VERSION ""

NS_ :

BS_:

BU_: PowertrainControlModule AtmosphericSensor SafetyRestraintSystem2 Aftertreatment_2_GasOutlet Aftertreatment_2_GasIntake DieselParticulateFilterControl Turbocharger SafetyRestraintSystem1 CabDisplay2 Aftertreatment_1_GasOutlet Aftertreatment_1_GasIntake OnBoardDataLogger OffBoardDiagnosticTool2 OffBoardDiagnosticTool1 FileServer ParkingBrakeController SeatController2 FanDriveController SteeringColumnUnit CommunicationUnitRadio CommunicationUnitSatellite CommunicationUnitCellular PropulsionBatteryCharger ChassisController2 ChassisController1 EngineValveControl AuxiliaryHeater2 AuxiliaryHeater1 ClutchUnit RampControl InformationSystem1 SuspensionSystemController2 OilSensor VehicleDynamicStability ExhaustEmissionController TransmissionDisplay2 TransmissionDisplay1 ClimateControl2 WaterPumpController RearAxleSteeringController LightingOperatorControl SeatController1 IgnitionController2 IgnitionController1 TirePressureController CabController2 CabController1 PneumaticSystemController SuspensionSystemController1 HydraulicPumpController EnduranceBrakingSystem RetarderExhaustEngine2 OnBoardDiagnosticUnit HeadwayController RetarderExhaustEngine1 CabDisplay1 ManagementComputer VirtualTerminal OffVehicleGateway PowerTakeOffFront HitchControl AuxiliaryValveControl BodyController TractorTrailerBridge1 StarterSystem ElectricalSystem VehicleSecurity VehicleNavigation AerodynamicControl ElectricalChargingSystem ClimateControl1 TripRecorder InstrumentCluster SuspensionDriveAxle2 SuspensionDriveAxle1 SuspensionSteerAxle SteeringController FuelSystem CruiseControl RetarderDriveline RetarderEngine BrakesDriveAxle2 BrakesDriveAxle1 BrakesSystemController BrakesSteerAxle AxleDrive2 AxleDrive1 AxleSteering PowerTakeOff ShiftConsoleSecondary ShiftConsolePrimary Transmission2 Transmission1 Engine2 Engine1

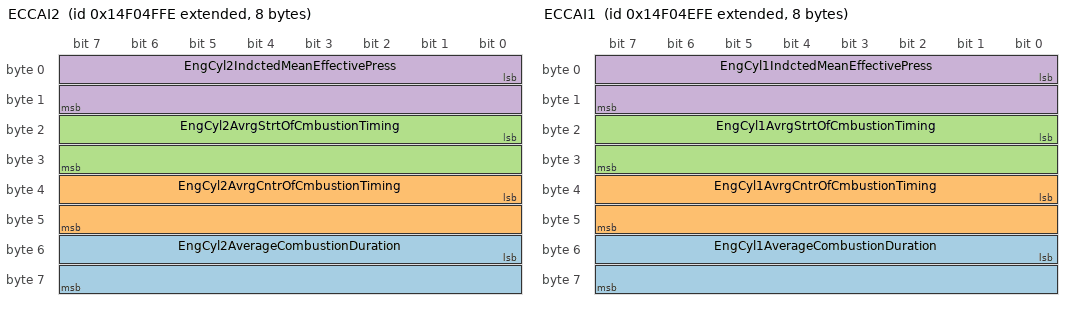
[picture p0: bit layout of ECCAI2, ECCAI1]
BO_ 2498777086 ECCAI2: 8 Vector__XXX
 SG_ EngCyl2AverageCombustionDuration : 48|16@1+ (0.0078125,0) [0|501.9921875] "deg" Vector__XXX
 SG_ EngCyl2AvrgCntrOfCmbustionTiming : 32|16@1+ (0.0078125,-250) [-250|251.9921875] "deg" Vector__XXX
 SG_ EngCyl2AvrgStrtOfCmbustionTiming : 16|16@1+ (0.0078125,-250) [-250|251.9921875] "deg" Vector__XXX
 SG_ EngCyl2IndctedMeanEffectivePress : 0|16@1+ (0.0001220703125,-1) [-1|6.8436279296875] "MPa" Vector__XXX

BO_ 2498776830 ECCAI1: 8 Vector__XXX
 SG_ EngCyl1AverageCombustionDuration : 48|16@1+ (0.0078125,0) [0|501.9921875] "deg" Vector__XXX
 SG_ EngCyl1AvrgCntrOfCmbustionTiming : 32|16@1+ (0.0078125,-250) [-250|251.9921875] "deg" Vector__XXX
 SG_ EngCyl1AvrgStrtOfCmbustionTiming : 16|16@1+ (0.0078125,-250) [-250|251.9921875] "deg" Vector__XXX
 SG_ EngCyl1IndctedMeanEffectivePress : 0|16@1+ (0.0001220703125,-1) [-1|6.8436279296875] "MPa" Vector__XXX

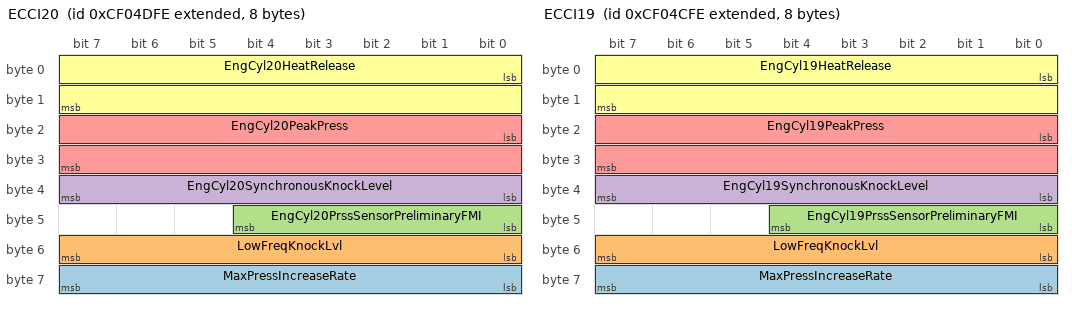
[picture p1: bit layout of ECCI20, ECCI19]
BO_ 2364558846 ECCI20: 8 Vector__XXX
 SG_ MaxPressIncreaseRate : 56|8@1+ (16,0) [0|4000] "kPa/deg" Vector__XXX
 SG_ LowFreqKnockLvl : 48|8@1+ (1,0) [0|250] "%" Vector__XXX
 SG_ EngCyl20PrssSensorPreliminaryFMI : 40|5@1+ (1,0) [0|31] "" Vector__XXX
 SG_ EngCyl20SynchronousKnockLevel : 32|8@1+ (1,0) [0|250] "%" Vector__XXX
 SG_ EngCyl20PeakPress : 16|16@1+ (0.0009765625,0) [0|62.7490234375] "MPa" Vector__XXX
 SG_ EngCyl20HeatRelease : 0|16@1+ (0.0001220703125,-1) [-1|6.8436279296875] "kJ/l" Vector__XXX

BO_ 2364558590 ECCI19: 8 Vector__XXX
 SG_ MaxPressIncreaseRate : 56|8@1+ (16,0) [0|4000] "kPa/deg" Vector__XXX
 SG_ LowFreqKnockLvl : 48|8@1+ (1,0) [0|250] "%" Vector__XXX
 SG_ EngCyl19PrssSensorPreliminaryFMI : 40|5@1+ (1,0) [0|31] "" Vector__XXX
 SG_ EngCyl19SynchronousKnockLevel : 32|8@1+ (1,0) [0|250] "%" Vector__XXX
 SG_ EngCyl19PeakPress : 16|16@1+ (0.0009765625,0) [0|62.7490234375] "MPa" Vector__XXX
 SG_ EngCyl19HeatRelease : 0|16@1+ (0.0001220703125,-1) [-1|6.8436279296875] "kJ/l" Vector__XXX

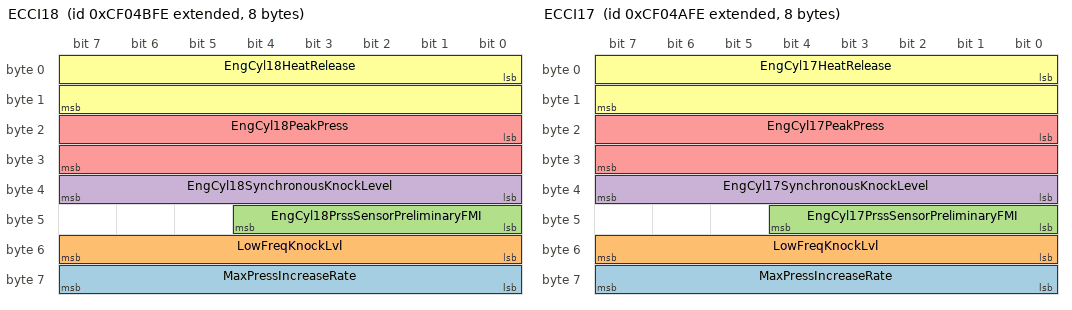
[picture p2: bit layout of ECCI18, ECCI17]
BO_ 2364558334 ECCI18: 8 Vector__XXX
 SG_ MaxPressIncreaseRate : 56|8@1+ (16,0) [0|4000] "kPa/deg" Vector__XXX
 SG_ LowFreqKnockLvl : 48|8@1+ (1,0) [0|250] "%" Vector__XXX
 SG_ EngCyl18PrssSensorPreliminaryFMI : 40|5@1+ (1,0) [0|31] "" Vector__XXX
 SG_ EngCyl18SynchronousKnockLevel : 32|8@1+ (1,0) [0|250] "%" Vector__XXX
 SG_ EngCyl18PeakPress : 16|16@1+ (0.0009765625,0) [0|62.7490234375] "MPa" Vector__XXX
 SG_ EngCyl18HeatRelease : 0|16@1+ (0.0001220703125,-1) [-1|6.8436279296875] "kJ/l" Vector__XXX

BO_ 2364558078 ECCI17: 8 Vector__XXX
 SG_ MaxPressIncreaseRate : 56|8@1+ (16,0) [0|4000] "kPa/deg" Vector__XXX
 SG_ LowFreqKnockLvl : 48|8@1+ (1,0) [0|250] "%" Vector__XXX
 SG_ EngCyl17PrssSensorPreliminaryFMI : 40|5@1+ (1,0) [0|31] "" Vector__XXX
 SG_ EngCyl17SynchronousKnockLevel : 32|8@1+ (1,0) [0|250] "%" Vector__XXX
 SG_ EngCyl17PeakPress : 16|16@1+ (0.0009765625,0) [0|62.7490234375] "MPa" Vector__XXX
 SG_ EngCyl17HeatRelease : 0|16@1+ (0.0001220703125,-1) [-1|6.8436279296875] "kJ/l" Vector__XXX

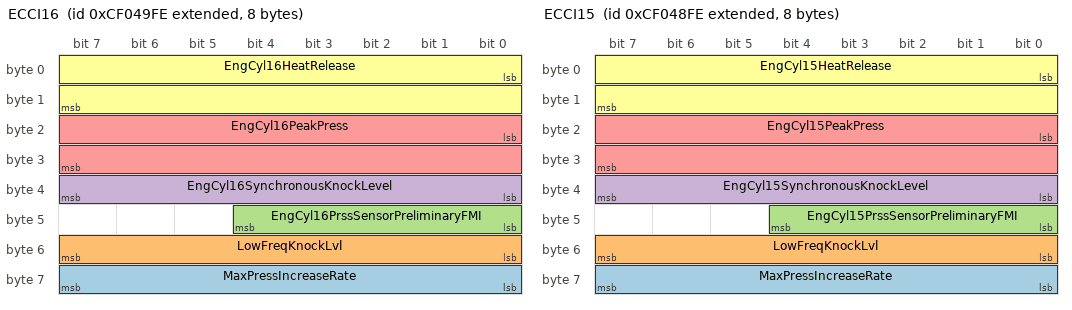
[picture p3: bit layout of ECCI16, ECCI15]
BO_ 2364557822 ECCI16: 8 Vector__XXX
 SG_ MaxPressIncreaseRate : 56|8@1+ (16,0) [0|4000] "kPa/deg" Vector__XXX
 SG_ LowFreqKnockLvl : 48|8@1+ (1,0) [0|250] "%" Vector__XXX
 SG_ EngCyl16PrssSensorPreliminaryFMI : 40|5@1+ (1,0) [0|31] "" Vector__XXX
 SG_ EngCyl16SynchronousKnockLevel : 32|8@1+ (1,0) [0|250] "%" Vector__XXX
 SG_ EngCyl16PeakPress : 16|16@1+ (0.0009765625,0) [0|62.7490234375] "MPa" Vector__XXX
 SG_ EngCyl16HeatRelease : 0|16@1+ (0.0001220703125,-1) [-1|6.8436279296875] "kJ/l" Vector__XXX

BO_ 2364557566 ECCI15: 8 Vector__XXX
 SG_ MaxPressIncreaseRate : 56|8@1+ (16,0) [0|4000] "kPa/deg" Vector__XXX
 SG_ LowFreqKnockLvl : 48|8@1+ (1,0) [0|250] "%" Vector__XXX
 SG_ EngCyl15PrssSensorPreliminaryFMI : 40|5@1+ (1,0) [0|31] "" Vector__XXX
 SG_ EngCyl15SynchronousKnockLevel : 32|8@1+ (1,0) [0|250] "%" Vector__XXX
 SG_ EngCyl15PeakPress : 16|16@1+ (0.0009765625,0) [0|62.7490234375] "MPa" Vector__XXX
 SG_ EngCyl15HeatRelease : 0|16@1+ (0.0001220703125,-1) [-1|6.8436279296875] "kJ/l" Vector__XXX

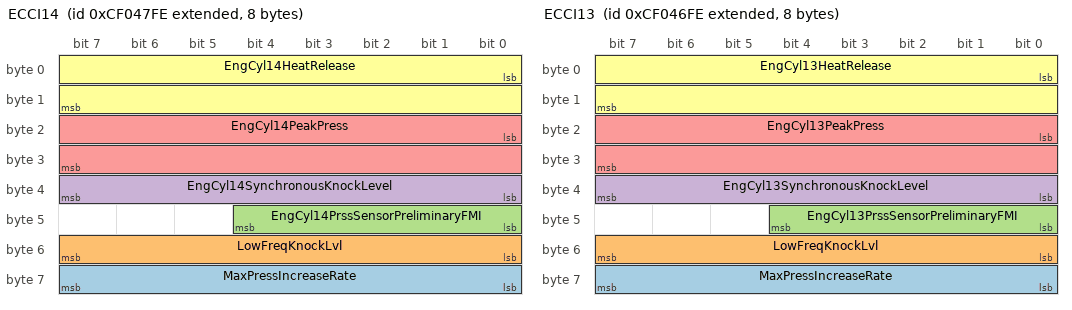
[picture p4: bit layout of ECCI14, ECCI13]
BO_ 2364557310 ECCI14: 8 Vector__XXX
 SG_ MaxPressIncreaseRate : 56|8@1+ (16,0) [0|4000] "kPa/deg" Vector__XXX
 SG_ LowFreqKnockLvl : 48|8@1+ (1,0) [0|250] "%" Vector__XXX
 SG_ EngCyl14PrssSensorPreliminaryFMI : 40|5@1+ (1,0) [0|31] "" Vector__XXX
 SG_ EngCyl14SynchronousKnockLevel : 32|8@1+ (1,0) [0|250] "%" Vector__XXX
 SG_ EngCyl14PeakPress : 16|16@1+ (0.0009765625,0) [0|62.7490234375] "MPa" Vector__XXX
 SG_ EngCyl14HeatRelease : 0|16@1+ (0.0001220703125,-1) [-1|6.8436279296875] "kJ/l" Vector__XXX

BO_ 2364557054 ECCI13: 8 Vector__XXX
 SG_ MaxPressIncreaseRate : 56|8@1+ (16,0) [0|4000] "kPa/deg" Vector__XXX
 SG_ LowFreqKnockLvl : 48|8@1+ (1,0) [0|250] "%" Vector__XXX
 SG_ EngCyl13PrssSensorPreliminaryFMI : 40|5@1+ (1,0) [0|31] "" Vector__XXX
 SG_ EngCyl13SynchronousKnockLevel : 32|8@1+ (1,0) [0|250] "%" Vector__XXX
 SG_ EngCyl13PeakPress : 16|16@1+ (0.0009765625,0) [0|62.7490234375] "MPa" Vector__XXX
 SG_ EngCyl13HeatRelease : 0|16@1+ (0.0001220703125,-1) [-1|6.8436279296875] "kJ/l" Vector__XXX

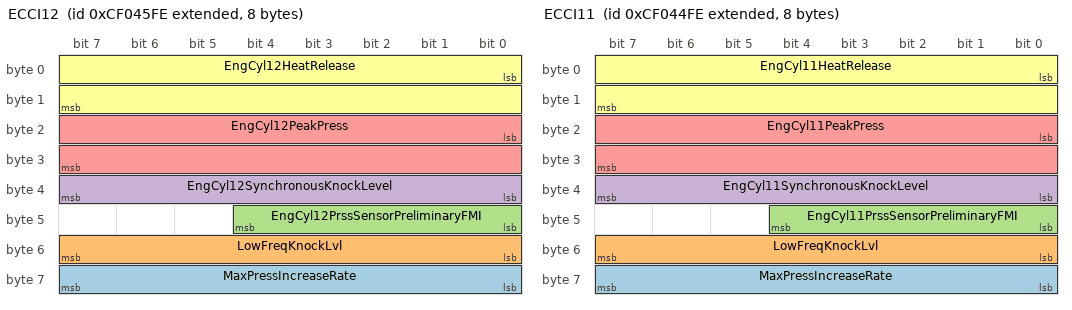
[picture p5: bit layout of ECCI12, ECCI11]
BO_ 2364556798 ECCI12: 8 Vector__XXX
 SG_ MaxPressIncreaseRate : 56|8@1+ (16,0) [0|4000] "kPa/deg" Vector__XXX
 SG_ LowFreqKnockLvl : 48|8@1+ (1,0) [0|250] "%" Vector__XXX
 SG_ EngCyl12PrssSensorPreliminaryFMI : 40|5@1+ (1,0) [0|31] "" Vector__XXX
 SG_ EngCyl12SynchronousKnockLevel : 32|8@1+ (1,0) [0|250] "%" Vector__XXX
 SG_ EngCyl12PeakPress : 16|16@1+ (0.0009765625,0) [0|62.7490234375] "MPa" Vector__XXX
 SG_ EngCyl12HeatRelease : 0|16@1+ (0.0001220703125,-1) [-1|6.8436279296875] "kJ/l" Vector__XXX

BO_ 2364556542 ECCI11: 8 Vector__XXX
 SG_ MaxPressIncreaseRate : 56|8@1+ (16,0) [0|4000] "kPa/deg" Vector__XXX
 SG_ LowFreqKnockLvl : 48|8@1+ (1,0) [0|250] "%" Vector__XXX
 SG_ EngCyl11PrssSensorPreliminaryFMI : 40|5@1+ (1,0) [0|31] "" Vector__XXX
 SG_ EngCyl11SynchronousKnockLevel : 32|8@1+ (1,0) [0|250] "%" Vector__XXX
 SG_ EngCyl11PeakPress : 16|16@1+ (0.0009765625,0) [0|62.7490234375] "MPa" Vector__XXX
 SG_ EngCyl11HeatRelease : 0|16@1+ (0.0001220703125,-1) [-1|6.8436279296875] "kJ/l" Vector__XXX

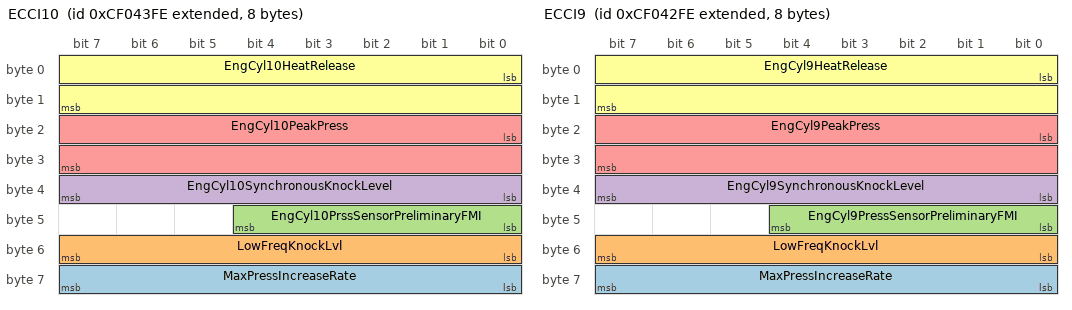
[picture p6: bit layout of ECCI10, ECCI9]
BO_ 2364556286 ECCI10: 8 Vector__XXX
 SG_ MaxPressIncreaseRate : 56|8@1+ (16,0) [0|4000] "kPa/deg" Vector__XXX
 SG_ LowFreqKnockLvl : 48|8@1+ (1,0) [0|250] "%" Vector__XXX
 SG_ EngCyl10PrssSensorPreliminaryFMI : 40|5@1+ (1,0) [0|31] "" Vector__XXX
 SG_ EngCyl10SynchronousKnockLevel : 32|8@1+ (1,0) [0|250] "%" Vector__XXX
 SG_ EngCyl10PeakPress : 16|16@1+ (0.0009765625,0) [0|62.7490234375] "MPa" Vector__XXX
 SG_ EngCyl10HeatRelease : 0|16@1+ (0.0001220703125,-1) [-1|6.8436279296875] "kJ/l" Vector__XXX

BO_ 2364556030 ECCI9: 8 Vector__XXX
 SG_ MaxPressIncreaseRate : 56|8@1+ (16,0) [0|4000] "kPa/deg" Vector__XXX
 SG_ LowFreqKnockLvl : 48|8@1+ (1,0) [0|250] "%" Vector__XXX
 SG_ EngCyl9PressSensorPreliminaryFMI : 40|5@1+ (1,0) [0|31] "" Vector__XXX
 SG_ EngCyl9SynchronousKnockLevel : 32|8@1+ (1,0) [0|250] "%" Vector__XXX
 SG_ EngCyl9PeakPress : 16|16@1+ (0.0009765625,0) [0|62.7490234375] "MPa" Vector__XXX
 SG_ EngCyl9HeatRelease : 0|16@1+ (0.0001220703125,-1) [-1|6.8436279296875] "kJ/l" Vector__XXX

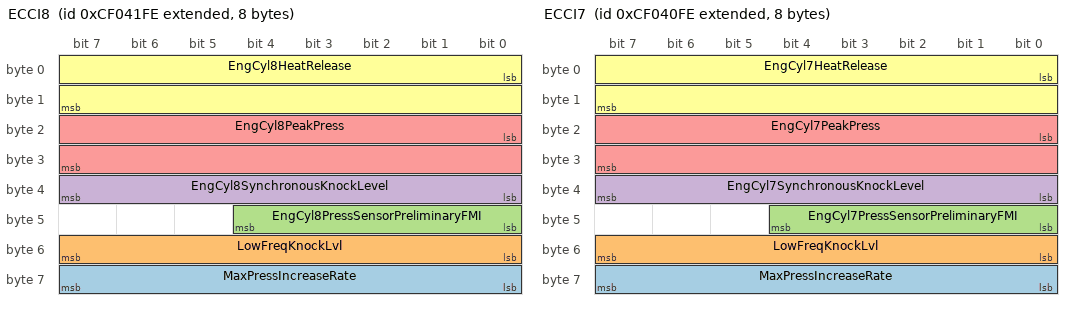
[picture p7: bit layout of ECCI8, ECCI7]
BO_ 2364555774 ECCI8: 8 Vector__XXX
 SG_ MaxPressIncreaseRate : 56|8@1+ (16,0) [0|4000] "kPa/deg" Vector__XXX
 SG_ LowFreqKnockLvl : 48|8@1+ (1,0) [0|250] "%" Vector__XXX
 SG_ EngCyl8PressSensorPreliminaryFMI : 40|5@1+ (1,0) [0|31] "" Vector__XXX
 SG_ EngCyl8SynchronousKnockLevel : 32|8@1+ (1,0) [0|250] "%" Vector__XXX
 SG_ EngCyl8PeakPress : 16|16@1+ (0.0009765625,0) [0|62.7490234375] "MPa" Vector__XXX
 SG_ EngCyl8HeatRelease : 0|16@1+ (0.0001220703125,-1) [-1|6.8436279296875] "kJ/l" Vector__XXX

BO_ 2364555518 ECCI7: 8 Vector__XXX
 SG_ MaxPressIncreaseRate : 56|8@1+ (16,0) [0|4000] "kPa/deg" Vector__XXX
 SG_ LowFreqKnockLvl : 48|8@1+ (1,0) [0|250] "%" Vector__XXX
 SG_ EngCyl7PressSensorPreliminaryFMI : 40|5@1+ (1,0) [0|31] "" Vector__XXX
 SG_ EngCyl7SynchronousKnockLevel : 32|8@1+ (1,0) [0|250] "%" Vector__XXX
 SG_ EngCyl7PeakPress : 16|16@1+ (0.0009765625,0) [0|62.7490234375] "MPa" Vector__XXX
 SG_ EngCyl7HeatRelease : 0|16@1+ (0.0001220703125,-1) [-1|6.8436279296875] "kJ/l" Vector__XXX

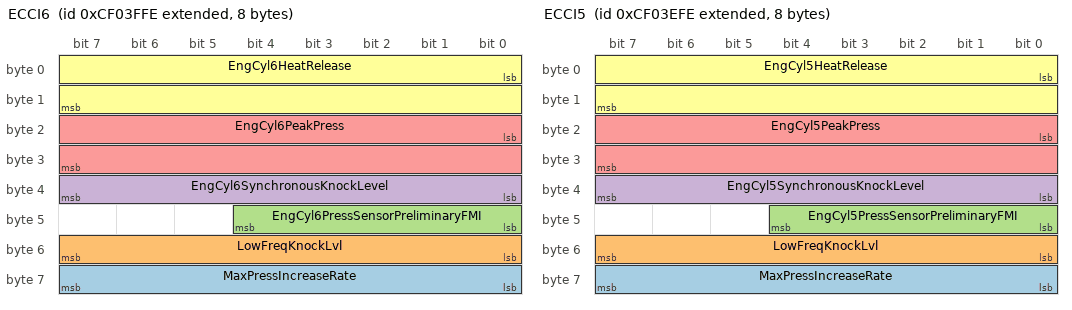
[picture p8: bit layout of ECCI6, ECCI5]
BO_ 2364555262 ECCI6: 8 Vector__XXX
 SG_ MaxPressIncreaseRate : 56|8@1+ (16,0) [0|4000] "kPa/deg" Vector__XXX
 SG_ LowFreqKnockLvl : 48|8@1+ (1,0) [0|250] "%" Vector__XXX
 SG_ EngCyl6PressSensorPreliminaryFMI : 40|5@1+ (1,0) [0|31] "" Vector__XXX
 SG_ EngCyl6SynchronousKnockLevel : 32|8@1+ (1,0) [0|250] "%" Vector__XXX
 SG_ EngCyl6PeakPress : 16|16@1+ (0.0009765625,0) [0|62.7490234375] "MPa" Vector__XXX
 SG_ EngCyl6HeatRelease : 0|16@1+ (0.0001220703125,-1) [-1|6.8436279296875] "kJ/l" Vector__XXX

BO_ 2364555006 ECCI5: 8 Vector__XXX
 SG_ MaxPressIncreaseRate : 56|8@1+ (16,0) [0|4000] "kPa/deg" Vector__XXX
 SG_ LowFreqKnockLvl : 48|8@1+ (1,0) [0|250] "%" Vector__XXX
 SG_ EngCyl5PressSensorPreliminaryFMI : 40|5@1+ (1,0) [0|31] "" Vector__XXX
 SG_ EngCyl5SynchronousKnockLevel : 32|8@1+ (1,0) [0|250] "%" Vector__XXX
 SG_ EngCyl5PeakPress : 16|16@1+ (0.0009765625,0) [0|62.7490234375] "MPa" Vector__XXX
 SG_ EngCyl5HeatRelease : 0|16@1+ (0.0001220703125,-1) [-1|6.8436279296875] "kJ/l" Vector__XXX

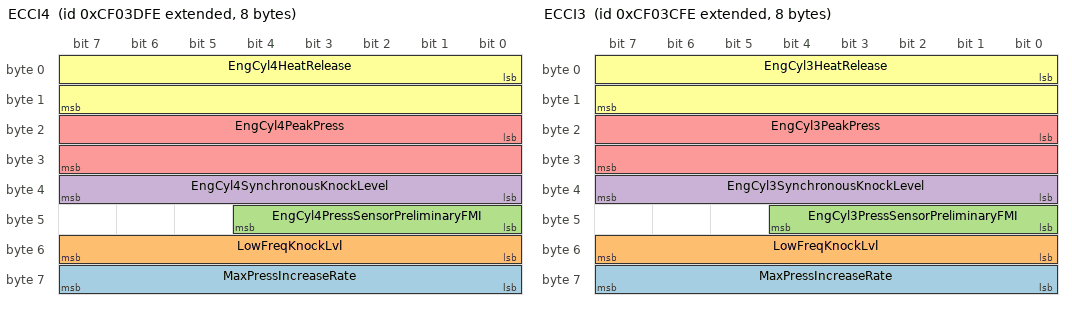
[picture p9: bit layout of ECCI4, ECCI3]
BO_ 2364554750 ECCI4: 8 Vector__XXX
 SG_ MaxPressIncreaseRate : 56|8@1+ (16,0) [0|4000] "kPa/deg" Vector__XXX
 SG_ LowFreqKnockLvl : 48|8@1+ (1,0) [0|250] "%" Vector__XXX
 SG_ EngCyl4PressSensorPreliminaryFMI : 40|5@1+ (1,0) [0|31] "" Vector__XXX
 SG_ EngCyl4SynchronousKnockLevel : 32|8@1+ (1,0) [0|250] "%" Vector__XXX
 SG_ EngCyl4PeakPress : 16|16@1+ (0.0009765625,0) [0|62.7490234375] "MPa" Vector__XXX
 SG_ EngCyl4HeatRelease : 0|16@1+ (0.0001220703125,-1) [-1|6.8436279296875] "kJ/l" Vector__XXX

BO_ 2364554494 ECCI3: 8 Vector__XXX
 SG_ MaxPressIncreaseRate : 56|8@1+ (16,0) [0|4000] "kPa/deg" Vector__XXX
 SG_ LowFreqKnockLvl : 48|8@1+ (1,0) [0|250] "%" Vector__XXX
 SG_ EngCyl3PressSensorPreliminaryFMI : 40|5@1+ (1,0) [0|31] "" Vector__XXX
 SG_ EngCyl3SynchronousKnockLevel : 32|8@1+ (1,0) [0|250] "%" Vector__XXX
 SG_ EngCyl3PeakPress : 16|16@1+ (0.0009765625,0) [0|62.7490234375] "MPa" Vector__XXX
 SG_ EngCyl3HeatRelease : 0|16@1+ (0.0001220703125,-1) [-1|6.8436279296875] "kJ/l" Vector__XXX

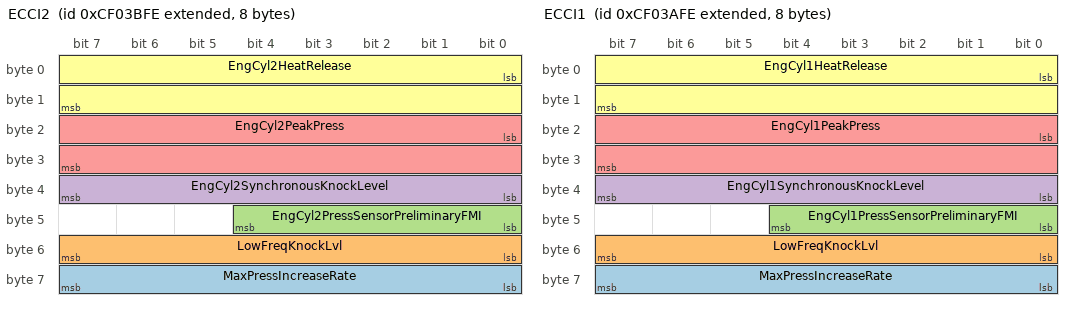
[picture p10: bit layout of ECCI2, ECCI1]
BO_ 2364554238 ECCI2: 8 Vector__XXX
 SG_ MaxPressIncreaseRate : 56|8@1+ (16,0) [0|4000] "kPa/deg" Vector__XXX
 SG_ LowFreqKnockLvl : 48|8@1+ (1,0) [0|250] "%" Vector__XXX
 SG_ EngCyl2PressSensorPreliminaryFMI : 40|5@1+ (1,0) [0|31] "" Vector__XXX
 SG_ EngCyl2SynchronousKnockLevel : 32|8@1+ (1,0) [0|250] "%" Vector__XXX
 SG_ EngCyl2PeakPress : 16|16@1+ (0.0009765625,0) [0|62.7490234375] "MPa" Vector__XXX
 SG_ EngCyl2HeatRelease : 0|16@1+ (0.0001220703125,-1) [-1|6.8436279296875] "kJ/l" Vector__XXX

BO_ 2364553982 ECCI1: 8 Vector__XXX
 SG_ MaxPressIncreaseRate : 56|8@1+ (16,0) [0|4000] "kPa/deg" Vector__XXX
 SG_ LowFreqKnockLvl : 48|8@1+ (1,0) [0|250] "%" Vector__XXX
 SG_ EngCyl1PressSensorPreliminaryFMI : 40|5@1+ (1,0) [0|31] "" Vector__XXX
 SG_ EngCyl1SynchronousKnockLevel : 32|8@1+ (1,0) [0|100] "%" Vector__XXX
 SG_ EngCyl1PeakPress : 16|16@1+ (0.0009765625,0) [0|62.7490234375] "MPa" Vector__XXX
 SG_ EngCyl1HeatRelease : 0|16@1+ (0.0001220703125,-1) [-1|6.8436279296875] "kJ/l" Vector__XXX

BO_ 2364553726 EASI: 8 Vector__XXX
 SG_ FuelSys2TotalInMassAirFlowRate : 32|16@1+ (0.0009765625,0) [0|62.7490234375] "kg/s" Vector__XXX
 SG_ EngTotalIntakeMassAirFlowRate : 16|16@1+ (0.0009765625,0) [0|62.7490234375] "kg/s" Vector__XXX
 SG_ EngDesiredAirFuelRatio : 0|16@1+ (0.001,0) [0|64.255] "" Vector__XXX

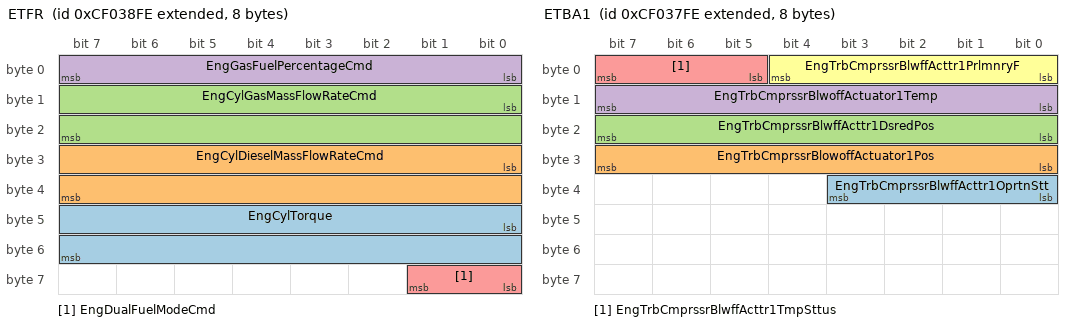
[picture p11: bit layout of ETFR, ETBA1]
BO_ 2364553470 ETFR: 8 Vector__XXX
 SG_ EngCylTorque : 40|16@1+ (1,0) [0|64255] "Nm" Vector__XXX
 SG_ EngCylDieselMassFlowRateCmd : 24|16@1+ (6.103515625E-005,0) [0|3.92181396484375] "kg/s" Vector__XXX
 SG_ EngCylGasMassFlowRateCmd : 8|16@1+ (6.103515625E-005,0) [0|3.92181396484375] "kg/s" Vector__XXX
 SG_ EngGasFuelPercentageCmd : 0|8@1+ (0.5,0) [0|100] "%" Vector__XXX
 SG_ EngDualFuelModeCmd : 56|2@1+ (1,0) [0|100] "" Vector__XXX

BO_ 2364553214 ETBA1: 8 Vector__XXX
 SG_ EngTrbCmprssrBlwffActtr1OprtnStt : 32|4@1+ (1,0) [0|15] "" Vector__XXX
 SG_ EngTrbCmprssrBlowoffActuator1Pos : 24|8@1+ (0.4,0) [0|100] "%" Vector__XXX
 SG_ EngTrbCmprssrBlwffActtr1DsredPos : 16|8@1+ (0.4,0) [0|100] "%" Vector__XXX
 SG_ EngTrbCmprssrBlwoffActuator1Temp : 8|8@1+ (1,-40) [-40|210] "°C" Vector__XXX
 SG_ EngTrbCmprssrBlwffActtr1TmpSttus : 5|3@1+ (1,0) [0|7] "" Vector__XXX
 SG_ EngTrbCmprssrBlwffActtr1PrlmnryF : 0|5@1+ (1,0) [0|31] "" Vector__XXX

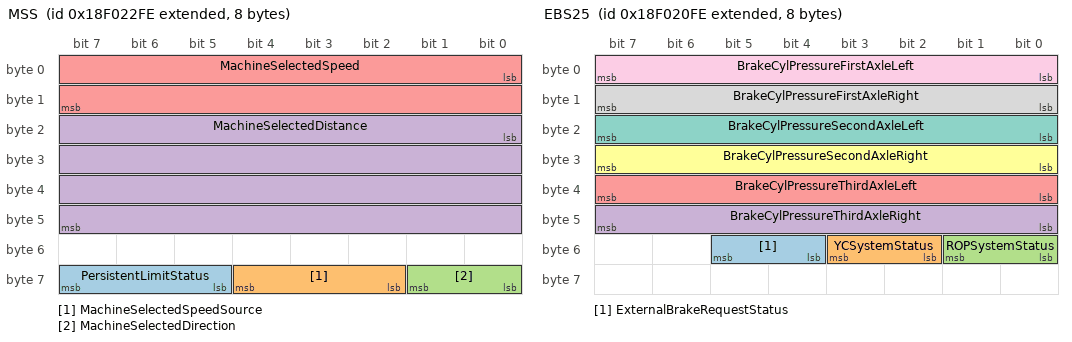
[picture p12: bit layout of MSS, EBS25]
BO_ 2565874430 MSS: 8 Vector__XXX
 SG_ PersistentLimitStatus : 61|3@1+ (1,0) [0|0] "" Vector__XXX
 SG_ MachineSelectedSpeedSource : 58|3@1+ (1,0) [0|0] "" Vector__XXX
 SG_ MachineSelectedDirection : 56|2@1+ (1,0) [0|0] "" Vector__XXX
 SG_ MachineSelectedDistance : 16|32@1+ (1,0) [0|0] "" Vector__XXX
 SG_ MachineSelectedSpeed : 0|16@1+ (1,0) [0|0] "" Vector__XXX

BO_ 2565873918 EBS25: 8 Vector__XXX
 SG_ ExternalBrakeRequestStatus : 52|2@1+ (1,0) [0|3] "" Vector__XXX
 SG_ YCSystemStatus : 50|2@1+ (1,0) [0|3] "" Vector__XXX
 SG_ ROPSystemStatus : 48|2@1+ (1,0) [0|3] "" Vector__XXX
 SG_ BrakeCylPressureThirdAxleRight : 40|8@1+ (5,0) [0|1250] "kPa" Vector__XXX
 SG_ BrakeCylPressureThirdAxleLeft : 32|8@1+ (5,0) [0|1250] "kPa" Vector__XXX
 SG_ BrakeCylPressureSecondAxleRight : 24|8@1+ (5,0) [0|1250] "kPa" Vector__XXX
 SG_ BrakeCylPressureSecondAxleLeft : 16|8@1+ (5,0) [0|1250] "kPa" Vector__XXX
 SG_ BrakeCylPressureFirstAxleRight : 8|8@1+ (5,0) [0|1250] "kPa" Vector__XXX
 SG_ BrakeCylPressureFirstAxleLeft : 0|8@1+ (5,0) [0|1250] "kPa" Vector__XXX

BO_ 2565873662 EBS26: 8 Vector__XXX
 SG_ WheelSpeedFirstAxleLeftRight : 16|16@1+ (0.00390625,0) [0|250] "km/h" Vector__XXX
 SG_ WheelSpeedFirstAxleLeft : 0|16@1+ (0.00390625,0) [0|250] "km/h" Vector__XXX

BO_ 2364546814 GC2: 8 Vector__XXX
 SG_ EngLoadSetpointReq : 24|16@1+ (0.5,0) [0|32127.5] "kW" Vector__XXX
 SG_ EngSelfInducedDerateInh : 16|2@1+ (1,0) [0|3] "" Vector__XXX
 SG_ GeneratorGoverningBias : 0|16@1+ (0.004,-125) [-125|125] "%" Vector__XXX

BO_ 2565872638 GPM17: 8 Vector__XXX
 SG_ TrailerWorkLights : 42|2@1+ (1,0) [0|3] "" Vector__XXX
 SG_ TrailerInteriorLights : 40|2@1+ (1,0) [0|3] "" Vector__XXX
 SG_ TrailerRotatingIndentLights : 38|2@1+ (1,0) [0|3] "" Vector__XXX
 SG_ TrailerRearWarningLights : 36|2@1+ (1,0) [0|3] "" Vector__XXX
 SG_ TrailerRightRearRegPlateLights : 34|2@1+ (1,0) [0|3] "" Vector__XXX
 SG_ TrailerLeftRearRegPlateLights : 32|2@1+ (1,0) [0|3] "" Vector__XXX
 SG_ TrailerRightCornerMarkerLights : 30|2@1+ (1,0) [0|3] "" Vector__XXX
 SG_ TrailerLeftCornerMarkerLights : 28|2@1+ (1,0) [0|3] "" Vector__XXX
 SG_ TrailerRightRearWidthIndLights : 26|2@1+ (1,0) [0|3] "" Vector__XXX
 SG_ TrailerLeftRearWidthIndLights : 24|2@1+ (1,0) [0|3] "" Vector__XXX
 SG_ TrailerrightSideMarkerLights : 22|2@1+ (1,0) [0|3] "" Vector__XXX
 SG_ TrailerLeftSideMarkerLights : 20|2@1+ (1,0) [0|3] "" Vector__XXX
 SG_ TrailerRightReversingLights : 18|2@1+ (1,0) [0|3] "" Vector__XXX
 SG_ TrailerLeftReversingLights : 16|2@1+ (1,0) [0|3] "" Vector__XXX
 SG_ TrailerRightRearFogLights : 14|2@1+ (1,0) [0|3] "" Vector__XXX
 SG_ TrailerLeftRearFogLights : 12|2@1+ (1,0) [0|3] "" Vector__XXX
 SG_ TrailerRightRearLights : 10|2@1+ (1,0) [0|3] "" Vector__XXX
 SG_ TrailerLeftRearLights : 8|2@1+ (1,0) [0|3] "" Vector__XXX
 SG_ TrailerRightDirIndicatorLights : 6|2@1+ (1,0) [0|3] "" Vector__XXX
 SG_ TrailerLeftDirIndicatorLights : 4|2@1+ (1,0) [0|3] "" Vector__XXX
 SG_ TrailerRightStopLights : 2|2@1+ (1,0) [0|3] "" Vector__XXX
 SG_ TrailerLeftStopLights : 0|2@1+ (1,0) [0|3] "" Vector__XXX

BO_ 2565865214 PropA: 8 Vector__XXX
 SG_ ManufacturerSpecificInformation : 0|64@1+ (1,0) [0|0] "" Vector__XXX

BO_ 2565340926 VT21: 8 Vector__XXX

BO_ 2565275390 VT12: 8 Vector__XXX

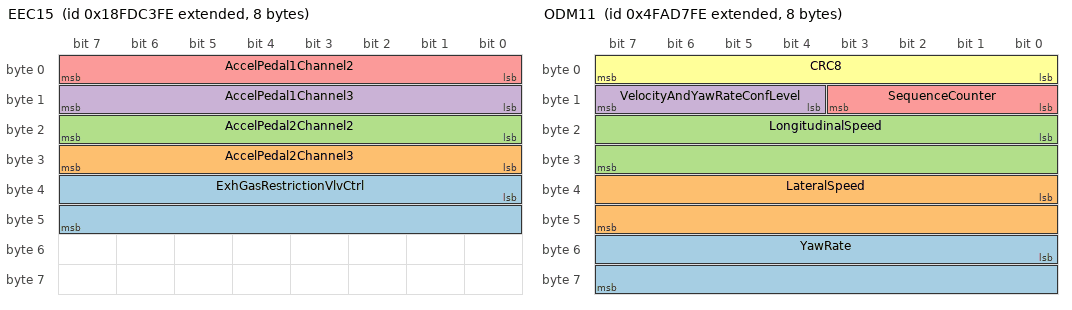
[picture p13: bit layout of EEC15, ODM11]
BO_ 2566767614 EEC15: 8 Vector__XXX
 SG_ ExhGasRestrictionVlvCtrl : 32|16@1+ (0.0025,0) [0|160.6375] "%" Vector__XXX
 SG_ AccelPedal2Channel3 : 24|8@1+ (0.4,0) [0|100] "%" Vector__XXX
 SG_ AccelPedal2Channel2 : 16|8@1+ (0.4,0) [0|100] "%" Vector__XXX
 SG_ AccelPedal1Channel3 : 8|8@1+ (0.4,0) [0|100] "%" Vector__XXX
 SG_ AccelPedal1Channel2 : 0|8@1+ (0.4,0) [0|100] "%" Vector__XXX

BO_ 2231031806 ODM11: 8 Vector__XXX
 SG_ YawRate : 48|16@1- (0.0001220703125,0) [-3.92|3.92] "rad/s" Vector__XXX
 SG_ LateralSpeed : 32|16@1- (0.01,0) [-321.28|321.27] "m/s" Vector__XXX
 SG_ LongitudinalSpeed : 16|16@1- (0.01,0) [-321.28|321.27] "m/s" Vector__XXX
 SG_ VelocityAndYawRateConfLevel : 12|4@1+ (1,0) [0|15] "" Vector__XXX
 SG_ SequenceCounter : 8|4@1+ (1,0) [0|15] "" Vector__XXX
 SG_ CRC8 : 0|8@1+ (1,0) [0|255] "" Vector__XXX

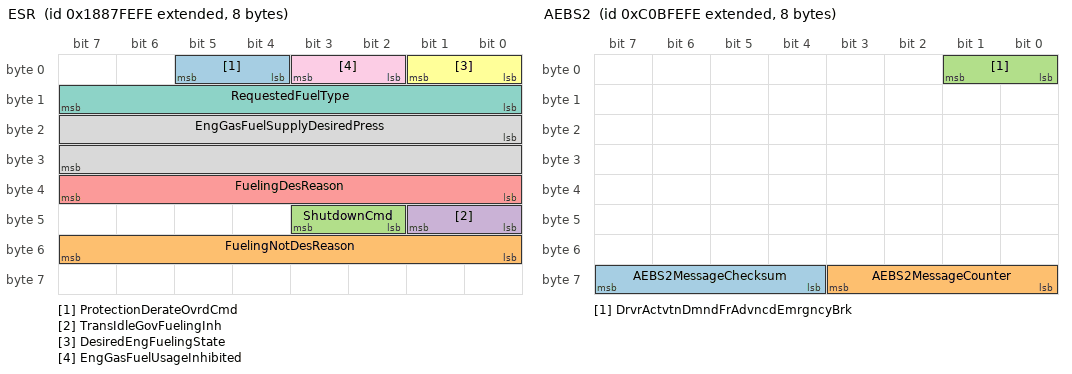
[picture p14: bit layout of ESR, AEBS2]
BO_ 2559049470 ESR: 8 Vector__XXX
 SG_ ProtectionDerateOvrdCmd : 4|2@1+ (1,0) [0|3] "" Vector__XXX
 SG_ FuelingNotDesReason : 48|8@1+ (1,0) [0|255] "" Vector__XXX
 SG_ ShutdownCmd : 42|2@1+ (1,0) [0|3] "" Vector__XXX
 SG_ TransIdleGovFuelingInh : 40|2@1+ (1,0) [0|3] "" Vector__XXX
 SG_ FuelingDesReason : 32|8@1+ (1,0) [0|255] "" Vector__XXX
 SG_ DesiredEngFuelingState : 0|2@1+ (1,0) [0|3] "" Vector__XXX
 SG_ RequestedFuelType : 8|8@1+ (1,0) [0|255] "" Vector__XXX
 SG_ EngGasFuelSupplyDesiredPress : 16|16@1+ (0.5,0) [0|32127.5] "kPa" Vector__XXX
 SG_ EngGasFuelUsageInhibited : 2|2@1+ (1,0) [0|3] "" Vector__XXX

BO_ 2349596414 AEBS2: 8 Vector__XXX
 SG_ AEBS2MessageChecksum : 60|4@1+ (1,0) [0|15] "" Vector__XXX
 SG_ AEBS2MessageCounter : 56|4@1+ (1,0) [0|15] "" Vector__XXX
 SG_ DrvrActvtnDmndFrAdvncdEmrgncyBrk : 0|2@1+ (1,0) [0|3] "" Vector__XXX

BO_ 2563702526 KWP3: 8 Vector__XXX

BO_ 2563636990 KWP4: 8 Vector__XXX

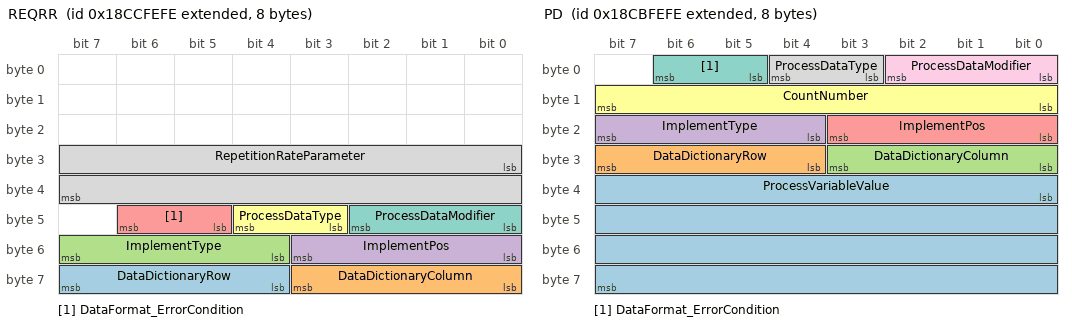
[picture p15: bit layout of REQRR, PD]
BO_ 2563571454 REQRR: 8 Vector__XXX
 SG_ DataDictionaryRow : 60|4@1+ (1,0) [0|0] "" Vector__XXX
 SG_ DataDictionaryColumn : 56|4@1+ (1,0) [0|0] "" Vector__XXX
 SG_ ImplementType : 52|4@1+ (1,0) [0|0] "" Vector__XXX
 SG_ ImplementPos : 48|4@1+ (1,0) [0|0] "" Vector__XXX
 SG_ DataFormat_ErrorCondition : 45|2@1+ (1,0) [0|0] "" Vector__XXX
 SG_ ProcessDataType : 43|2@1+ (1,0) [0|0] "" Vector__XXX
 SG_ ProcessDataModifier : 40|3@1+ (1,0) [0|0] "" Vector__XXX
 SG_ RepetitionRateParameter : 24|16@1+ (1,0) [0|0] "" Vector__XXX

BO_ 2563505918 PD: 8 Vector__XXX
 SG_ ProcessVariableValue : 32|32@1+ (1,0) [0|0] "" Vector__XXX
 SG_ DataDictionaryRow : 28|4@1+ (1,0) [0|0] "" Vector__XXX
 SG_ DataDictionaryColumn : 24|4@1+ (1,0) [0|0] "" Vector__XXX
 SG_ ImplementType : 20|4@1+ (1,0) [0|0] "" Vector__XXX
 SG_ ImplementPos : 16|4@1+ (1,0) [0|0] "" Vector__XXX
 SG_ CountNumber : 8|8@1+ (1,0) [0|0] "" Vector__XXX
 SG_ DataFormat_ErrorCondition : 5|2@1+ (1,0) [0|0] "" Vector__XXX
 SG_ ProcessDataType : 3|2@1+ (1,0) [0|0] "" Vector__XXX
 SG_ ProcessDataModifier : 0|3@1+ (1,0) [0|0] "" Vector__XXX

BO_ 2563309310 ETPCM: 8 Vector__XXX

BO_ 2563243774 ETPDT: 8 Vector__XXX

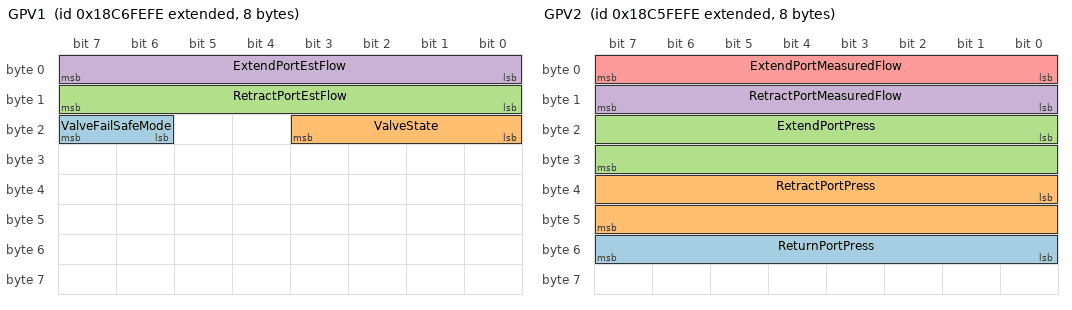
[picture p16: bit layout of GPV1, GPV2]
BO_ 2563178238 GPV1: 8 Vector__XXX
 SG_ ValveFailSafeMode : 22|2@1+ (1,0) [0|0] "" Vector__XXX
 SG_ ValveState : 16|4@1+ (1,0) [0|0] "" Vector__XXX
 SG_ RetractPortEstFlow : 8|8@1+ (1,0) [0|0] "" Vector__XXX
 SG_ ExtendPortEstFlow : 0|8@1+ (1,0) [0|0] "" Vector__XXX

BO_ 2563112702 GPV2: 8 Vector__XXX
 SG_ ReturnPortPress : 48|8@1+ (1,0) [0|0] "" Vector__XXX
 SG_ RetractPortPress : 32|16@1+ (1,0) [0|0] "" Vector__XXX
 SG_ ExtendPortPress : 16|16@1+ (1,0) [0|0] "" Vector__XXX
 SG_ RetractPortMeasuredFlow : 8|8@1+ (1,0) [0|0] "" Vector__XXX
 SG_ ExtendPortMeasuredFlow : 0|8@1+ (1,0) [0|0] "" Vector__XXX

BO_ 2563047166 GPV3: 8 Vector__XXX
 SG_ PortFlowCmd : 0|8@1+ (1,0) [0|0] "" Vector__XXX

BO_ 2562785022 PCM16: 8 Vector__XXX

BO_ 2562719486 PCM15: 8 Vector__XXX

BO_ 2562653950 PCM14: 8 Vector__XXX

BO_ 2562588414 PCM13: 8 Vector__XXX

BO_ 2562522878 PCM12: 8 Vector__XXX

BO_ 2562457342 PCM11: 8 Vector__XXX

BO_ 2562391806 PCM10: 8 Vector__XXX

BO_ 2562326270 PCM9: 8 Vector__XXX

BO_ 2562260734 PCM8: 8 Vector__XXX

BO_ 2562195198 PCM7: 8 Vector__XXX

BO_ 2562129662 PCM6: 8 Vector__XXX

BO_ 2562064126 PCM5: 8 Vector__XXX

BO_ 2561998590 PCM4: 8 Vector__XXX

BO_ 2561933054 PCM3: 8 Vector__XXX

BO_ 2561867518 PCM2: 8 Vector__XXX

BO_ 2561801982 PCM1: 8 Vector__XXX

BO_ 2561736446 CIM: 8 Vector__XXX

BO_ 2561670910 PLM: 8 Vector__XXX

BO_ 2561539838 GSC: 8 Vector__XXX

BO_ 2561474302 GMS: 8 Vector__XXX

BO_ 2561408766 FSC: 8 Vector__XXX

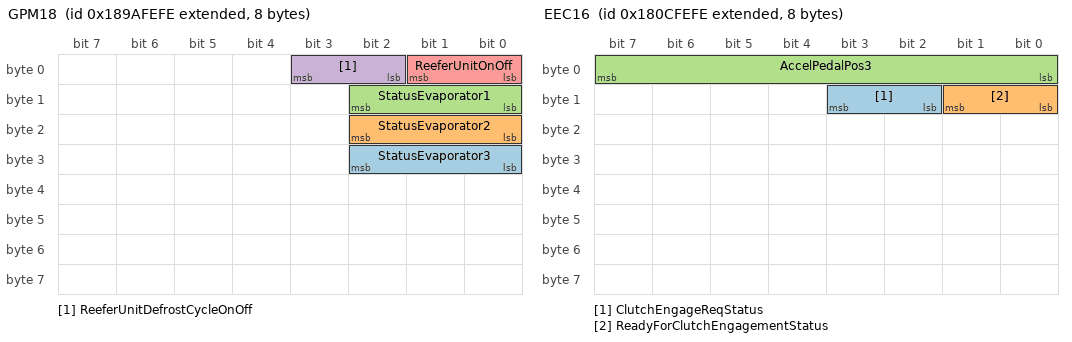
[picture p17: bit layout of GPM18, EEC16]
BO_ 2560294654 GPM18: 8 Vector__XXX
 SG_ StatusEvaporator3 : 24|3@1+ (1,0) [0|7] "" Vector__XXX
 SG_ StatusEvaporator2 : 16|3@1+ (1,0) [0|7] "" Vector__XXX
 SG_ StatusEvaporator1 : 8|3@1+ (1,0) [0|7] "" Vector__XXX
 SG_ ReeferUnitDefrostCycleOnOff : 2|2@1+ (1,0) [0|3] "" Vector__XXX
 SG_ ReeferUnitOnOff : 0|2@1+ (1,0) [0|3] "" Vector__XXX

BO_ 2559835902 NM: 8 Vector__XXX
 SG_ ErrorCode m4 : 0|8@1+ (1,0) [0|255] "" Vector__XXX
 SG_ CommandedAAC m0 : 63|1@1+ (1,0) [0|1] "" Vector__XXX
 SG_ CommandedIndustryGroup m0 : 60|3@1+ (1,0) [0|7] "" Vector__XXX
 SG_ CommandedVehicleSystemInstance m0 : 56|4@1+ (1,0) [0|15] "" Vector__XXX
 SG_ CommandedVehicleSystem m0 : 49|7@1+ (1,0) [0|126] "" Vector__XXX
 SG_ CommandedFunction m0 : 40|8@1+ (1,0) [0|254] "" Vector__XXX
 SG_ CommandedFunctionInstance m0 : 35|5@1+ (1,0) [0|31] "" Vector__XXX
 SG_ CommandedECUInstance m0 : 32|3@1+ (1,0) [0|7] "" Vector__XXX
 SG_ CommandedManufacturerCode m0 : 21|11@1+ (1,0) [0|2047] "" Vector__XXX
 SG_ NMControlModeIndicator M : 16|4@1+ (1,0) [0|15] "" Vector__XXX
 SG_ AACQualifierFlag m0 : 15|1@1+ (1,0) [0|1] "" Vector__XXX
 SG_ IndustryGroupQualifierFlag m0 : 14|1@1+ (1,0) [0|1] "" Vector__XXX
 SG_ VehicleSystemInstanceQualifFlag m0 : 13|1@1+ (1,0) [0|1] "" Vector__XXX
 SG_ VehicleSystemQualifierFlag m0 : 12|1@1+ (1,0) [0|1] "" Vector__XXX
 SG_ FunctionQualifierFlag m0 : 11|1@1+ (1,0) [0|1] "" Vector__XXX
 SG_ FunctionInstanceQualifierFlag m0 : 10|1@1+ (1,0) [0|1] "" Vector__XXX
 SG_ ECUInstanceQualifierFlag m0 : 9|1@1+ (1,0) [0|1] "" Vector__XXX
 SG_ ManufacturerCodeQualifierFlag m0 : 8|1@1+ (1,0) [0|1] "" Vector__XXX
 SG_ NAMEChecksum m0 : 0|8@1+ (1,0) [0|255] "" Vector__XXX

BO_ 2559508222 SCMCC: 8 Vector__XXX

BO_ 2559442686 SCCCM: 8 Vector__XXX

BO_ 2559377150 CCP_CRO: 8 Vector__XXX

BO_ 2559311614 CCP_DTO: 8 Vector__XXX

BO_ 2558983934 SPOC: 8 Vector__XXX
 SG_ SwitchedPowerOutput18Cmd : 36|2@1+ (1,0) [0|3] "" Vector__XXX
 SG_ SwitchedPowerOutput19Cmd : 34|2@1+ (1,0) [0|3] "" Vector__XXX
 SG_ SwitchedPowerOutput20Cmd : 32|2@1+ (1,0) [0|3] "" Vector__XXX
 SG_ SwitchedPowerOutput13Cmd : 30|2@1+ (1,0) [0|3] "" Vector__XXX
 SG_ SwitchedPowerOutput14Cmd : 28|2@1+ (1,0) [0|3] "" Vector__XXX
 SG_ SwitchedPowerOutput15Cmd : 26|2@1+ (1,0) [0|3] "" Vector__XXX
 SG_ SwitchedPowerOutput16Cmd : 24|2@1+ (1,0) [0|3] "" Vector__XXX
 SG_ SwitchedPowerOutput9Cmd : 22|2@1+ (1,0) [0|3] "" Vector__XXX
 SG_ SwitchedPowerOutput10Cmd : 20|2@1+ (1,0) [0|3] "" Vector__XXX
 SG_ SwitchedPowerOutput29Cmd : 62|2@1+ (1,0) [0|3] "" Vector__XXX
 SG_ SwitchedPowerOutput30Cmd : 60|2@1+ (1,0) [0|3] "" Vector__XXX
 SG_ SwitchedPowerOutput31Cmd : 58|2@1+ (1,0) [0|3] "" Vector__XXX
 SG_ SwitchedPowerOutput32Cmd : 56|2@1+ (1,0) [0|3] "" Vector__XXX
 SG_ SwitchedPowerOutput25Cmd : 54|2@1+ (1,0) [0|3] "" Vector__XXX
 SG_ SwitchedPowerOutput26Cmd : 52|2@1+ (1,0) [0|3] "" Vector__XXX
 SG_ SwitchedPowerOutput27Cmd : 50|2@1+ (1,0) [0|3] "" Vector__XXX
 SG_ SwitchedPowerOutput28Cmd : 48|2@1+ (1,0) [0|3] "" Vector__XXX
 SG_ SwitchedPowerOutput21Cmd : 46|2@1+ (1,0) [0|3] "" Vector__XXX
 SG_ SwitchedPowerOutput22Cmd : 44|2@1+ (1,0) [0|3] "" Vector__XXX
 SG_ SwitchedPowerOutput23Cmd : 42|2@1+ (1,0) [0|3] "" Vector__XXX
 SG_ SwitchedPowerOutput24Cmd : 40|2@1+ (1,0) [0|3] "" Vector__XXX
 SG_ SwitchedPowerOutput17Cmd : 38|2@1+ (1,0) [0|3] "" Vector__XXX
 SG_ SwitchedPowerOutput11Cmd : 18|2@1+ (1,0) [0|3] "" Vector__XXX
 SG_ SwitchedPowerOutput12Cmd : 16|2@1+ (1,0) [0|3] "" Vector__XXX
 SG_ SwitchedPowerOutput5Cmd : 14|2@1+ (1,0) [0|3] "" Vector__XXX
 SG_ SwitchedPowerOutput6Cmd : 12|2@1+ (1,0) [0|3] "" Vector__XXX
 SG_ SwitchedPowerOutput7Cmd : 10|2@1+ (1,0) [0|3] "" Vector__XXX
 SG_ SwitchedPowerOutput8Cmd : 8|2@1+ (1,0) [0|3] "" Vector__XXX
 SG_ SwitchedPowerOutput1Cmd : 6|2@1+ (1,0) [0|3] "" Vector__XXX
 SG_ SwitchedPowerOutput2Cmd : 4|2@1+ (1,0) [0|3] "" Vector__XXX
 SG_ SwitchedPowerOutput3Cmd : 2|2@1+ (1,0) [0|3] "" Vector__XXX
 SG_ SwitchedPowerOutput4Cmd : 0|2@1+ (1,0) [0|3] "" Vector__XXX

BO_ 2349727486 TC2: 8 Vector__XXX
 SG_ CoastModeDisReq : 36|2@1+ (1,0) [0|3] "" Vector__XXX
 SG_ DisengageDiffLockReqRearAxle3 : 34|2@1+ (1,0) [0|3] "" Vector__XXX
 SG_ Mode20 : 32|2@1+ (1,0) [0|3] "" Vector__XXX
 SG_ Mode19 : 30|2@1+ (1,0) [0|3] "" Vector__XXX
 SG_ Mode18 : 28|2@1+ (1,0) [0|3] "" Vector__XXX
 SG_ Mode17 : 26|2@1+ (1,0) [0|3] "" Vector__XXX
 SG_ Mode16 : 24|2@1+ (1,0) [0|3] "" Vector__XXX
 SG_ Mode15 : 22|2@1+ (1,0) [0|3] "" Vector__XXX
 SG_ Mode14 : 20|2@1+ (1,0) [0|3] "" Vector__XXX
 SG_ Mode13 : 18|2@1+ (1,0) [0|3] "" Vector__XXX
 SG_ Mode12 : 16|2@1+ (1,0) [0|3] "" Vector__XXX
 SG_ Mode11 : 14|2@1+ (1,0) [0|3] "" Vector__XXX
 SG_ SelectedMaxGearLmtActReq : 12|2@1+ (1,0) [0|3] "" Vector__XXX
 SG_ ReqReverseLaunchGear : 8|4@1+ (1,0) [0|15] "" Vector__XXX
 SG_ OutShaftBrkReq : 6|2@1+ (1,0) [0|3] "" Vector__XXX
 SG_ PreDefinedMaxGearActReq : 4|2@1+ (1,0) [0|3] "" Vector__XXX
 SG_ TransMode10 : 2|2@1+ (1,0) [0|3] "" Vector__XXX
 SG_ TransMode9 : 0|2@1+ (1,0) [0|3] "" Vector__XXX

BO_ 2550988542 EEC16: 8 Vector__XXX
 SG_ ClutchEngageReqStatus : 10|2@1+ (1,0) [0|3] "" Vector__XXX
 SG_ ReadyForClutchEngagementStatus : 8|2@1+ (1,0) [0|3] "" Vector__XXX
 SG_ AccelPedalPos3 : 0|8@1+ (0.4,0) [0|100] "%" Vector__XXX

BO_ 2550595326 CAM21: 8 Vector__XXX

BO_ 2550529790 CAM11: 8 Vector__XXX

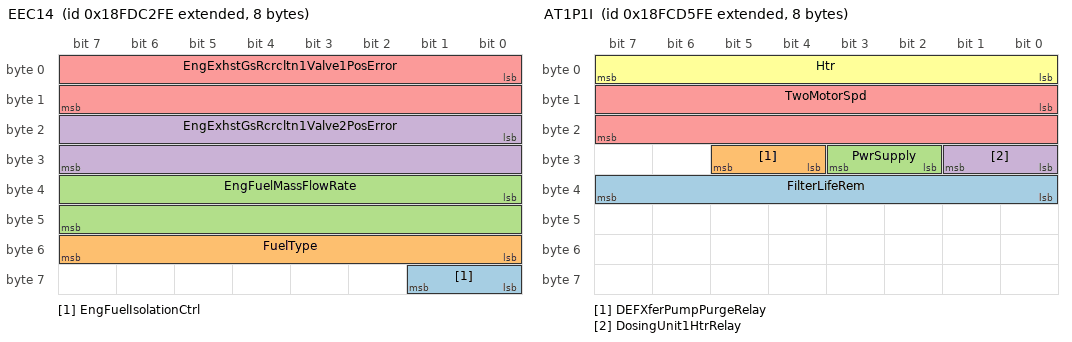
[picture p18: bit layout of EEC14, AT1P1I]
BO_ 2566767358 EEC14: 8 Vector__XXX
 SG_ EngFuelIsolationCtrl : 56|2@1+ (1,0) [0|3] "" Vector__XXX
 SG_ FuelType : 48|8@1+ (1,0) [0|255] "" Vector__XXX
 SG_ EngFuelMassFlowRate : 32|16@1+ (0.005,0) [0|321.275] "g/s" Vector__XXX
 SG_ EngExhstGsRcrcltn1Valve2PosError : 16|16@1+ (0.004,-125) [-125|132.02] "%" Vector__XXX
 SG_ EngExhstGsRcrcltn1Valve1PosError : 0|16@1+ (0.004,-125) [-125|132.02] "%" Vector__XXX

BO_ 2566706686 AT1P1I: 8 Vector__XXX
 SG_ FilterLifeRem : 32|8@1+ (0.4,0) [0|100] "%" Vector__XXX
 SG_ DEFXferPumpPurgeRelay : 28|2@1+ (1,0) [0|3] "" Vector__XXX
 SG_ PwrSupply : 26|2@1+ (1,0) [0|3] "" Vector__XXX
 SG_ DosingUnit1HtrRelay : 24|2@1+ (1,0) [0|3] "" Vector__XXX
 SG_ TwoMotorSpd : 8|16@1+ (0.5,0) [0|32127.5] "rpm" Vector__XXX
 SG_ Htr : 0|8@1+ (0.4,0) [0|100] "%" Vector__XXX

BO_ 2566705406 EPSI: 8 Vector__XXX
 SG_ A1ParticulateSnsrCur : 32|16@1+ (0.00390625,0) [0|127] "µA" Vector__XXX
 SG_ A2ParticulateSnsr : 16|16@1+ (0.0125,0) [0|803.1875] "mg/m³" Vector__XXX
 SG_ A1ParticulateSnsr : 0|16@1+ (0.0125,0) [0|803.1875] "mg/m³" Vector__XXX

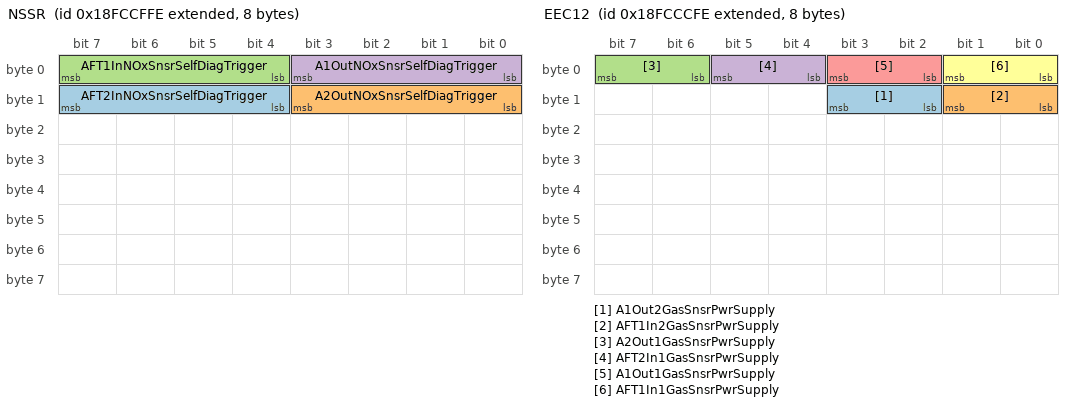
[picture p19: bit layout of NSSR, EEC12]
BO_ 2566705150 NSSR: 8 Vector__XXX
 SG_ AFT2InNOxSnsrSelfDiagTrigger : 12|4@1+ (1,0) [0|15] "" Vector__XXX
 SG_ A2OutNOxSnsrSelfDiagTrigger : 8|4@1+ (1,0) [0|15] "" Vector__XXX
 SG_ AFT1InNOxSnsrSelfDiagTrigger : 4|4@1+ (1,0) [0|15] "" Vector__XXX
 SG_ A1OutNOxSnsrSelfDiagTrigger : 0|4@1+ (1,0) [0|15] "" Vector__XXX

BO_ 2566704382 EEC12: 8 Vector__XXX
 SG_ A1Out2GasSnsrPwrSupply : 10|2@1+ (1,0) [0|3] "" Vector__XXX
 SG_ AFT1In2GasSnsrPwrSupply : 8|2@1+ (1,0) [0|3] "" Vector__XXX
 SG_ A2Out1GasSnsrPwrSupply : 6|2@1+ (1,0) [0|3] "" Vector__XXX
 SG_ AFT2In1GasSnsrPwrSupply : 4|2@1+ (1,0) [0|3] "" Vector__XXX
 SG_ A1Out1GasSnsrPwrSupply : 2|2@1+ (1,0) [0|3] "" Vector__XXX
 SG_ AFT1In1GasSnsrPwrSupply : 0|2@1+ (1,0) [0|3] "" Vector__XXX

CM_ BO_ 2498777086 "Engine Cylinder 2 Combustion Average Information
Used to transmit the average of combustion parameters of Engine Cylinder 2.
This PG is transmitted at a defined ratio of the engine speed. The transmission rate is dependent on
SPN 6394 - Number of ...";
CM_ SG_ 2498777086 EngCyl2AverageCombustionDuration "Average duration of combustion calculated over defined number of combustion cycles for engine cylinder 2 with reference to the crank angle.  Combustion duration is the difference between end of combustion and start of combustion expressed, in this ...";
CM_ SG_ 2498777086 EngCyl2AvrgCntrOfCmbustionTiming "Average timing calculated over defined number of combustion cycles for the center of combustion in engine cylinder 2 with reference to the crank angle.  Center of Combustion is used to indicate the combustion efficiency.  When the combustion happens ...";
CM_ SG_ 2498777086 EngCyl2AvrgStrtOfCmbustionTiming "Average start of combustion timing calculated over defined number of combustion cycles for engine cylinder 2 with reference to the crank angle.  When the combustion happens after the TDC (Top Dead Center) of this cylinder, the timing is referred in ...";
CM_ SG_ 2498777086 EngCyl2IndctedMeanEffectivePress "Average cylinder pressure calculated over defined number of combustion cycles for engine cylinder 2.  Negative range is to cover thermodynamic behavior during misfire.";
CM_ BO_ 2498776830 "Engine Cylinder 1 Combustion Average Information
Used to transmit the average of combustion parameters of Engine Cylinder 1.
This PG is transmitted at a defined ratio of the engine speed. The transmission rate is dependent on
SPN 6394 - Number of ...";
CM_ SG_ 2498776830 EngCyl1AverageCombustionDuration "Average duration of combustion calculated over defined number of combustion cycles for engine cylinder 1 with reference to the crank angle.  Combustion duration is the difference between end of combustion and start of combustion expressed, in this ...";
CM_ SG_ 2498776830 EngCyl1AvrgCntrOfCmbustionTiming "Average timing calculated over defined number of combustion cycles for the center of combustion in engine cylinder 1 with reference to the crank angle.  Center of Combustion is used to indicate the combustion efficiency.  When the combustion happens ...";
CM_ SG_ 2498776830 EngCyl1AvrgStrtOfCmbustionTiming "Average start of combustion timing calculated over defined number of combustion cycles for engine cylinder 1 with reference to the crank angle.  When the combustion happens after the TDC (Top Dead Center) of this cylinder, the timing is referred in ...";
CM_ SG_ 2498776830 EngCyl1IndctedMeanEffectivePress "Average cylinder pressure calculated over defined number of combustion cycles for engine cylinder 1.   Negative range is to cover thermodynamic behavior during misfire.";
CM_ BO_ 2364558846 "Engine Cylinder 20 Combustion Information
Used to communicate combustion information of Engine Cylinder 20. The PG is transmitted at the end of every combustion in Cylinder 20.";
CM_ SG_ 2364558846 MaxPressIncreaseRate "The maximum slope, in degrees of crank angle, of the pressure increase in engine cylinder 20 during the combustion cycle.";
CM_ SG_ 2364558846 LowFreqKnockLvl "Indicates the level of low frequency knock for engine cylinder 20. This knock occurs at frequencies below the typical knock level reported on SPNs 1371 & 6474.  The level of low frequency knock is reported using a relative scale where 0% is least ...";
CM_ SG_ 2364558846 EngCyl20PrssSensorPreliminaryFMI "Used to identify the applicable J1939-73 FMI detected in the engine cylinder 20 pressure sensor.  In the case of multiple failures the most severe is communicated.
A value of 31 is sent to indicate that no failure has been detected or this ...";
CM_ SG_ 2364558846 EngCyl20SynchronousKnockLevel "Used to indicate the level of knock for engine cylinder 20. The level of knock is reported using a relative scale where 0% is least level of knock, and increasing levels indicate more knock until 100% indicates the most severe level of knock allowed ...";
CM_ SG_ 2364558846 EngCyl20PeakPress "Peak pressure in engine cylinder 20 in combustion cycle.";
CM_ SG_ 2364558846 EngCyl20HeatRelease "The amount of heat produced during combustion in engine cylinder 20.  The negative range is to cover thermodynamic behavior during misfire.";
CM_ BO_ 2364558590 "Engine Cylinder 19 Combustion Information
Used to communicate combustion information of Engine Cylinder 19. The PG is transmitted at the end of every combustion in Cylinder 19.";
CM_ SG_ 2364558590 MaxPressIncreaseRate "The maximum slope, in degrees of crank angle, of the pressure increase in engine cylinder 19 during the combustion cycle.";
CM_ SG_ 2364558590 LowFreqKnockLvl "Indicates the level of low frequency knock for engine cylinder 19. This knock occurs at frequencies below the typical knock level reported on SPNs 1370 & 6470.  The level of low frequency knock is reported using a relative scale where 0% is least ...";
CM_ SG_ 2364558590 EngCyl19PrssSensorPreliminaryFMI "Used to identify the applicable J1939-73 FMI detected in the engine cylinder 19 pressure sensor.  In the case of multiple failures the most severe is communicated.
A value of 31 is sent to indicate that no failure has been detected or this ...";
CM_ SG_ 2364558590 EngCyl19SynchronousKnockLevel "Used to indicate the level of knock for engine cylinder 19. The level of knock is reported using a relative scale where 0% is least level of knock, and increasing levels indicate more knock until 100% indicates the most severe level of knock allowed ...";
CM_ SG_ 2364558590 EngCyl19PeakPress "Peak pressure in engine cylinder 19 in combustion cycle.";
CM_ SG_ 2364558590 EngCyl19HeatRelease "The amount of heat produced during combustion in engine cylinder 19.  The negative range is to cover thermodynamic behavior during misfire.";
CM_ BO_ 2364558334 "Engine Cylinder 18 Combustion Information
Used to communicate combustion information of Engine Cylinder 18. The PG is transmitted at the end of every combustion in Cylinder 18.";
CM_ SG_ 2364558334 MaxPressIncreaseRate "The maximum slope, in degrees of crank angle, of the pressure increase in engine cylinder 18 during the combustion cycle.";
CM_ SG_ 2364558334 LowFreqKnockLvl "Indicates the level of low frequency knock for engine cylinder 18. This knock occurs at frequencies below the typical knock level reported on SPNs 1369 & 6466.  The level of low frequency knock is reported using a relative scale where 0% is least ...";
CM_ SG_ 2364558334 EngCyl18PrssSensorPreliminaryFMI "Used to identify the applicable J1939-73 FMI detected in the engine cylinder 18 pressure sensor. In the case of multiple failures the most severe is communicated.
A value of 31 is sent to indicate that no failure has been detected or this parameter ...";
CM_ SG_ 2364558334 EngCyl18SynchronousKnockLevel "Used to indicate the level of knock for engine cylinder 18. The level of knock is reported using a relative scale where 0% is least level of knock, and increasing levels indicate more knock until 100% indicates the most severe level of knock allowed ...";
CM_ SG_ 2364558334 EngCyl18PeakPress "Peak pressure in engine cylinder 18 in combustion cycle.";
CM_ SG_ 2364558334 EngCyl18HeatRelease "The amount of heat produced during combustion in engine cylinder 18.  The negative range is to cover thermodynamic behavior during misfire.";
CM_ BO_ 2364558078 "Engine Cylinder 17 Combustion Information
Used to communicate combustion information of Engine Cylinder 17. The PG is transmitted at the end of every combustion in Cylinder 17.";
CM_ SG_ 2364558078 MaxPressIncreaseRate "The maximum slope, in degrees of crank angle, of the pressure increase in engine cylinder 17 during the combustion cycle.";
CM_ SG_ 2364558078 LowFreqKnockLvl "Indicates the level of low frequency knock for engine cylinder 17. This knock occurs at frequencies below the typical knock level reported on SPNs 1368 & 6462.  The level of low frequency knock is reported using a relative scale where 0% is least ...";
CM_ SG_ 2364558078 EngCyl17PrssSensorPreliminaryFMI "Used to identify the applicable J1939-73 FMI detected in the engine cylinder 17 pressure sensor.  In the case of multiple failures the most severe is communicated.
A value of 31 is sent to indicate that no failure has been detected or this ...";
CM_ SG_ 2364558078 EngCyl17SynchronousKnockLevel "Used to indicate the level of knock for engine cylinder 17. The level of knock is reported using a relative scale where 0% is least level of knock, and increasing levels indicate more knock until 100% indicates the most severe level of knock allowed ...";
CM_ SG_ 2364558078 EngCyl17PeakPress "Peak pressure in engine cylinder 17 in combustion cycle.";
CM_ SG_ 2364558078 EngCyl17HeatRelease "The amount of heat produced during combustion in engine cylinder 17.  The negative range is to cover thermodynamic behavior during misfire.";
CM_ BO_ 2364557822 "Engine Cylinder 16 Combustion Information
Used to communicate combustion information of Engine Cylinder 16. The PG is transmitted at the end of every combustion in Cylinder 16.";
CM_ SG_ 2364557822 MaxPressIncreaseRate "The maximum slope, in degrees of crank angle, of the pressure increase in engine cylinder 16 during the combustion cycle.";
CM_ SG_ 2364557822 LowFreqKnockLvl "Indicates the level of low frequency knock for engine cylinder 16. This knock occurs at frequencies below the typical knock level reported on SPNs 1367 & 6458.  The level of low frequency knock is reported using a relative scale where 0% is least ...";
CM_ SG_ 2364557822 EngCyl16PrssSensorPreliminaryFMI "Used to identify the applicable J1939-73 FMI detected in the engine cylinder 16 pressure sensor.  In the case of multiple failures the most severe is communicated.
A value of 31 is sent to indicate that no failure has been detected or this ...";
CM_ SG_ 2364557822 EngCyl16SynchronousKnockLevel "Used to indicate the level of knock for engine cylinder 16. The level of knock is reported using a relative scale where 0% is least level of knock, and increasing levels indicate more knock until 100% indicates the most severe level of knock allowed ...";
CM_ SG_ 2364557822 EngCyl16PeakPress "Peak pressure in engine cylinder 16 in combustion cycle.";
CM_ SG_ 2364557822 EngCyl16HeatRelease "The amount of heat produced during combustion in engine cylinder 16.  The negative range is to cover thermodynamic behavior during misfire.";
CM_ BO_ 2364557566 "Engine Cylinder 15 Combustion Information
Used to communicate combustion information of Engine Cylinder 15. The PG is transmitted at the end of every combustion in Cylinder 15.";
CM_ SG_ 2364557566 MaxPressIncreaseRate "The maximum slope, in degrees of crank angle, of the pressure increase in engine cylinder 15 during the combustion cycle.";
CM_ SG_ 2364557566 LowFreqKnockLvl "Indicates the level of low frequency knock for engine cylinder 15. This knock occurs at frequencies below the typical knock level reported on SPNs 1366 & 6454.  The level of low frequency knock is reported using a relative scale where 0% is least ...";
CM_ SG_ 2364557566 EngCyl15PrssSensorPreliminaryFMI "Used to identify the applicable J1939-73 FMI detected in the engine cylinder 15 pressure sensor.  In the case of multiple failures the most severe is communicated.
A value of 31 is sent to indicate that no failure has been detected or this ...";
CM_ SG_ 2364557566 EngCyl15SynchronousKnockLevel "Used to indicate the level of knock for engine cylinder 15. The level of knock is reported using a relative scale where 0% is least level of knock, and increasing levels indicate more knock until 100% indicates the most severe level of knock allowed ...";
CM_ SG_ 2364557566 EngCyl15PeakPress "Peak pressure in engine cylinder 15 in combustion cycle.";
CM_ SG_ 2364557566 EngCyl15HeatRelease "The amount of heat produced during combustion in engine cylinder 15.  The negative range is to cover thermodynamic behavior during misfire.";
CM_ BO_ 2364557310 "Engine Cylinder 14 Combustion Information
Used to communicate combustion information of Engine Cylinder 14. The PG is transmitted at the end of every combustion in Cylinder 14.";
CM_ SG_ 2364557310 MaxPressIncreaseRate "The maximum slope, in degrees of crank angle, of the pressure increase in engine cylinder 14 during the combustion cycle.";
CM_ SG_ 2364557310 LowFreqKnockLvl "Indicates the level of low frequency knock for engine cylinder 14. This knock occurs at frequencies below the typical knock level reported on SPNs 1365 & 6450.  The level of low frequency knock is reported using a relative scale where 0% is least ...";
CM_ SG_ 2364557310 EngCyl14PrssSensorPreliminaryFMI "Used to identify the applicable J1939-73 FMI detected in the engine cylinder 14 pressure sensor.  In the case of multiple failures the most severe is communicated.
A value of 31 is sent to indicate that no failure has been detected or this ...";
CM_ SG_ 2364557310 EngCyl14SynchronousKnockLevel "Used to indicate the level of knock for engine cylinder 14. The level of knock is reported using a relative scale where 0% is least level of knock, and increasing levels indicate more knock until 100% indicates the most severe level of knock allowed ...";
CM_ SG_ 2364557310 EngCyl14PeakPress "Peak pressure in engine cylinder 14 in combustion cycle.";
CM_ SG_ 2364557310 EngCyl14HeatRelease "The amount of heat produced during combustion in engine cylinder 14.  The negative range is to cover thermodynamic behavior during misfire.";
CM_ BO_ 2364557054 "Engine Cylinder 13 Combustion Information
Used to communicate combustion information of Engine Cylinder 13. The PG is transmitted at the end of every combustion in Cylinder 13.";
CM_ SG_ 2364557054 MaxPressIncreaseRate "The maximum slope, in degrees of crank angle, of the pressure increase in engine cylinder 13 during the combustion cycle.";
CM_ SG_ 2364557054 LowFreqKnockLvl "Indicates the level of low frequency knock for engine cylinder 13. This knock occurs at frequencies below the typical knock level reported on SPNs 1364 & 6446.  The level of low frequency knock is reported using a relative scale where 0% is least ...";
CM_ SG_ 2364557054 EngCyl13PrssSensorPreliminaryFMI "Used to identify the applicable J1939-73 FMI detected in the engine cylinder 13 pressure sensor.  In the case of multiple failures the most severe is communicated.
A value of 31 is sent to indicate that no failure has been detected or this ...";
CM_ SG_ 2364557054 EngCyl13SynchronousKnockLevel "Used to indicate the level of knock for engine cylinder 13. The level of knock is reported using a relative scale where 0% is least level of knock, and increasing levels indicate more knock until 100% indicates the most severe level of knock allowed ...";
CM_ SG_ 2364557054 EngCyl13PeakPress "Peak pressure in engine cylinder 13 in combustion cycle.";
CM_ SG_ 2364557054 EngCyl13HeatRelease "The amount of heat produced during combustion in engine cylinder 13.  The negative range is to cover thermodynamic behavior during misfire.";
CM_ BO_ 2364556798 "Engine Cylinder 12 Combustion Information
Used to communicate combustion information of Engine Cylinder 12. The PG is transmitted at the end of every combustion in Cylinder 12.";
CM_ SG_ 2364556798 MaxPressIncreaseRate "The maximum slope, in degrees of crank angle, of the pressure increase in engine cylinder 12 during the combustion cycle.";
CM_ SG_ 2364556798 LowFreqKnockLvl "Indicates the level of low frequency knock for engine cylinder 12. This knock occurs at frequencies below the typical knock level reported on SPNs 1363 & 6442.  The level of low frequency knock is reported using a relative scale where 0% is least ...";
CM_ SG_ 2364556798 EngCyl12PrssSensorPreliminaryFMI "Used to identify the applicable J1939-73 FMI detected in the engine cylinder 12 pressure sensor.  In the case of multiple failures the most severe is communicated.
A value of 31 is sent to indicate that no failure has been detected or this ...";
CM_ SG_ 2364556798 EngCyl12SynchronousKnockLevel "Used to indicate the level of knock for engine cylinder 12. The level of knock is reported using a relative scale where 0% is least level of knock, and increasing levels indicate more knock until 100% indicates the most severe level of knock allowed ...";
CM_ SG_ 2364556798 EngCyl12PeakPress "Peak pressure in engine cylinder 12 in combustion cycle.";
CM_ SG_ 2364556798 EngCyl12HeatRelease "The amount of heat produced during combustion in engine cylinder 12.  The negative range is to cover thermodynamic behavior during misfire.";
CM_ BO_ 2364556542 "Engine Cylinder 11 Combustion Information
Used to communicate combustion information of Engine Cylinder 11. The PG is transmitted at the end of every combustion in Cylinder 11.";
CM_ SG_ 2364556542 MaxPressIncreaseRate "The maximum slope, in degrees of crank angle, of the pressure increase in engine cylinder 11 during the combustion cycle.";
CM_ SG_ 2364556542 LowFreqKnockLvl "Indicates the level of low frequency knock for engine cylinder 11. This knock occurs at frequencies below the typical knock level reported on SPNs 1362 & 6438.  The level of low frequency knock is reported using a relative scale where 0% is least ...";
CM_ SG_ 2364556542 EngCyl11PrssSensorPreliminaryFMI "Used to identify the applicable J1939-73 FMI detected in the engine cylinder 11 pressure sensor.  In the case of multiple failures the most severe is communicated.
A value of 31 is sent to indicate that no failure has been detected or this ...";
CM_ SG_ 2364556542 EngCyl11SynchronousKnockLevel "Used to indicate the level of knock for engine cylinder 11. The level of knock is reported using a relative scale where 0% is least level of knock, and increasing levels indicate more knock until 100% indicates the most severe level of knock allowed ...";
CM_ SG_ 2364556542 EngCyl11PeakPress "Peak pressure in engine cylinder 11 in combustion cycle.";
CM_ SG_ 2364556542 EngCyl11HeatRelease "The amount of heat produced during combustion in engine cylinder 11.  The negative range is to cover thermodynamic behavior during misfire.";
CM_ BO_ 2364556286 "Engine Cylinder 10 Combustion Information
Used to communicate combustion information of Engine Cylinder 10. The PG is transmitted at the end of every combustion in Cylinder 10.";
CM_ SG_ 2364556286 MaxPressIncreaseRate "The maximum slope, in degrees of crank angle, of the pressure increase in engine cylinder 10 during the combustion cycle.";
CM_ SG_ 2364556286 LowFreqKnockLvl "Indicates the level of low frequency knock for engine cylinder 10. This knock occurs at frequencies below the typical knock level reported on SPNs 1361 & 6434.  The level of low frequency knock is reported using a relative scale where 0% is least ...";
CM_ SG_ 2364556286 EngCyl10PrssSensorPreliminaryFMI "Used to identify the applicable J1939-73 FMI detected in the engine cylinder 10 pressure sensor.  In the case of multiple failures the most severe is communicated.
A value of 31 is sent to indicate that no failure has been detected or this ...";
CM_ SG_ 2364556286 EngCyl10SynchronousKnockLevel "Used to indicate the level of knock for engine cylinder 10. The level of knock is reported using a relative scale where 0% is least level of knock, and increasing levels indicate more knock until 100% indicates the most severe level of knock allowed ...";
CM_ SG_ 2364556286 EngCyl10PeakPress "Peak pressure in engine cylinder 10 in combustion cycle.";
CM_ SG_ 2364556286 EngCyl10HeatRelease "The amount of heat produced during combustion in engine cylinder 10.  The negative range is to cover thermodynamic behavior during misfire.";
CM_ BO_ 2364556030 "Engine Cylinder 9 Combustion Information
Used to communicate combustion information of Engine Cylinder 9. The PG is transmitted at the end of every combustion in Cylinder 9.";
CM_ SG_ 2364556030 MaxPressIncreaseRate "The maximum slope, in degrees of crank angle, of the pressure increase in engine cylinder 9 during the combustion cycle.";
CM_ SG_ 2364556030 LowFreqKnockLvl "Indicates the level of low frequency knock for engine cylinder 9. This knock occurs at frequencies below the typical knock level reported on SPNs 1360 & 6430.  The level of low frequency knock is reported using a relative scale where 0% is least ...";
CM_ SG_ 2364556030 EngCyl9PressSensorPreliminaryFMI "Used to identify the applicable J1939-73 FMI detected in the engine cylinder 9 pressure sensor.  In the case of multiple failures the most severe is communicated.
A value of 31 is sent to indicate that no failure has been detected or this parameter ...";
CM_ SG_ 2364556030 EngCyl9SynchronousKnockLevel "Used to indicate the level of knock for engine cylinder 9. The level of knock is reported using a relative scale where 0% is least level of knock, and increasing levels indicate more knock until 100% indicates the most severe level of knock allowed ...";
CM_ SG_ 2364556030 EngCyl9PeakPress "Peak pressure in engine cylinder 9 in combustion cycle.";
CM_ SG_ 2364556030 EngCyl9HeatRelease "The amount of heat produced during combustion in engine cylinder 9.  The negative range is to cover thermodynamic behavior during misfire.";
CM_ BO_ 2364555774 "Engine Cylinder 8 Combustion Information
Used to communicate combustion information of Engine Cylinder 8. The PG is transmitted at the end of every combustion in Cylinder 8.";
CM_ SG_ 2364555774 MaxPressIncreaseRate "The maximum slope, in degrees of crank angle, of the pressure increase in engine cylinder 8 during the combustion cycle.";
CM_ SG_ 2364555774 LowFreqKnockLvl "Indicates the level of low frequency knock for engine cylinder 8. This knock occurs at frequencies below the typical knock level reported on SPNs 1359 & 6426.  The level of low frequency knock is reported using a relative scale where 0% is least ...";
CM_ SG_ 2364555774 EngCyl8PressSensorPreliminaryFMI "Used to identify the applicable J1939-73 FMI detected in the engine cylinder 8 pressure sensor.  In the case of multiple failures the most severe is communicated.
A value of 31 is sent to indicate that no failure has been detected or this parameter ...";
CM_ SG_ 2364555774 EngCyl8SynchronousKnockLevel "Used to indicate the level of knock for engine cylinder 8. The level of knock is reported using a relative scale where 0% is least level of knock, and increasing levels indicate more knock until 100% indicates the most severe level of knock allowed ...";
CM_ SG_ 2364555774 EngCyl8PeakPress "Peak pressure in engine cylinder 8 in combustion cycle.";
CM_ SG_ 2364555774 EngCyl8HeatRelease "The amount of heat produced during combustion in engine cylinder 8.  The negative range is to cover thermodynamic behavior during misfire.";
CM_ BO_ 2364555518 "Engine Cylinder 7 Combustion Information
Used to communicate combustion information of Engine Cylinder 7. The PG is transmitted at the end of every combustion in Cylinder 7.";
CM_ SG_ 2364555518 MaxPressIncreaseRate "The maximum slope, in degrees of crank angle, of the pressure increase in engine cylinder 7 during the combustion cycle.";
CM_ SG_ 2364555518 LowFreqKnockLvl "Indicates the level of low frequency knock for engine cylinder 7. This knock occurs at frequencies below the typical knock level reported on SPNs 1358 & 6422.  The level of low frequency knock is reported using a relative scale where 0% is least ...";
CM_ SG_ 2364555518 EngCyl7PressSensorPreliminaryFMI "Used to identify the applicable J1939-73 FMI detected in the engine cylinder 7 pressure sensor. In the case of multiple failures the most severe is communicated.
A value of 31 is sent to indicate that no failure has been detected or this parameter ...";
CM_ SG_ 2364555518 EngCyl7SynchronousKnockLevel "Used to indicate the level of knock for engine cylinder 7. The level of knock is reported using a relative scale where 0% is least level of knock, and increasing levels indicate more knock until 100% indicates the most severe level of knock allowed ...";
CM_ SG_ 2364555518 EngCyl7PeakPress "Peak pressure in engine cylinder 7 in combustion cycle.";
CM_ SG_ 2364555518 EngCyl7HeatRelease "The amount of heat produced during combustion in engine cylinder 7.  The negative range is to cover thermodynamic behavior during misfire.";
CM_ BO_ 2364555262 "Engine Cylinder 6 Combustion Information
Used to communicate combustion information of Engine Cylinder 6. The PG is transmitted at the end of every combustion in Cylinder 6.";
CM_ SG_ 2364555262 MaxPressIncreaseRate "The maximum slope, in degrees of crank angle, of the pressure increase in engine cylinder 6 during the combustion cycle.";
CM_ SG_ 2364555262 LowFreqKnockLvl "Indicates the level of low frequency knock for engine cylinder 6. This knock occurs at frequencies below the typical knock level reported on SPNs 1357 & 6418.  The level of low frequency knock is reported using a relative scale where 0% is least ...";
CM_ SG_ 2364555262 EngCyl6PressSensorPreliminaryFMI "Used to identify the applicable J1939-73 FMI detected in the engine cylinder 6 pressure sensor.  In the case of multiple failures the most severe is communicated.
A value of 31 is sent to indicate that no failure has been detected or this parameter ...";
CM_ SG_ 2364555262 EngCyl6SynchronousKnockLevel "Used to indicate the level of knock for engine cylinder 6. The level of knock is reported using a relative scale where 0% is least level of knock, and increasing levels indicate more knock until 100% indicates the most severe level of knock allowed ...";
CM_ SG_ 2364555262 EngCyl6PeakPress "Peak pressure in engine cylinder 6 in combustion cycle.";
CM_ SG_ 2364555262 EngCyl6HeatRelease "The amount of heat produced during combustion in engine cylinder 6.  The negative range is to cover thermodynamic behavior during misfire.";
CM_ BO_ 2364555006 "Engine Cylinder 5 Combustion Information
Used to communicate combustion information of Engine Cylinder 5. The PG is transmitted at the end of every combustion in Cylinder 5.";
CM_ SG_ 2364555006 MaxPressIncreaseRate "The maximum slope, in degrees of crank angle, of the pressure increase in engine cylinder 5 during the combustion cycle.";
CM_ SG_ 2364555006 LowFreqKnockLvl "Indicates the level of low frequency knock for engine cylinder 5. This knock occurs at frequencies below the typical knock level reported on SPNs 1356 & 6414.  The level of low frequency knock is reported using a relative scale where 0% is least ...";
CM_ SG_ 2364555006 EngCyl5PressSensorPreliminaryFMI "Used to identify the applicable J1939-73 FMI detected in the engine cylinder 5 pressure sensor.  In the case of multiple failures the most severe is communicated.
A value of 31 is sent to indicate that no failure has been detected or this parameter ...";
CM_ SG_ 2364555006 EngCyl5SynchronousKnockLevel "Used to indicate the level of knock for engine cylinder 6. The level of knock is reported using a relative scale where 0% is least level of knock, and increasing levels indicate more knock until 100% indicates the most severe level of knock allowed ...";
CM_ SG_ 2364555006 EngCyl5PeakPress "Peak pressure in engine cylinder 5 in combustion cycle.";
CM_ SG_ 2364555006 EngCyl5HeatRelease "The amount of heat produced during combustion in engine cylinder 5.  The negative range is to cover thermodynamic behavior during misfire.";
CM_ BO_ 2364554750 "Engine Cylinder 4 Combustion Information
Used to communicate combustion information of Engine Cylinder 4. The PG is transmitted at the end of every combustion in Cylinder 4.";
CM_ SG_ 2364554750 MaxPressIncreaseRate "The maximum slope, in degrees of crank angle, of the pressure increase in engine cylinder 4 during the combustion cycle.";
CM_ SG_ 2364554750 LowFreqKnockLvl "Indicates the level of low frequency knock for engine cylinder 4. This knock occurs at frequencies below the typical knock level reported on SPNs 1355 & 6410.  The level of low frequency knock is reported using a relative scale where 0% is least ...";
CM_ SG_ 2364554750 EngCyl4PressSensorPreliminaryFMI "Used to identify the applicable J1939-73 FMI detected in the engine cylinder 4 pressure sensor. In the case of multiple failures the most severe is communicated.
A value of 31 is sent to indicate that no failure has been detected or this parameter ...";
CM_ SG_ 2364554750 EngCyl4SynchronousKnockLevel "Used to indicate the level of knock for engine cylinder 4. The level of knock is reported using a relative scale where 0% is least level of knock, and increasing levels indicate more knock until 100% indicates the most severe level of knock allowed ...";
CM_ SG_ 2364554750 EngCyl4PeakPress "Peak pressure in engine cylinder 4 in combustion cycle.";
CM_ SG_ 2364554750 EngCyl4HeatRelease "The amount of heat produced during combustion in engine cylinder 4.  The negative range is to cover thermodynamic behavior during misfire.";
CM_ BO_ 2364554494 "Engine Cylinder 3 Combustion Information
Used to communicate combustion information of Engine Cylinder 3. The PG is transmitted at the end of every combustion in Cylinder 3.";
CM_ SG_ 2364554494 MaxPressIncreaseRate "The maximum slope, in degrees of crank angle, of the pressure increase in engine cylinder 3 during the combustion cycle.";
CM_ SG_ 2364554494 LowFreqKnockLvl "Indicates the level of low frequency knock for engine cylinder 3. This knock occurs at frequencies below the typical knock level reported on SPNs 1354 & 6406.  The level of low frequency knock is reported using a relative scale where 0% is least ...";
CM_ SG_ 2364554494 EngCyl3PressSensorPreliminaryFMI "Used to identify the applicable J1939-73 FMI detected in the engine cylinder 3 pressure sensor.  In the case of multiple failures the most severe is communicated.
A value of 31 is sent to indicate that no failure has been detected or this parameter ...";
CM_ SG_ 2364554494 EngCyl3SynchronousKnockLevel "Used to indicate the level of knock for engine cylinder 3. The level of knock is reported using a relative scale where 0% is least level of knock, and increasing levels indicate more knock until 100% indicates the most severe level of knock allowed ...";
CM_ SG_ 2364554494 EngCyl3PeakPress "Peak pressure in engine cylinder 3 in combustion cycle.";
CM_ SG_ 2364554494 EngCyl3HeatRelease "The amount of heat produced during combustion in engine cylinder 3.  The negative range is to cover thermodynamic behavior during misfire.";
CM_ BO_ 2364554238 "Engine Cylinder 2 Combustion Information
Used to communicate combustion information of Engine Cylinder 2. The PG is transmitted at the end of every combustion in Cylinder 2.";
CM_ SG_ 2364554238 MaxPressIncreaseRate "The maximum slope, in degrees of crank angle, of the pressure increase in engine cylinder 2 during the combustion cycle.";
CM_ SG_ 2364554238 LowFreqKnockLvl "Indicates the level of low frequency knock for engine cylinder 2. This knock occurs at frequencies below the typical knock level reported on SPNs 1353 & 6402.  The level of low frequency knock is reported using a relative scale where 0% is least ...";
CM_ SG_ 2364554238 EngCyl2PressSensorPreliminaryFMI "Used to identify the applicable J1939-73 FMI detected in the engine cylinder 2 pressure sensor.  In the case of multiple failures the most severe is communicated.
A value of 31 is sent to indicate that no failure has been detected or this parameter ...";
CM_ SG_ 2364554238 EngCyl2SynchronousKnockLevel "Used to indicate the level of knock for engine cylinder 2. The level of knock is reported using a relative scale where 0% is least level of knock, and increasing levels indicate more knock until 100% indicates the most severe level of knock allowed ...";
CM_ SG_ 2364554238 EngCyl2PeakPress "Peak pressure in engine cylinder 2 in combustion cycle.";
CM_ SG_ 2364554238 EngCyl2HeatRelease "The amount of heat produced during combustion in engine cylinder 2.  The negative range is to cover thermodynamic behavior during misfire.";
CM_ BO_ 2364553982 "Engine Cylinder 1 Combustion Information
Used to communicate combustion information of Engine Cylinder 1. The PG is transmitted at the end of every combustion in Cylinder 1.";
CM_ SG_ 2364553982 MaxPressIncreaseRate "The maximum slope, in degrees of crank angle, of the pressure increase in engine cylinder 1 during the combustion cycle.";
CM_ SG_ 2364553982 LowFreqKnockLvl "Indicates the level of low frequency knock for engine cylinder 1. This knock occurs at frequencies below the typical knock level reported on SPNs 1352 & 6398. The level of low frequency knock is reported using a relative scale where 0% is least ...";
CM_ SG_ 2364553982 EngCyl1PressSensorPreliminaryFMI "Used to identify the applicable J1939-73 FMI detected in the engine cylinder 1 pressure sensor. In the case of multiple failures the most severe is communicated.
A value of 31 is sent to indicate that no failure has been detected or this parameter ...";
CM_ SG_ 2364553982 EngCyl1SynchronousKnockLevel "Used to indicate the level of knock for engine cylinder 1. The level of knock is reported using a relative scale where 0% is least level of knock, and increasing levels indicate more knock until 100% indicates the most severe level of knock allowed ...";
CM_ SG_ 2364553982 EngCyl1PeakPress "Peak pressure in engine cylinder 1 in combustion cycle.";
CM_ SG_ 2364553982 EngCyl1HeatRelease "The amount of heat produced during combustion in Engine cylinder 1. The negative range is to cover thermodynamic behavior during misfire.";
CM_ BO_ 2364553726 "Engine Air System Information
Used to transmit parameters related to air systems.";
CM_ SG_ 2364553726 FuelSys2TotalInMassAirFlowRate "Mass Flow rate of air entering the second fuel system of the engine. This also includes the amount of exhaust gas recirculated, if any.";
CM_ SG_ 2364553726 EngTotalIntakeMassAirFlowRate "Mass Flow rate of air entering the engine (or the first fuel system on a configuration with more than 1 fuel system). This also includes the amount of exhaust gas recirculated, if any.";
CM_ SG_ 2364553726 EngDesiredAirFuelRatio "Reports the desired Air Fuel ratio for the engine.

Air Fuel Ratio specifies the amount of air required to completely burn one unit of fuel in the engine to meet the required engine performance and emission standards.";
CM_ BO_ 2364553470 "Engine Torque / Fuel Request
Used to transmit requested information for engine torque and fuel rate.";
CM_ SG_ 2364553470 EngCylTorque "Calculated engine torque output per cylinder.";
CM_ SG_ 2364553470 EngCylDieselMassFlowRateCmd "Commanded Mass Flow rate of diesel fuel delivered to the engine normalized per cylinder.";
CM_ SG_ 2364553470 EngCylGasMassFlowRateCmd "Commanded Mass Flow rate of gaseous fuel delivered to the engine normalized per cylinder.";
CM_ SG_ 2364553470 EngGasFuelPercentageCmd "Percentage of Gaseous fuel used, in terms of % mass of fuel. 0% means no Gaseous fuel used and 100 % means completely gaseous fuel is used.
Gas substitution is the process for a dual fuel engine system of substituting gas, e.g. natural gas, for ...";
CM_ SG_ 2364553470 EngDualFuelModeCmd "Request to enable dual fuel mode.

00b = De-activate dual fuel mode
01b = Activate dual fuel mode
10b = Reserved
11b = Not available";
CM_ BO_ 2364553214 "Engine Turbocharger Blowoff Actuator 1
Used to transmit Engine Turbocharger Blowoff Actuator parameters";
CM_ SG_ 2364553214 EngTrbCmprssrBlwffActtr1OprtnStt "Used to identify the status of Engine Turbocharger Compressor Blowoff Actuator 1.
0000b = Normal
0001b = Alarm (fully operational but needs service)
0010b = Alarm High Severity (functional but transient performance may be reduced)
0011b = Derate ...";
CM_ SG_ 2364553214 EngTrbCmprssrBlowoffActuator1Pos "Actual position of the turbocharger compressor blowoff actuator, where 0% represents fully closed and 100% represents fully open.";
CM_ SG_ 2364553214 EngTrbCmprssrBlwffActtr1DsredPos "The requested position of the Engine Turbocharger Compressor Blowoff actuator by the engine ECU, where 0% represents bypass fully closed and 100% represents fully open.  This is the position that the device is attempting to achieve.";
CM_ SG_ 2364553214 EngTrbCmprssrBlwoffActuator1Temp "Temperature of the Engine Turbocharger Compressor Bypass Actuator 1 drive circuitry. Temperature excursions may affect the torque output.";
CM_ SG_ 2364553214 EngTrbCmprssrBlwffActtr1TmpSttus "Used to identify the status of the Engine Turbocharger Compresssor Blowoff Actuator 1 drive circuitry temperature. Temperature excursions may affect the torque output.
000b = High Most severe
001b = High Least severe
010b = In Range
011b = Low ...";
CM_ SG_ 2364553214 EngTrbCmprssrBlwffActtr1PrlmnryF "Used to identify the applicable J1939-73 FMI detected in the Engine Turbocharger Blowoff Actuator 1 by the manufacturer's software.  When there are multiple failures, the most severe is transmitted.
A value of 31 is sent to indicate that no failure ...";
CM_ BO_ 2565874430 "Machine Selected Speed
Message that provides the current machine selected speed, direction, and source parameters.";
CM_ SG_ 2565874430 PersistentLimitStatus "Reports the tractor ECU's present limit status associated with a parameter whose commands are presistent  (i.e. hitch position).
000 - Not limited
001 - Operator limited/controlled (Request cannot be implemented)
010 - Limited high (only lower ...";
CM_ SG_ 2565874430 MachineSelectedSpeedSource "Indicates the speed source that is currently being reported in the machine speed parameter.
000 - Wheel-based speed
001 - Ground-based speed
010 - Navigation-based speed
011 - 'Blended' speed
100 - 'Simulated' speed
101 - 110 - Reserved
111 - ...";
CM_ SG_ 2565874430 MachineSelectedDirection "Indicates the current direction of travel of the machine.

00 - Reverse
01 - Forward
10 - Error indication
11 - Not available";
CM_ SG_ 2565874430 MachineSelectedDistance "Actual distance traveled by the machine based on the value of selected machine speed.  When distance exceeds 4211081.215 m, the value should be reset to zero and incremented as additional distance accrues.";
CM_ SG_ 2565874430 MachineSelectedSpeed "Reports the value of one of the currently available machine speeds (wheel, ground, or navigational-based) which the machine has determined to best represent the machine's speed.";
CM_ BO_ 2565873918 "Electronic Brake System #2/5
Message to transmit data of the towed vehicle to the towing vehicle. See ISO 11992-2.";
CM_ BO_ 2565873662 "Electronic Brake System #2/6
Message to transmit data of the towed vehicle to the towing vehicle. See ISO 11992-2.";
CM_ BO_ 2364546814 "Generator Control 2
Contains parameters that allow the generator control system to control the engine and to provide information about the generator control system
These parameters are intended for stationary Generator/Engine components, not ...";
CM_ SG_ 2364546814 EngLoadSetpointReq "Setpoint request (in kW) sent to the engine by a genset control system.";
CM_ SG_ 2364546814 EngSelfInducedDerateInh "Parameter to indicate if the genset control system allows the Engine Control Module to impose its own induced derate.
00b = Engine is allowed to impose a self-induced derate
01b = Engine is inhibited from imposing a self-induced derate
10b = SAE ...";
CM_ SG_ 2364546814 GeneratorGoverningBias "Control signal used to govern the genset's speed or load (depending on isochronous or utility parallel operation, respectively)
NOTE:  If this method of engine control is used, the PGN 0 (TSC1) is not expected to be received by the engine ...";
CM_ BO_ 2565872638 "General Purpose Message #1/7
Message to transmit data of the towing vehicle to the towed vehicle. See ISO 11992-3.";
CM_ BO_ 2565865214 "Proprietary A
This proprietary PG uses the Destination Specific PDU Format allowing manufacturers to direct their proprietary communications to a specific destination node.";
CM_ BO_ 2565340926 "Node-to-Virtual Terminal";
CM_ BO_ 2565275390 "Virtual Terminal-to-Node";
CM_ BO_ 2566767614 "Electronic Engine Controller 15";
CM_ SG_ 2566767614 ExhGasRestrictionVlvCtrl "Desired percentage of maximum Exhaust Gas Restriction opening for valve. 0% means valve is closed. 100% means maximum valve opening (full gas flow).";
CM_ SG_ 2566767614 AccelPedal2Channel3 "Sensor output 3 for the accelerator pedal #2 position when using a redundant-style sensor.  The ratio of actual accelerator pedal position to maximum pedal position. This is for the second occurrence of the accelerator pedal. Although it is used as ...";
CM_ SG_ 2566767614 AccelPedal2Channel2 "Sensor output 2 for the accelerator pedal #2 position when using a redundant-style sensor.  The ratio of actual accelerator pedal position to maximum pedal position. This is for the second occurrence of the accelerator pedal. Although it is used as ...";
CM_ SG_ 2566767614 AccelPedal1Channel3 "Sensor output 3 for the accelerator pedal #1 position when using a redundant-style sensor.  The ratio of actual accelerator pedal position to maximum pedal position. This is for the first occurrence of the accelerator pedal. Although it is used as ...";
CM_ SG_ 2566767614 AccelPedal1Channel2 "Sensor output 2 for the accelerator pedal #1 position when using a redundant-style sensor.  The ratio of actual accelerator pedal position to maximum pedal position. This is for the first occurrence of the accelerator pedal. Although it is used as ...";
CM_ BO_ 2231031806 "Object Detection Message #1/1
With this PG, relevant information for the automated steering function is sent from the towing vehicle to the towed vehicle. See ISO 11992-3.";
CM_ BO_ 2559049470 "Engine State Requests";
CM_ SG_ 2559049470 ProtectionDerateOvrdCmd "Command signal to override engine protection derate.
This is to temporarily override an engine protection derate due to coolant temperature, oil pressure etc. This is for applications such as fire, rescue, and military vehicles to help them get out ...";
CM_ SG_ 2559049470 FuelingNotDesReason "This parameter conveys the reason a device wants the engine to inhibit fueling.
This SP is intended to be used in conjunction with Desired Engine Fueling State (SPN 5793). When a device sends Desired Engine Fueling State = \"Fueling Not Desired\", ...";
CM_ SG_ 2559049470 ShutdownCmd "Command to shut down the engine. If this parameter is received as 01b, then the engine should behave as if the key switch was turned off. An example of how this parameter could be used is an ECU would send 01b for this parameter if the operator ...";
CM_ SG_ 2559049470 TransIdleGovFuelingInh "This parameter is a command provided to the Engine Control Module (ECM) from the Transmission Control Module (TCM) to inhibit idle governor fueling in the unlikely event that transmission has detected a failure preventing driveline disengagement ...";
CM_ SG_ 2559049470 FuelingDesReason "This parameter conveys the reason a device wants the engine running.
This SP is intended to be used in conjunction with Desired Engine Fueling State (SPN 5793). When a device sends Desired Engine Fueling State = \"Fueling Desired\" either alone or in ...";
CM_ SG_ 2559049470 DesiredEngFuelingState "Devices send this request to the engine controller to:
(a) Shut off engine fueling, but remain prepared to re-start quickly by not shutting down the control system, or
(b) Keep the engine running.
00b = Fueling not desired (shut off engine ...";
CM_ SG_ 2559049470 RequestedFuelType "Engine controller receives this request from another control module to select the type of fuel to be used for engine operation.
00h = Not available - NONE
01h = Gasoline/petrol - GAS
02h = Methanol - METH
03h = Ethanol - ETH
04h = Diesel - DSL
 ...";
CM_ SG_ 2559049470 EngGasFuelSupplyDesiredPress "Desired gage pressure of gaseous fuel supply to the engine.";
CM_ SG_ 2559049470 EngGasFuelUsageInhibited "Used to request that the engine should not be allowed to use gaseous fuel for engine cylinder combustion. This state is relevant for dual fuel systems and would be used when conditions are detected that make it unsafe or not appropriate to use ...";
CM_ BO_ 2349596414 "Advanced Emergency Braking System 2
Advanced Emergency Braking System message 2.";
CM_ SG_ 2349596414 AEBS2MessageChecksum "Used to check the message checksum of the transmitting (HMI) unit within the AEBS2 system.
For SAE J1939-21 implementations, the \"Message ID\" is the classic CAN indentifier.
For SAE J1939-22 implementations, the \"Message ID\" content is as follows:
 ...";
CM_ SG_ 2349596414 AEBS2MessageCounter "The message counter is increased with every transmitted AEBS2 message.  After reaching a value of Fh the next value will be 0.";
CM_ SG_ 2349596414 DrvrActvtnDmndFrAdvncdEmrgncyBrk "According to the Vienna world convention on road traffic the driver must be provided with means to deactivate an Advanced Emergency Braking System. This command is to be transmitted from the respective HMI unit to the AEBS unit.
00b = the driver ...";
CM_ BO_ 2563702526 "Reserved for ISO 15765
KWP2000 Mixed physical addressing";
CM_ BO_ 2563636990 "Reserved for ISO 15765
KWP2000 Mixed functional addressing";
CM_ BO_ 2563571454 "Request for Repetition Rate
This message allows the system to adapt the bus bandwidth to the needs of the user of messages.";
CM_ SG_ 2563571454 DataDictionaryRow "This 4 bit parameter indicates the Row that is to be used within the specific Data Dictionary Table identified by the Implement Type. This is the Group (GRUP) in LBS documents.";
CM_ SG_ 2563571454 DataDictionaryColumn "This 4 bit parameter indicates the Column that is to be used within the specific Data Dictionary Table identified by the Implement Type. This is the Instance (INST) in LBS documents.";
CM_ SG_ 2563571454 ImplementType "This 4 bit parameter indicates which data dictionary page is to be used to locate the identity of the following data.";
CM_ SG_ 2563571454 ImplementPos "This 4 bit parameter of this message will indicate which Implement is referenced within a set of identical Implements.  The numbering is to start with 1 at the leftmost, foremost, bottom most implement.  The numbering will then increment from left ...";
CM_ SG_ 2563571454 DataFormat_ErrorCondition "This 2 bit parameter that indicates the format or availability of the data in the following Process Data Parameter.
00 Data format is Long Integer
01 Data format is Floating
10 Data format is unsigned Long Integer
11 Not Available or error
Data ...";
CM_ SG_ 2563571454 ProcessDataType "This 2 bit parameter indicates what the data in the following Process Data Parameters is to be used for. See Table A.2.
00 Data is Set Point
01 Data is Actual values
10 Message is Set Point request
11 Message is Actual value request
Data is Set ...";
CM_ SG_ 2563571454 ProcessDataModifier "This 3 bit parameter that indicates how the data in the following Process Data Parameters is to be used when combined with the Process Data Type parameter. See Table A.2.

NOTE: Process Data Type is included since MOD is a function of PD";
CM_ SG_ 2563571454 RepetitionRateParameter "This parameter defines the repetition rate of the specified PGN.";
CM_ BO_ 2563505918 "Process Data Message
The Process Data message has been defined as a destination specific message implying that the sender must decide which implement should receive the message.Working Set).";
CM_ SG_ 2563505918 ProcessVariableValue "This 4 byte parameter contains the actual data  for the Process Data Message.";
CM_ SG_ 2563505918 DataDictionaryRow "This 4 bit parameter indicates the Row that is to be used within the specific Data Dictionary Table identified by the Implement Type. This is the Group (GRUP) in LBS documents.";
CM_ SG_ 2563505918 DataDictionaryColumn "This 4 bit parameter indicates the Column that is to be used within the specific Data Dictionary Table identified by the Implement Type. This is the Instance (INST) in LBS documents.";
CM_ SG_ 2563505918 ImplementType "This 4 bit parameter indicates which data dictionary page is to be used to locate the identity of the following data.";
CM_ SG_ 2563505918 ImplementPos "This 4 bit parameter of this message will indicate which Implement is referenced within a set of identical Implements.  The numbering is to start with 1 at the leftmost, foremost, bottom most implement.  The numbering will then increment from left ...";
CM_ SG_ 2563505918 CountNumber "This parameter indicates which member of the set of possible entities is being referenced. The means of generating this Count Number is explained in the following clause.";
CM_ SG_ 2563505918 DataFormat_ErrorCondition "This 2 bit parameter that indicates the format or availability of the data in the following Process Data Parameter.
00 Data format is Long Integer
01 Data format is Floating
10 Data format is unsigned Long Integer
11 Not Available or error
Data ...";
CM_ SG_ 2563505918 ProcessDataType "This 2 bit parameter indicates what the data in the following Process Data Parameters is to be used for. See Table A.2.
00 Data is Set Point
01 Data is Actual values
10 Message is Set Point request
11 Message is Actual value request
Data is Set ...";
CM_ SG_ 2563505918 ProcessDataModifier "This 3 bit parameter that indicates how the data in the following Process Data Parameters is to be used when combined with the Process Data Type parameter. See Table A.2.

NOTE: Process Data Type is included since MOD is a function of PD";
CM_ BO_ 2563309310 "Extended Transport Protocol - Connection Management
Defined in ISO 11783-6  Annex L";
CM_ BO_ 2563243774 "Extended Transport Protocol - Data Transfer
Defined in ISO 11783-6  Annex L";
CM_ BO_ 2563178238 "General Purpose Valve Estimated Flow
This message provides the estimated flow of a general purpose valve.  Defined in ISO 11783-7.";
CM_ SG_ 2563178238 ValveFailSafeMode "Command for setting the fail safe mode of a general purpose valve.

00 Block
01 Float
10 Reserved
11 Don’t Care";
CM_ SG_ 2563178238 ValveState "The measured state of the general purpose valve.   With float enabled, hydraulic fluid may flow to or from the tractor as driven by the implement.
0000            Blocked
0001            Extend
0010            Retract
0011            Floating
 ...";
CM_ SG_ 2563178238 RetractPortEstFlow "The value reported by the controller of flow through the extend port of an auxiliary valve of a tractor";
CM_ SG_ 2563178238 ExtendPortEstFlow "The value reported by the controller of flow through the extend port of an auxiliary valve of a tractor";
CM_ BO_ 2563112702 "General Purpose Valve Measured Flow
This message provides the measurement of a general purpose valve.  Defined in ISO11783-7.";
CM_ SG_ 2563112702 ReturnPortPress "The measured nominal pressure at the return port of an auxiliary valve of a tractor";
CM_ SG_ 2563112702 RetractPortPress "The measured nominal pressure at the retract port of an auxiliary valve of a tractor";
CM_ SG_ 2563112702 ExtendPortPress "The measured nominal pressure at the extend port of an auxiliary valve of a tractor";
CM_ SG_ 2563112702 RetractPortMeasuredFlow "The measured flow through the retract port of an auxiliary valve of a tractor";
CM_ SG_ 2563112702 ExtendPortMeasuredFlow "The measured flow through the extend port of an auxiliary valve of a tractor";
CM_ BO_ 2563047166 "General Purpose Valve Command
This message provides control of the flow through a general purpose valve.  Defined in ISO 11783-7.";
CM_ SG_ 2563047166 PortFlowCmd "The command to set the flow through the extend or retract port of an auxiliary valve of a tractor";
CM_ BO_ 2562785022 "Proprietarily Configurable Message #16
Proprietarily Configuration message for use in J1939-74.";
CM_ BO_ 2562719486 "Proprietarily Configurable Message #15
Proprietarily Configuration message for use in J1939-74.";
CM_ BO_ 2562653950 "Proprietarily Configurable Message #14
Proprietarily Configuration message for use in J1939-74.";
CM_ BO_ 2562588414 "Proprietarily Configurable Message #13
Proprietarily Configuration message for use in J1939-74.";
CM_ BO_ 2562522878 "Proprietarily Configurable Message #12
Proprietarily Configuration message for use in J1939-74.";
CM_ BO_ 2562457342 "Proprietarily Configurable Message #11
Proprietarily Configuration message for use in J1939-74.";
CM_ BO_ 2562391806 "Proprietarily Configurable Message #10
Proprietarily Configuration message for use in J1939-74.";
CM_ BO_ 2562326270 "Proprietarily Configurable Message #9
Proprietarily Configuration message for use in J1939-74.";
CM_ BO_ 2562260734 "Proprietarily Configurable Message #8
Proprietarily Configuration message for use in J1939-74.";
CM_ BO_ 2562195198 "Proprietarily Configurable Message #7
Proprietarily Configuration message for use in J1939-74.";
CM_ BO_ 2562129662 "Proprietarily Configurable Message #6
Proprietarily Configuration message for use in J1939-74.";
CM_ BO_ 2562064126 "Proprietarily Configurable Message #5
Proprietarily Configuration message for use in J1939-74.";
CM_ BO_ 2561998590 "Proprietarily Configurable Message #4
Proprietarily Configuration message for use in J1939-74.";
CM_ BO_ 2561933054 "Proprietarily Configurable Message #3
Proprietarily Configuration message for use in J1939-74.";
CM_ BO_ 2561867518 "Proprietarily Configurable Message #2
Proprietarily Configuration message for use in J1939-74.";
CM_ BO_ 2561801982 "Proprietarily Configurable Message #1
Proprietarily Configuration message for use in J1939-74.";
CM_ BO_ 2561736446 "Configuration Identification Message
Message used to identify the data content (by SPN) of one of the configurable messages
(identified by PGN).";
CM_ BO_ 2561670910 "Parameter Locate Message
This message is designed to cause other CAs to respond with the identity of any message that they send in which the particular parameter (identified by specific SPN) is contained";
CM_ BO_ 2561539838 "Agricultural Guidance System Command
Steering command expressed as desired curvature";
CM_ BO_ 2561474302 "Agricultural Guidance Machine Info
Machine system feedback detailing status of machine relative to guidance operation";
CM_ BO_ 2561408766 "File Server to Client (ECU) message
Used for obtaining status of the client, volume handling, file access, file handling and directory handling.  Description of messages is given in ISO 11783 Part 13.";
CM_ BO_ 2560294654 "General Purpose Message #1/8
Message to transmit data of the towing vehicle to the towed vehicle. See ISO 11992-3.";
CM_ BO_ 2559835902 "NAME Management Message
A message to change fields of the NAME of a CA";
CM_ SG_ 2559835902 ErrorCode "When  the  NM Control Mode Indicator is set to Mode 0 “Set Pending NAME”, NAME checksum is used as a check to ensure the NM message has been sent to the correct CA.";
CM_ SG_ 2559835902 CommandedAAC "When the NM Control Mode Indicator is set to Mode 0 – Set Pending NAME and the Arbitrary Address Capable Qualifier Flag (SPN 5665) is set to “0”";
CM_ SG_ 2559835902 CommandedIndustryGroup "When the NM Control Mode Indicator is set to Mode 0 – Set Pending NAME and the Industry Group Qualifier Flag (SPN 5664) is set to “0”";
CM_ SG_ 2559835902 CommandedVehicleSystemInstance "When the NM Control Mode Indicator is set to Mode 0 – Set Pending NAME and the Vehicle System Instance Qualifier Flag (SPN 5663) is set to “0”";
CM_ SG_ 2559835902 CommandedVehicleSystem "When the NM Control Mode Indicator is set to Mode 0 – Set Pending NAME and the Vehicle System Qualifier Flag (SPN 5662) is set to “0”";
CM_ SG_ 2559835902 CommandedFunction "When the NM Control Mode Indicator is set to Mode 0 – Set Pending NAME and the Function Qualifier Flag (SPN 5661) is set to “0”";
CM_ SG_ 2559835902 CommandedFunctionInstance "When the NM Control Mode Indicator is set to Mode 0 – Set Pending NAME and the Function Instance Qualifier Flag (SPN 5660) is set to “0”";
CM_ SG_ 2559835902 CommandedECUInstance "When the NM Control Mode Indicator is set to Mode 0 – Set Pending NAME and the ECU Instance Qualifier Flag (SPN 5659) is set to “0”";
CM_ SG_ 2559835902 CommandedManufacturerCode "When the NM Control Mode Indicator is set to Mode 0 – Set Pending NAME and the Manufacturer Code Qualifier Flag (SPN 5658) is set to “0”";
CM_ SG_ 2559835902 NMControlModeIndicator "This four bit parameter is used to define the purpose of the NM message.";
CM_ SG_ 2559835902 AACQualifierFlag "When the NM Control Mode Indicator is set to Mode 0 – Set Pending NAME, this qualifier flag is used to indicate whether the Arbitrary Address Capable field (SPN  5674) shall be used";
CM_ SG_ 2559835902 IndustryGroupQualifierFlag "When the NM Control Mode Indicator is set to Mode 0 – Set Pending NAME, this qualifier flag is used to indicate whether the Industry Group field (SPN 5673) shall be used";
CM_ SG_ 2559835902 VehicleSystemInstanceQualifFlag "When the NM Control Mode Indicator is set to Mode 0 – Set Pending NAME, this qualifier flag is used to indicate whether the Vehicle System Instance field (SPN 5672) shall be used ";
CM_ SG_ 2559835902 VehicleSystemQualifierFlag "When the NM Control Mode Indicator is set to Mode 0 – Set Pending NAME, this qualifier flag is used to indicate whether the Vehicle System field (SPN 5671) shall be used";
CM_ SG_ 2559835902 FunctionQualifierFlag "When the NM Control Mode Indicator is set to Mode 0 – Set Pending NAME, this qualifier flag is used to indicate whether the Function field (SPN 5670) shall be used";
CM_ SG_ 2559835902 FunctionInstanceQualifierFlag "When the NM Control Mode Indicator is set to Mode 0 – Set Pending NAME, this qualifier flag is used to indicate whether the Function Instance field (SPN 5669) shall be used";
CM_ SG_ 2559835902 ECUInstanceQualifierFlag "When the NM Control Mode Indicator is set to Mode 0 – Set Pending NAME, this qualifier flag is used to indicate whether the ECU Instance field (SPN 5668) shall be used";
CM_ SG_ 2559835902 ManufacturerCodeQualifierFlag "When the NM Control Mode Indicator is set to Mode 0 – Set Pending NAME, this qualifier flag is used to indicate whether the Commanded Manufacturer Code field (SPN 5667) shall be used";
CM_ SG_ 2559835902 NAMEChecksum "When  the  NM Control Mode Indicator is set to Mode 0 “Set Pending NAME”, NAME checksum is used as a check to ensure the NM message has been sent to the correct CA.";
CM_ BO_ 2559508222 "Sequence Control Master-to-Sequence Control Client
The PGN is for a sequence control system, such as a headland management system, which includes tractor and implement functions in one system.";
CM_ BO_ 2559442686 "Sequence Control Client-to-Sequence Control Master
This PGN is for sending response messages from control functions to a Sequence Control Master on the tractor and connected implement(s).";
CM_ BO_ 2559377150 "CCP Command Receive Object
The CRO message is the one of two PGNs needed by the CAN Calibration Protocol. It is sent by a tool to send queries or commands to a target ECU.";
CM_ BO_ 2559311614 "CCP Data Transmission Object
The DTO message is the one of two PGNs needed by the CAN Calibration Protocol. It is sent by an ECU in response tool to tool queries or commands.";
CM_ BO_ 2558983934 "Switched Power Outputs Command
The switched power outputs command is sent to the Power Distribution Module (PDM) to change the state of the PDM's switched power outputs.
This command is sent to the PDM as needed to change the power outputs, but no ...";
CM_ SG_ 2558983934 SwitchedPowerOutput18Cmd "Desired state of Switched Power Output #18. Used to set the desired state.

00b = Output off
01b = Output on
10b = Reserved
11b = Take no action";
CM_ SG_ 2558983934 SwitchedPowerOutput19Cmd "Desired state of Switched Power Output #19. Used to set the desired state.

00b = Output off
01b = Output on
10b = Reserved
11b = Take no action";
CM_ SG_ 2558983934 SwitchedPowerOutput20Cmd "Desired state of Switched Power Output #20. Used to set the desired state.

00b = Output off
01b = Output on
10b = Reserved
11b = Take no action";
CM_ SG_ 2558983934 SwitchedPowerOutput13Cmd "Desired state of Switched Power Output #13. Used to set the desired state.

00b = Output off
01b = Output on
10b = Reserved
11b = Take no action";
CM_ SG_ 2558983934 SwitchedPowerOutput14Cmd "Desired state of Switched Power Output #14. Used to set the desired state.

00b = Output off
01b = Output on
10b = Reserved
11b = Take no action";
CM_ SG_ 2558983934 SwitchedPowerOutput15Cmd "Desired state of Switched Power Output #15. Used to set the desired state.

00b = Output off
01b = Output on
10b = Reserved
11b = Take no action";
CM_ SG_ 2558983934 SwitchedPowerOutput16Cmd "Desired state of Switched Power Output #16. Used to set the desired state.

00b = Output off
01b = Output on
10b = Reserved
11b = Take no action";
CM_ SG_ 2558983934 SwitchedPowerOutput9Cmd "Desired state of Switched Power Output #9. Used to set the desired state.

00b = Output off
01b = Output on
10b = Reserved
11b = Take no action";
CM_ SG_ 2558983934 SwitchedPowerOutput10Cmd "Desired state of Switched Power Output #10. Used to set the desired state.

00b = Output off
01b = Output on
10b = Reserved
11b = Take no action";
CM_ SG_ 2558983934 SwitchedPowerOutput29Cmd "Desired state of Switched Power Output #29. Used to set the desired state.

00b = Output off
01b = Output on
10b = Reserved
11b = Take no action";
CM_ SG_ 2558983934 SwitchedPowerOutput30Cmd "Desired state of Switched Power Output #30. Used to set the desired state.

00b = Output off
01b = Output on
10b = Reserved
11b = Take no action";
CM_ SG_ 2558983934 SwitchedPowerOutput31Cmd "Desired state of Switched Power Output #31. Used to set the desired state.

00b = Output off
01b = Output on
10b = Reserved
11b = Take no action";
CM_ SG_ 2558983934 SwitchedPowerOutput32Cmd "Desired state of Switched Power Output #32. Used to set the desired state.

00b = Output off
01b = Output on
10b = Reserved
11b = Take no action";
CM_ SG_ 2558983934 SwitchedPowerOutput25Cmd "Desired state of Switched Power Output #25. Used to set the desired state.

00b = Output off
01b = Output on
10b = Reserved
11b = Take no action";
CM_ SG_ 2558983934 SwitchedPowerOutput26Cmd "Desired state of Switched Power Output #26. Used to set the desired state.

00b = Output off
01b = Output on
10b = Reserved
11b = Take no action";
CM_ SG_ 2558983934 SwitchedPowerOutput27Cmd "Desired state of Switched Power Output #27. Used to set the desired state.

00b = Output off
01b = Output on
10b = Reserved
11b = Take no action";
CM_ SG_ 2558983934 SwitchedPowerOutput28Cmd "Desired state of Switched Power Output #28. Used to set the desired state.

00b = Output off
01b = Output on
10b = Reserved
11b = Take no action";
CM_ SG_ 2558983934 SwitchedPowerOutput21Cmd "Desired state of Switched Power Output #21. Used to set the desired state.

00b = Output off
01b = Output on
10b = Reserved
11b = Take no action";
CM_ SG_ 2558983934 SwitchedPowerOutput22Cmd "Desired state of Switched Power Output #22. Used to set the desired state.

00b = Output off
01b = Output on
10b = Reserved
11b = Take no action";
CM_ SG_ 2558983934 SwitchedPowerOutput23Cmd "Desired state of Switched Power Output #23. Used to set the desired state.

00b = Output off
01b = Output on
10b = Reserved
11b = Take no action";
CM_ SG_ 2558983934 SwitchedPowerOutput24Cmd "Desired state of Switched Power Output #24. Used to set the desired state.

00b = Output off
01b = Output on
10b = Reserved
11b = Take no action";
CM_ SG_ 2558983934 SwitchedPowerOutput17Cmd "Desired state of Switched Power Output #17. Used to set the desired state.

00b = Output off
01b = Output on
10b = Reserved
11b = Take no action";
CM_ SG_ 2558983934 SwitchedPowerOutput11Cmd "Desired state of Switched Power Output #11. Used to set the desired state.

00b = Output off
01b = Output on
10b = Reserved
11b = Take no action";
CM_ SG_ 2558983934 SwitchedPowerOutput12Cmd "Desired state of Switched Power Output #12. Used to set the desired state.

00b = Output off
01b = Output on
10b = Reserved
11b = Take no action";
CM_ SG_ 2558983934 SwitchedPowerOutput5Cmd "Desired state of Switched Power Output #5. Used to set the desired state.

00b = Output off
01b = Output on
10b = Reserved
11b = Take no action";
CM_ SG_ 2558983934 SwitchedPowerOutput6Cmd "Desired state of Switched Power Output #6. Used to set the desired state.

00b = Output off
01b = Output on
10b = Reserved
11b = Take no action";
CM_ SG_ 2558983934 SwitchedPowerOutput7Cmd "Desired state of Switched Power Output #7. Used to set the desired state.

00b = Output off
01b = Output on
10b = Reserved
11b = Take no action";
CM_ SG_ 2558983934 SwitchedPowerOutput8Cmd "Desired state of Switched Power Output #8. Used to set the desired state.

00b = Output off
01b = Output on
10b = Reserved
11b = Take no action";
CM_ SG_ 2558983934 SwitchedPowerOutput1Cmd "Desired state of Switched Power Output #1. Used to set the desired state.

00b = Output off
01b = Output on
10b = Reserved
11b = Take no action";
CM_ SG_ 2558983934 SwitchedPowerOutput2Cmd "Desired state of Switched Power Output #2. Used to set the desired state.

00b = Output off
01b = Output on
10b = Reserved
11b = Take no action";
CM_ SG_ 2558983934 SwitchedPowerOutput3Cmd "Desired state of Switched Power Output #3. Used to set the desired state.

00b = Output off
01b = Output on
10b = Reserved
11b = Take no action";
CM_ SG_ 2558983934 SwitchedPowerOutput4Cmd "Desired state of Switched Power Output #4. Used to set the desired state.

00b = Output off
01b = Output on
10b = Reserved
11b = Take no action";
CM_ BO_ 2349727486 "Transmission Control 2
Used to communicate transmission control information";
CM_ SG_ 2349727486 CoastModeDisReq "Parameter indicates the desire of the operator or other vehicle system to disable Transmission Coast Mode, a function where the transmission internally disconnects from the driveline in order to reduce engine and transmission parastic drag while the ...";
CM_ SG_ 2349727486 DisengageDiffLockReqRearAxle3 "Command signal used to disengage the various differential locks, e.g., to allow an undistributed individual wheel control by ABS. The differential locks are located as defined in Figure SPN 564.  [Should expand the text for finding the figure].
00b ...";
CM_ SG_ 2349727486 Mode20 "Indicates whether transmission mode 20 is enabled.  Modes are manufacturer specific and are not necessarily mutually exclusive.  See also SPN 12948.

00b = Disable
01b = Enable
10b = Reserved
11b = Take no action";
CM_ SG_ 2349727486 Mode19 "Indicates whether transmission mode 19 is enabled.  Modes are manufacturer specific and are not necessarily mutually exclusive.  See also SPN 12947.

00b = Disable
01b = Enable
10b = Reserved
11b = Take no action";
CM_ SG_ 2349727486 Mode18 "Indicates whether transmission mode 18 is enabled.  Modes are manufacturer specific and are not necessarily mutually exclusive.  See also SPN 12946.

00b = Disable
01b = Enable
10b = Reserved
11b = Take no action";
CM_ SG_ 2349727486 Mode17 "Indicates whether transmission mode 17 is enabled.  Modes are manufacturer specific and are not necessarily mutually exclusive.  See also SPN 12945.

00b = Disable
01b = Enable
10b = Reserved
11b = Take no action";
CM_ SG_ 2349727486 Mode16 "Indicates whether transmission mode 16 is enabled.  Modes are manufacturer specific and are not necessarily mutually exclusive.  See also SPN 12944.

00b = Disable
01b = Enable
10b = Reserved
11b = Take no action";
CM_ SG_ 2349727486 Mode15 "Indicates whether transmission mode 15 is enabled.  Modes are manufacturer specific and are not necessarily mutually exclusive.  See also SPN 12943.

00b = Disable
01b = Enable
10b = Reserved
11b = Take no action";
CM_ SG_ 2349727486 Mode14 "Indicates whether transmission mode 14 is enabled.  Modes are manufacturer specific and are not necessarily mutually exclusive.  See also SPN 12942.

00b = Disable
01b = Enable
10b = Reserved
11b = Take no action";
CM_ SG_ 2349727486 Mode13 "Indicates whether transmission mode 13 is enabled.  Modes are manufacturer specific and are not necessarily mutually exclusive.  See also SPN 12941.

00b = Disable
01b = Enable
10b = Reserved
11b = Take no action";
CM_ SG_ 2349727486 Mode12 "Indicates whether transmission mode 12 is enabled.  Modes are manufacturer specific and are not necessarily mutually exclusive.  See also SPN 12940.

00b = Disable
01b = Enable
10b = Reserved
11b = Take no action";
CM_ SG_ 2349727486 Mode11 "Indicates whether transmission mode 11 is enabled.  Modes are manufacturer specific and are not necessarily mutually exclusive.  See also SPN 12939.

00b = Disable
01b = Enable
10b = Reserved
11b = Take no action";
CM_ SG_ 2349727486 SelectedMaxGearLmtActReq "When this parameter transitions from 00b to 01b, the transmission will set a maximum gear limit that is equal to the current operating gear. This limit only applies to the current operating direction, i.e. forward or reverse. Under normal ...";
CM_ SG_ 2349727486 ReqReverseLaunchGear "Initial Reverse gear for the transmission to start out in when the vehicle is launched from a standing stop, as specified by the vehicle operator or vehicle system. Automatic transmissions typically default to starting out in 1st Reverse. However, ...";
CM_ SG_ 2349727486 OutShaftBrkReq "This parameter requests that the transmission apply either internal or external braking systems for the purpose of stopping output shaft rotation. Such action is typically used to facilitate engagement of split-shaft PTOs or other components ...";
CM_ SG_ 2349727486 PreDefinedMaxGearActReq "This parameter requests that the transmission not operate in ranges above a pre-defined or calibrated range as configured in the transmission or other controller. For example, this parameter could be used to prevent operation in a overdrive range ...";
CM_ SG_ 2349727486 TransMode10 "Indicates whether transmission mode 10 is enabled. Modes are manufacturer specific and are not necessarily mutually exclusive. See also SPN 6568. 

00b = Disable
01b = Enable
10b = Reserved
11b = Take no action";
CM_ SG_ 2349727486 TransMode9 "Indicates whether transmission mode 9 is enabled. Modes are manufacturer specific and are not necessarily mutually exclusive. See also SPN 6567. 

00b = Disable
01b = Enable
10b = Reserved
11b = Take no action";
CM_ BO_ 2550988542 "Electronic Engine Controller 16";
CM_ SG_ 2550988542 ClutchEngageReqStatus "Indicates if the engine has an external request to establish its operating conditions to be appropriate for engagement of the transmission or gearbox.
00b = Engine does not have an external request
01b = Engine has an external request
10b = Error
 ...";
CM_ SG_ 2550988542 ReadyForClutchEngagementStatus "Indicates the engine operating conditions are appropriate for engagement of the transmission or gearbox clutch.

00b = Engine Not Ready For Clutch Engagement
01b = Engine is Ready For Clutch Engagement
10b = Error
11b = Not available";
CM_ SG_ 2550988542 AccelPedalPos3 "The ratio of actual position of the third analog engine speed/torque request input device (such as an accelerator pedal or throttle lever) to the maximum position of the input device.  This parameter is intended for the third accelerator control in ...";
CM_ BO_ 2550595326 "CANopen Application Message #2/1
Message to transmit data of the towed vehicle to the towing vehicle. See ISO 11992-3.";
CM_ BO_ 2550529790 "CANopen Application Message #1/1
Message to transmit data of the towing vehicle to the towed vehicle. See ISO 11992-3.";
CM_ BO_ 2566767358 "Electronic Engine Controller 14";
CM_ SG_ 2566767358 EngFuelIsolationCtrl "Control setting for fuel isolation. In a single injector dual fuel system when using just diesel fuel, diesel must not be allowed to migrate into the gaseous fuel system. When the fuel isolation valve is closed the engine uses dual fuel by allowing ...";
CM_ SG_ 2566767358 FuelType "Type of fuel currently being utilized by the vehicle
Data Byte - Scaling - External Display
00h = Not available - NONE
01h = Gasoline/petrol - GAS
02h = Methanol - METH
03h = Ethanol - ETH
04h = Diesel - DSL
05h = Liquefied Petroleum Gas ...";
CM_ SG_ 2566767358 EngFuelMassFlowRate "Mass of liquid fuel consumed by engine per unit of time.";
CM_ SG_ 2566767358 EngExhstGsRcrcltn1Valve2PosError "The position error of the Exhaust Gas Recirculation 1 valve 2, determined as the actual position (SPN 3821) minus the commanded position (SPN 3822).";
CM_ SG_ 2566767358 EngExhstGsRcrcltn1Valve1PosError "The position error of the Exhaust Gas Recirculation 1 valve, determined as the actual position (SPN 27) minus the commanded position (SPN 2791).";
CM_ BO_ 2566706686 "Aftertreatment 1 Diesel Exhaust Fluid Pump 1 Information
Contains information on Diesel Exhaust Fluid Pumps";
CM_ SG_ 2566706686 FilterLifeRem "Indicates an actual life remaining in percent of the aftertreatment 1 diesel exhaust fluid pump filter.

0% represents no life remaining in the filter and 100% represents a new filter with full life remaining.";
CM_ SG_ 2566706686 DEFXferPumpPurgeRelay "The state of the relay that controls the purging of the pump used to transfer diesel exhaust fluid from the bulk storage tank to a local tank.

00b = Off  (relay not energized)
01b = On  (relay energized)
10b = Error
11b = Not available";
CM_ SG_ 2566706686 PwrSupply "State signal which indicates when the aftertreatment 1 Diesel Exhaust Fluid (DEF) pump power output is being driven.  On means the ECU is powering the aftertreatment 1 DEF pump power output.  Note that the ECU is external to the DEF pump.
00b = Off
 ...";
CM_ SG_ 2566706686 DosingUnit1HtrRelay "The status of the relay that controls Aftertreatment 1 diesel exhaust fluid dosing Unit 1 Heater.

00b = Off
01b = On
10b = Error
11b = Not available";
CM_ SG_ 2566706686 TwoMotorSpd "Rotational speed of the motor driving the second pump for the diesel exhaust fluid used in aftertreatment system 1 (exhaust bank 1).";
CM_ SG_ 2566706686 Htr "Percentage of heating applied to the aftertreatment 1 diesel exhaust fluid pump heater. A value of 0% means no heating applied, a value of 100% means full heating applied. The diesel exhaust fluid pump heater warms the diesel exhaust fluid in the ...";
CM_ BO_ 2566705406 "Engine Particulate Sensor Information";
CM_ SG_ 2566705406 A1ParticulateSnsrCur "Raw aftertreatment 1 PM sensor electrical current reading.

Note: A value of FB00h shall be provided when ambient or engine operating conditions do not permit the sensor to operate in data collection mode.";
CM_ SG_ 2566705406 A2ParticulateSnsr "The particulate sensor measures the mass concentration of particulate matter in the exhaust downstream of the DPF in exhaust bank 2.
Note: A value of FB00h shall be provided when ambient or engine operating conditions do not permit the sensor to ...";
CM_ SG_ 2566705406 A1ParticulateSnsr "The particulate sensor measures the mass concentration of particulate matter in the exhaust downstream of the DPF in exhaust bank 1.
Note: A value of FB00h shall be provided when ambient or engine operating conditions do not permit the sensor to ...";
CM_ BO_ 2566705150 "NOx Sensor Self-Diagnosis Request
Request to initiate the self-diagnosis of the NOx sensors implemented in the system.
This request may be sent at any time, but should not be sent if the status parameter indicates the self-diagnosis is not ...";
CM_ SG_ 2566705150 AFT2InNOxSnsrSelfDiagTrigger "Signal to trigger the self-diagnosis of NOx sensor Engine Exhaust Bank 2 (EEB2)
.  This sensor is located at the intake of the aftertreatment system if an aftertreatment system exists.
0000b = Diagnostic mode disabled
0001b = NOx Sensor EEB2 ...";
CM_ SG_ 2566705150 A2OutNOxSnsrSelfDiagTrigger "Signal to trigger the self-diagnosis of NOx sensor ATO2 (Aftertreatment Outlet Bank 2)
0000b = Diagnostic mode disabled
0001b = NOx Sensor ATO2 Self-diagnosis Request at Lambda=1.0
0010b = NOx Sensor ATO2 Self-diagnosis Request at partial load
 ...";
CM_ SG_ 2566705150 AFT1InNOxSnsrSelfDiagTrigger "Signal to trigger the self-diagnosis of NOx sensor Engine Exhaust Bank 1 (EEB1)
.  This sensor is located at the intake of the aftertreatment system if an aftertreatment system exists.
0000b = Diagnostic mode disabled
0001b = NOx Sensor EEB1 ...";
CM_ SG_ 2566705150 A1OutNOxSnsrSelfDiagTrigger "Signal to trigger the self-diagnosis of NOx sensor ATO1 (Aftertreatment Outlet Bank 1)
0000b = Diagnostic mode disabled
0001b = NOx Sensor ATO1 Self-diagnosis Request at Lambda=1.0
0010b = NOx Sensor ATO1 Self-diagnosis Request at partial load
 ...";
CM_ BO_ 2566704382 "Electronic Engine Controller 12
Engine Related Parameters";
CM_ SG_ 2566704382 A1Out2GasSnsrPwrSupply "State signal which indicates when the Aftertreatment 1 Outlet 2 Gas Sensor driver output is being driven.

00b = Off
01b = On: The ECU is powering the Aftertreatment 1 Outlet 2 Gas Sensor
10b = Error
11b = Unavailable";
CM_ SG_ 2566704382 AFT1In2GasSnsrPwrSupply "State signal which indicates when the Engine Exhaust 1  Gas Sensor 2 driver output is being driven.
This sensor is located at the engine exhaust in bank 2 and before the aftertreatment intake in exhaust bank 2, if an aftertreatment system exists.
 ...";
CM_ SG_ 2566704382 A2Out1GasSnsrPwrSupply "State signal which indicates when the Aftertreatment 2 Outlet 1 Gas Sensor driver output is being driven.  On means the ECU is powering the Aftertreatment 2 Outlet 1 Gas Sensor.  Note that the ECU is external to the sensor.
00b = Off
01b = On: The ...";
CM_ SG_ 2566704382 AFT2In1GasSnsrPwrSupply "State signal which indicates when the Engine Exhaust 2 Gas 1 Sensor driver output is being driven.  On means the ECU is powering the Engine Exhaust 2 Intake 1 Gas Sensor.  Note that the ECU is external to the sensor.
This sensor is located at the ...";
CM_ SG_ 2566704382 A1Out1GasSnsrPwrSupply "State signal which indicates when the Aftertreatment 1 Outlet 1 Gas Sensor driver output is being driven. On means the ECU is powering the Aftertreatment 1 Outlet 1 Gas Sensor. Note that the ECU is external to the sensor.
00b = Off
01b = On: The ...";
CM_ SG_ 2566704382 AFT1In1GasSnsrPwrSupply "State signal which indicates when the Engine Exhaust  1 Gas Sensor 1 driver output is being driven.  On means the ECU is powering the Engine Exhaust 1 Intake 1 Gas Sensor.  Note that the ECU is external to the sensor.
This sensor is located at the ...";
BA_DEF_ SG_  "GenSigInactiveValue" INT 0 0;
BA_DEF_ SG_  "SigType" ENUM  "Default","Range","RangeSigned","ASCII","Discrete","Control","ReferencePGN","DTC","StringDelimiter","StringLength","StringLengthControl","MessageCounter","MessageChecksum";
BA_DEF_ SG_  "GenSigStartValue" INT 0 2147483647;
BA_DEF_ SG_  "GenSigSendType" ENUM  "Cyclic","OnWrite","OnWriteWithRepetition","OnChange","OnChangeWithRepetition","IfActive","IfActiveWithRepetition","NoSigSendType";
BA_DEF_ SG_  "GenSigILSupport" ENUM  "No","Yes";
BA_DEF_ SG_  "SPN" INT 0 524287;
BA_DEF_ BO_  "J1939CPgSendTimeout" INT -1 3600000;
BA_DEF_ BO_  "J1939CPgTOS" INT 0 7;
BA_DEF_ BO_  "J1939PgAppearanceOnBus" ENUM  "Default","CAN_Extended","CANFD_Extended";
BA_DEF_ BO_  "FsJ1939UseCrcAndCounter" STRING ;
BA_DEF_ BO_  "TpJ1939VarDlc" ENUM  "No","Yes";
BA_DEF_ BO_  "GenMsgNrOfRepetition" INT 0 1000000;
BA_DEF_ BO_  "GenMsgCycleTimeFast" INT 0 3600000;
BA_DEF_ BO_  "GenMsgFastOnStart" INT 0 100000;
BA_DEF_ BO_  "GenMsgStartDelayTime" INT 0 100000;
BA_DEF_ BO_  "GenMsgILSupport" ENUM  "No","Yes";
BA_DEF_ BO_  "GenMsgDelayTime" INT 0 1000;
BA_DEF_ BO_  "GenMsgRequestable" INT 0 1;
BA_DEF_ BO_  "GenMsgSendType" ENUM  "cyclic","NotUsed","NotUsed","NotUsed","NotUsed","NotUsed","NotUsed","IfActive","noMsgSendType";
BA_DEF_ BO_  "VFrameFormat" ENUM  "StandardCAN","ExtendedCAN","reserved","J1939PG","reserved","reserved","reserved","reserved","reserved","reserved","reserved","reserved","reserved","reserved","StandardCAN_FD","ExtendedCAN_FD";
BA_DEF_ BO_  "SingleFrame" INT 0 1;
BA_DEF_ BO_  "GenMsgCycleTime" INT 0 3600000;
BA_DEF_ SG_  "SystemSignalLongSymbol" STRING ;
BA_DEF_DEF_  "GenSigInactiveValue" 0;
BA_DEF_DEF_  "SigType" "Default";
BA_DEF_DEF_  "GenSigStartValue" 0;
BA_DEF_DEF_  "GenSigSendType" "NoSigSendType";
BA_DEF_DEF_  "GenSigILSupport" "Yes";
BA_DEF_DEF_  "SPN" 0;
BA_DEF_DEF_  "J1939CPgSendTimeout" -1;
BA_DEF_DEF_  "J1939CPgTOS" 2;
BA_DEF_DEF_  "J1939PgAppearanceOnBus" "Default";
BA_DEF_DEF_  "FsJ1939UseCrcAndCounter" "";
BA_DEF_DEF_  "TpJ1939VarDlc" "No";
BA_DEF_DEF_  "GenMsgNrOfRepetition" 0;
BA_DEF_DEF_  "GenMsgCycleTimeFast" 0;
BA_DEF_DEF_  "GenMsgFastOnStart" 0;
BA_DEF_DEF_  "GenMsgStartDelayTime" 0;
BA_DEF_DEF_  "GenMsgILSupport" "Yes";
BA_DEF_DEF_  "GenMsgDelayTime" 0;
BA_DEF_DEF_  "GenMsgRequestable" 1;
BA_DEF_DEF_  "GenMsgSendType" "noMsgSendType";
BA_DEF_DEF_  "VFrameFormat" "J1939PG";
BA_DEF_DEF_  "SingleFrame" 1;
BA_DEF_DEF_  "GenMsgCycleTime" 0;
BA_DEF_DEF_  "SystemSignalLongSymbol" "";
BA_ "GenMsgSendType" BO_ 2364553726 0;
BA_ "GenMsgCycleTime" BO_ 2364553726 20;
BA_ "GenMsgSendType" BO_ 2364553470 0;
BA_ "GenMsgCycleTime" BO_ 2364553470 20;
BA_ "GenMsgSendType" BO_ 2364553214 0;
BA_ "GenMsgCycleTime" BO_ 2364553214 100;
BA_ "GenMsgSendType" BO_ 2364546814 0;
BA_ "GenMsgCycleTime" BO_ 2364546814 20;
BA_ "GenMsgSendType" BO_ 2565872638 0;
BA_ "GenMsgCycleTime" BO_ 2565872638 10;
BA_ "TpJ1939VarDlc" BO_ 2565865214 1;
BA_ "GenMsgSendType" BO_ 2231031806 0;
BA_ "GenMsgCycleTime" BO_ 2231031806 50;
BA_ "GenMsgDelayTime" BO_ 2559049470 100;
BA_ "GenMsgSendType" BO_ 2559049470 0;
BA_ "GenMsgCycleTime" BO_ 2559049470 1000;
BA_ "FsJ1939UseCrcAndCounter" BO_ 2349596414 "Cd";
BA_ "GenMsgDelayTime" BO_ 2349596414 10;
BA_ "GenMsgSendType" BO_ 2349596414 0;
BA_ "GenMsgCycleTime" BO_ 2349596414 50;
BA_ "GenMsgRequestable" BO_ 2563702526 0;
BA_ "GenMsgRequestable" BO_ 2563636990 0;
BA_ "GenMsgRequestable" BO_ 2563309310 0;
BA_ "GenMsgRequestable" BO_ 2563243774 0;
BA_ "GenMsgSendType" BO_ 2560294654 0;
BA_ "GenMsgCycleTime" BO_ 2560294654 5000;
BA_ "GenMsgDelayTime" BO_ 2558983934 100;
BA_ "GenMsgSendType" BO_ 2558983934 0;
BA_ "GenMsgCycleTime" BO_ 2558983934 100;
BA_ "GenMsgSendType" BO_ 2349727486 0;
BA_ "GenMsgCycleTime" BO_ 2349727486 50;
BA_ "GenMsgSendType" BO_ 2550988542 0;
BA_ "GenMsgCycleTime" BO_ 2550988542 50;
BA_ "GenMsgSendType" BO_ 2566706686 0;
BA_ "GenMsgCycleTime" BO_ 2566706686 500;
BA_ "SigType" SG_ 2498777086 EngCyl2AverageCombustionDuration 1;
BA_ "SPN" SG_ 2498777086 EngCyl2AverageCombustionDuration 6490;
BA_ "SigType" SG_ 2498777086 EngCyl2AvrgCntrOfCmbustionTiming 1;
BA_ "SPN" SG_ 2498777086 EngCyl2AvrgCntrOfCmbustionTiming 6489;
BA_ "SigType" SG_ 2498777086 EngCyl2AvrgStrtOfCmbustionTiming 1;
BA_ "SPN" SG_ 2498777086 EngCyl2AvrgStrtOfCmbustionTiming 6488;
BA_ "SigType" SG_ 2498777086 EngCyl2IndctedMeanEffectivePress 1;
BA_ "SPN" SG_ 2498777086 EngCyl2IndctedMeanEffectivePress 6487;
BA_ "SigType" SG_ 2498776830 EngCyl1AverageCombustionDuration 1;
BA_ "SPN" SG_ 2498776830 EngCyl1AverageCombustionDuration 6486;
BA_ "SigType" SG_ 2498776830 EngCyl1AvrgCntrOfCmbustionTiming 1;
BA_ "SPN" SG_ 2498776830 EngCyl1AvrgCntrOfCmbustionTiming 6485;
BA_ "SigType" SG_ 2498776830 EngCyl1AvrgStrtOfCmbustionTiming 1;
BA_ "SPN" SG_ 2498776830 EngCyl1AvrgStrtOfCmbustionTiming 6484;
BA_ "SigType" SG_ 2498776830 EngCyl1IndctedMeanEffectivePress 1;
BA_ "SPN" SG_ 2498776830 EngCyl1IndctedMeanEffectivePress 6483;
BA_ "SigType" SG_ 2364558846 MaxPressIncreaseRate 1;
BA_ "SPN" SG_ 2364558846 MaxPressIncreaseRate 7648;
BA_ "SigType" SG_ 2364558846 LowFreqKnockLvl 1;
BA_ "SPN" SG_ 2364558846 LowFreqKnockLvl 7628;
BA_ "SPN" SG_ 2364558846 EngCyl20PrssSensorPreliminaryFMI 6475;
BA_ "SigType" SG_ 2364558846 EngCyl20SynchronousKnockLevel 1;
BA_ "SPN" SG_ 2364558846 EngCyl20SynchronousKnockLevel 6474;
BA_ "SigType" SG_ 2364558846 EngCyl20PeakPress 1;
BA_ "SPN" SG_ 2364558846 EngCyl20PeakPress 6473;
BA_ "SigType" SG_ 2364558846 EngCyl20HeatRelease 1;
BA_ "SPN" SG_ 2364558846 EngCyl20HeatRelease 6472;
BA_ "SigType" SG_ 2364558590 MaxPressIncreaseRate 1;
BA_ "SPN" SG_ 2364558590 MaxPressIncreaseRate 7647;
BA_ "SigType" SG_ 2364558590 LowFreqKnockLvl 1;
BA_ "SPN" SG_ 2364558590 LowFreqKnockLvl 7627;
BA_ "SPN" SG_ 2364558590 EngCyl19PrssSensorPreliminaryFMI 6471;
BA_ "SigType" SG_ 2364558590 EngCyl19SynchronousKnockLevel 1;
BA_ "SPN" SG_ 2364558590 EngCyl19SynchronousKnockLevel 6470;
BA_ "SigType" SG_ 2364558590 EngCyl19PeakPress 1;
BA_ "SPN" SG_ 2364558590 EngCyl19PeakPress 6469;
BA_ "SigType" SG_ 2364558590 EngCyl19HeatRelease 1;
BA_ "SPN" SG_ 2364558590 EngCyl19HeatRelease 6468;
BA_ "SigType" SG_ 2364558334 MaxPressIncreaseRate 1;
BA_ "SPN" SG_ 2364558334 MaxPressIncreaseRate 7646;
BA_ "SigType" SG_ 2364558334 LowFreqKnockLvl 1;
BA_ "SPN" SG_ 2364558334 LowFreqKnockLvl 7626;
BA_ "SPN" SG_ 2364558334 EngCyl18PrssSensorPreliminaryFMI 6467;
BA_ "SigType" SG_ 2364558334 EngCyl18SynchronousKnockLevel 1;
BA_ "SPN" SG_ 2364558334 EngCyl18SynchronousKnockLevel 6466;
BA_ "SigType" SG_ 2364558334 EngCyl18PeakPress 1;
BA_ "SPN" SG_ 2364558334 EngCyl18PeakPress 6465;
BA_ "SigType" SG_ 2364558334 EngCyl18HeatRelease 1;
BA_ "SPN" SG_ 2364558334 EngCyl18HeatRelease 6464;
BA_ "SigType" SG_ 2364558078 MaxPressIncreaseRate 1;
BA_ "SPN" SG_ 2364558078 MaxPressIncreaseRate 7645;
BA_ "SigType" SG_ 2364558078 LowFreqKnockLvl 1;
BA_ "SPN" SG_ 2364558078 LowFreqKnockLvl 7625;
BA_ "SPN" SG_ 2364558078 EngCyl17PrssSensorPreliminaryFMI 6463;
BA_ "SigType" SG_ 2364558078 EngCyl17SynchronousKnockLevel 1;
BA_ "SPN" SG_ 2364558078 EngCyl17SynchronousKnockLevel 6462;
BA_ "SigType" SG_ 2364558078 EngCyl17PeakPress 1;
BA_ "SPN" SG_ 2364558078 EngCyl17PeakPress 6461;
BA_ "SigType" SG_ 2364558078 EngCyl17HeatRelease 1;
BA_ "SPN" SG_ 2364558078 EngCyl17HeatRelease 6460;
BA_ "SigType" SG_ 2364557822 MaxPressIncreaseRate 1;
BA_ "SPN" SG_ 2364557822 MaxPressIncreaseRate 7644;
BA_ "SigType" SG_ 2364557822 LowFreqKnockLvl 1;
BA_ "SPN" SG_ 2364557822 LowFreqKnockLvl 7624;
BA_ "SPN" SG_ 2364557822 EngCyl16PrssSensorPreliminaryFMI 6459;
BA_ "SigType" SG_ 2364557822 EngCyl16SynchronousKnockLevel 1;
BA_ "SPN" SG_ 2364557822 EngCyl16SynchronousKnockLevel 6458;
BA_ "SigType" SG_ 2364557822 EngCyl16PeakPress 1;
BA_ "SPN" SG_ 2364557822 EngCyl16PeakPress 6457;
BA_ "SigType" SG_ 2364557822 EngCyl16HeatRelease 1;
BA_ "SPN" SG_ 2364557822 EngCyl16HeatRelease 6456;
BA_ "SigType" SG_ 2364557566 MaxPressIncreaseRate 1;
BA_ "SPN" SG_ 2364557566 MaxPressIncreaseRate 7643;
BA_ "SigType" SG_ 2364557566 LowFreqKnockLvl 1;
BA_ "SPN" SG_ 2364557566 LowFreqKnockLvl 7623;
BA_ "SPN" SG_ 2364557566 EngCyl15PrssSensorPreliminaryFMI 6455;
BA_ "SigType" SG_ 2364557566 EngCyl15SynchronousKnockLevel 1;
BA_ "SPN" SG_ 2364557566 EngCyl15SynchronousKnockLevel 6454;
BA_ "SigType" SG_ 2364557566 EngCyl15PeakPress 1;
BA_ "SPN" SG_ 2364557566 EngCyl15PeakPress 6453;
BA_ "SigType" SG_ 2364557566 EngCyl15HeatRelease 1;
BA_ "SPN" SG_ 2364557566 EngCyl15HeatRelease 6452;
BA_ "SigType" SG_ 2364557310 MaxPressIncreaseRate 1;
BA_ "SPN" SG_ 2364557310 MaxPressIncreaseRate 7642;
BA_ "SigType" SG_ 2364557310 LowFreqKnockLvl 1;
BA_ "SPN" SG_ 2364557310 LowFreqKnockLvl 7622;
BA_ "SPN" SG_ 2364557310 EngCyl14PrssSensorPreliminaryFMI 6451;
BA_ "SigType" SG_ 2364557310 EngCyl14SynchronousKnockLevel 1;
BA_ "SPN" SG_ 2364557310 EngCyl14SynchronousKnockLevel 6450;
BA_ "SigType" SG_ 2364557310 EngCyl14PeakPress 1;
BA_ "SPN" SG_ 2364557310 EngCyl14PeakPress 6449;
BA_ "SigType" SG_ 2364557310 EngCyl14HeatRelease 1;
BA_ "SPN" SG_ 2364557310 EngCyl14HeatRelease 6448;
BA_ "SigType" SG_ 2364557054 MaxPressIncreaseRate 1;
BA_ "SPN" SG_ 2364557054 MaxPressIncreaseRate 7641;
BA_ "SigType" SG_ 2364557054 LowFreqKnockLvl 1;
BA_ "SPN" SG_ 2364557054 LowFreqKnockLvl 7621;
BA_ "SPN" SG_ 2364557054 EngCyl13PrssSensorPreliminaryFMI 6447;
BA_ "SigType" SG_ 2364557054 EngCyl13SynchronousKnockLevel 1;
BA_ "SPN" SG_ 2364557054 EngCyl13SynchronousKnockLevel 6446;
BA_ "SigType" SG_ 2364557054 EngCyl13PeakPress 1;
BA_ "SPN" SG_ 2364557054 EngCyl13PeakPress 6445;
BA_ "SigType" SG_ 2364557054 EngCyl13HeatRelease 1;
BA_ "SPN" SG_ 2364557054 EngCyl13HeatRelease 6444;
BA_ "SigType" SG_ 2364556798 MaxPressIncreaseRate 1;
BA_ "SPN" SG_ 2364556798 MaxPressIncreaseRate 7640;
BA_ "SigType" SG_ 2364556798 LowFreqKnockLvl 1;
BA_ "SPN" SG_ 2364556798 LowFreqKnockLvl 7620;
BA_ "SPN" SG_ 2364556798 EngCyl12PrssSensorPreliminaryFMI 6443;
BA_ "SigType" SG_ 2364556798 EngCyl12SynchronousKnockLevel 1;
BA_ "SPN" SG_ 2364556798 EngCyl12SynchronousKnockLevel 6442;
BA_ "SigType" SG_ 2364556798 EngCyl12PeakPress 1;
BA_ "SPN" SG_ 2364556798 EngCyl12PeakPress 6441;
BA_ "SigType" SG_ 2364556798 EngCyl12HeatRelease 1;
BA_ "SPN" SG_ 2364556798 EngCyl12HeatRelease 6440;
BA_ "SigType" SG_ 2364556542 MaxPressIncreaseRate 1;
BA_ "SPN" SG_ 2364556542 MaxPressIncreaseRate 7639;
BA_ "SigType" SG_ 2364556542 LowFreqKnockLvl 1;
BA_ "SPN" SG_ 2364556542 LowFreqKnockLvl 7619;
BA_ "SPN" SG_ 2364556542 EngCyl11PrssSensorPreliminaryFMI 6439;
BA_ "SigType" SG_ 2364556542 EngCyl11SynchronousKnockLevel 1;
BA_ "SPN" SG_ 2364556542 EngCyl11SynchronousKnockLevel 6438;
BA_ "SigType" SG_ 2364556542 EngCyl11PeakPress 1;
BA_ "SPN" SG_ 2364556542 EngCyl11PeakPress 6437;
BA_ "SigType" SG_ 2364556542 EngCyl11HeatRelease 1;
BA_ "SPN" SG_ 2364556542 EngCyl11HeatRelease 6436;
BA_ "SigType" SG_ 2364556286 MaxPressIncreaseRate 1;
BA_ "SPN" SG_ 2364556286 MaxPressIncreaseRate 7638;
BA_ "SigType" SG_ 2364556286 LowFreqKnockLvl 1;
BA_ "SPN" SG_ 2364556286 LowFreqKnockLvl 7618;
BA_ "SPN" SG_ 2364556286 EngCyl10PrssSensorPreliminaryFMI 6435;
BA_ "SigType" SG_ 2364556286 EngCyl10SynchronousKnockLevel 1;
BA_ "SPN" SG_ 2364556286 EngCyl10SynchronousKnockLevel 6434;
BA_ "SigType" SG_ 2364556286 EngCyl10PeakPress 1;
BA_ "SPN" SG_ 2364556286 EngCyl10PeakPress 6433;
BA_ "SigType" SG_ 2364556286 EngCyl10HeatRelease 1;
BA_ "SPN" SG_ 2364556286 EngCyl10HeatRelease 6432;
BA_ "SigType" SG_ 2364556030 MaxPressIncreaseRate 1;
BA_ "SPN" SG_ 2364556030 MaxPressIncreaseRate 7637;
BA_ "SigType" SG_ 2364556030 LowFreqKnockLvl 1;
BA_ "SPN" SG_ 2364556030 LowFreqKnockLvl 7617;
BA_ "SPN" SG_ 2364556030 EngCyl9PressSensorPreliminaryFMI 6431;
BA_ "SigType" SG_ 2364556030 EngCyl9SynchronousKnockLevel 1;
BA_ "SPN" SG_ 2364556030 EngCyl9SynchronousKnockLevel 6430;
BA_ "SigType" SG_ 2364556030 EngCyl9PeakPress 1;
BA_ "SPN" SG_ 2364556030 EngCyl9PeakPress 6429;
BA_ "SigType" SG_ 2364556030 EngCyl9HeatRelease 1;
BA_ "SPN" SG_ 2364556030 EngCyl9HeatRelease 6428;
BA_ "SigType" SG_ 2364555774 MaxPressIncreaseRate 1;
BA_ "SPN" SG_ 2364555774 MaxPressIncreaseRate 7636;
BA_ "SigType" SG_ 2364555774 LowFreqKnockLvl 1;
BA_ "SPN" SG_ 2364555774 LowFreqKnockLvl 7616;
BA_ "SPN" SG_ 2364555774 EngCyl8PressSensorPreliminaryFMI 6427;
BA_ "SigType" SG_ 2364555774 EngCyl8SynchronousKnockLevel 1;
BA_ "SPN" SG_ 2364555774 EngCyl8SynchronousKnockLevel 6426;
BA_ "SigType" SG_ 2364555774 EngCyl8PeakPress 1;
BA_ "SPN" SG_ 2364555774 EngCyl8PeakPress 6425;
BA_ "SigType" SG_ 2364555774 EngCyl8HeatRelease 1;
BA_ "SPN" SG_ 2364555774 EngCyl8HeatRelease 6424;
BA_ "SigType" SG_ 2364555518 MaxPressIncreaseRate 1;
BA_ "SPN" SG_ 2364555518 MaxPressIncreaseRate 7635;
BA_ "SigType" SG_ 2364555518 LowFreqKnockLvl 1;
BA_ "SPN" SG_ 2364555518 LowFreqKnockLvl 7615;
BA_ "SPN" SG_ 2364555518 EngCyl7PressSensorPreliminaryFMI 6423;
BA_ "SigType" SG_ 2364555518 EngCyl7SynchronousKnockLevel 1;
BA_ "SPN" SG_ 2364555518 EngCyl7SynchronousKnockLevel 6422;
BA_ "SigType" SG_ 2364555518 EngCyl7PeakPress 1;
BA_ "SPN" SG_ 2364555518 EngCyl7PeakPress 6421;
BA_ "SigType" SG_ 2364555518 EngCyl7HeatRelease 1;
BA_ "SPN" SG_ 2364555518 EngCyl7HeatRelease 6420;
BA_ "SigType" SG_ 2364555262 MaxPressIncreaseRate 1;
BA_ "SPN" SG_ 2364555262 MaxPressIncreaseRate 7634;
BA_ "SigType" SG_ 2364555262 LowFreqKnockLvl 1;
BA_ "SPN" SG_ 2364555262 LowFreqKnockLvl 7614;
BA_ "SPN" SG_ 2364555262 EngCyl6PressSensorPreliminaryFMI 6419;
BA_ "SigType" SG_ 2364555262 EngCyl6SynchronousKnockLevel 1;
BA_ "SPN" SG_ 2364555262 EngCyl6SynchronousKnockLevel 6418;
BA_ "SigType" SG_ 2364555262 EngCyl6PeakPress 1;
BA_ "SPN" SG_ 2364555262 EngCyl6PeakPress 6417;
BA_ "SigType" SG_ 2364555262 EngCyl6HeatRelease 1;
BA_ "SPN" SG_ 2364555262 EngCyl6HeatRelease 6416;
BA_ "SigType" SG_ 2364555006 MaxPressIncreaseRate 1;
BA_ "SPN" SG_ 2364555006 MaxPressIncreaseRate 7633;
BA_ "SigType" SG_ 2364555006 LowFreqKnockLvl 1;
BA_ "SPN" SG_ 2364555006 LowFreqKnockLvl 7613;
BA_ "SPN" SG_ 2364555006 EngCyl5PressSensorPreliminaryFMI 6415;
BA_ "SigType" SG_ 2364555006 EngCyl5SynchronousKnockLevel 1;
BA_ "SPN" SG_ 2364555006 EngCyl5SynchronousKnockLevel 6414;
BA_ "SigType" SG_ 2364555006 EngCyl5PeakPress 1;
BA_ "SPN" SG_ 2364555006 EngCyl5PeakPress 6413;
BA_ "SigType" SG_ 2364555006 EngCyl5HeatRelease 1;
BA_ "SPN" SG_ 2364555006 EngCyl5HeatRelease 6412;
BA_ "SigType" SG_ 2364554750 MaxPressIncreaseRate 1;
BA_ "SPN" SG_ 2364554750 MaxPressIncreaseRate 7632;
BA_ "SigType" SG_ 2364554750 LowFreqKnockLvl 1;
BA_ "SPN" SG_ 2364554750 LowFreqKnockLvl 7612;
BA_ "SPN" SG_ 2364554750 EngCyl4PressSensorPreliminaryFMI 6411;
BA_ "SigType" SG_ 2364554750 EngCyl4SynchronousKnockLevel 1;
BA_ "SPN" SG_ 2364554750 EngCyl4SynchronousKnockLevel 6410;
BA_ "SigType" SG_ 2364554750 EngCyl4PeakPress 1;
BA_ "SPN" SG_ 2364554750 EngCyl4PeakPress 6409;
BA_ "SigType" SG_ 2364554750 EngCyl4HeatRelease 1;
BA_ "SPN" SG_ 2364554750 EngCyl4HeatRelease 6408;
BA_ "SigType" SG_ 2364554494 MaxPressIncreaseRate 1;
BA_ "SPN" SG_ 2364554494 MaxPressIncreaseRate 7631;
BA_ "SigType" SG_ 2364554494 LowFreqKnockLvl 1;
BA_ "SPN" SG_ 2364554494 LowFreqKnockLvl 7611;
BA_ "SPN" SG_ 2364554494 EngCyl3PressSensorPreliminaryFMI 6407;
BA_ "SigType" SG_ 2364554494 EngCyl3SynchronousKnockLevel 1;
BA_ "SPN" SG_ 2364554494 EngCyl3SynchronousKnockLevel 6406;
BA_ "SigType" SG_ 2364554494 EngCyl3PeakPress 1;
BA_ "SPN" SG_ 2364554494 EngCyl3PeakPress 6405;
BA_ "SigType" SG_ 2364554494 EngCyl3HeatRelease 1;
BA_ "SPN" SG_ 2364554494 EngCyl3HeatRelease 6404;
BA_ "SigType" SG_ 2364554238 MaxPressIncreaseRate 1;
BA_ "SPN" SG_ 2364554238 MaxPressIncreaseRate 7630;
BA_ "SigType" SG_ 2364554238 LowFreqKnockLvl 1;
BA_ "SPN" SG_ 2364554238 LowFreqKnockLvl 7610;
BA_ "SPN" SG_ 2364554238 EngCyl2PressSensorPreliminaryFMI 6403;
BA_ "SigType" SG_ 2364554238 EngCyl2SynchronousKnockLevel 1;
BA_ "SPN" SG_ 2364554238 EngCyl2SynchronousKnockLevel 6402;
BA_ "SigType" SG_ 2364554238 EngCyl2PeakPress 1;
BA_ "SPN" SG_ 2364554238 EngCyl2PeakPress 6401;
BA_ "SigType" SG_ 2364554238 EngCyl2HeatRelease 1;
BA_ "SPN" SG_ 2364554238 EngCyl2HeatRelease 6400;
BA_ "SigType" SG_ 2364553982 MaxPressIncreaseRate 1;
BA_ "SPN" SG_ 2364553982 MaxPressIncreaseRate 7629;
BA_ "SigType" SG_ 2364553982 LowFreqKnockLvl 1;
BA_ "SPN" SG_ 2364553982 LowFreqKnockLvl 7609;
BA_ "SPN" SG_ 2364553982 EngCyl1PressSensorPreliminaryFMI 6399;
BA_ "SigType" SG_ 2364553982 EngCyl1SynchronousKnockLevel 1;
BA_ "SPN" SG_ 2364553982 EngCyl1SynchronousKnockLevel 6398;
BA_ "SigType" SG_ 2364553982 EngCyl1PeakPress 1;
BA_ "SPN" SG_ 2364553982 EngCyl1PeakPress 6397;
BA_ "SigType" SG_ 2364553982 EngCyl1HeatRelease 1;
BA_ "SPN" SG_ 2364553982 EngCyl1HeatRelease 6396;
BA_ "SigType" SG_ 2364553726 FuelSys2TotalInMassAirFlowRate 1;
BA_ "SPN" SG_ 2364553726 FuelSys2TotalInMassAirFlowRate 8310;
BA_ "SigType" SG_ 2364553726 EngTotalIntakeMassAirFlowRate 1;
BA_ "SPN" SG_ 2364553726 EngTotalIntakeMassAirFlowRate 6393;
BA_ "SigType" SG_ 2364553726 EngDesiredAirFuelRatio 1;
BA_ "SPN" SG_ 2364553726 EngDesiredAirFuelRatio 6392;
BA_ "SigType" SG_ 2364553470 EngCylTorque 1;
BA_ "SPN" SG_ 2364553470 EngCylTorque 6389;
BA_ "SigType" SG_ 2364553470 EngCylDieselMassFlowRateCmd 1;
BA_ "SPN" SG_ 2364553470 EngCylDieselMassFlowRateCmd 6388;
BA_ "SigType" SG_ 2364553470 EngCylGasMassFlowRateCmd 1;
BA_ "SPN" SG_ 2364553470 EngCylGasMassFlowRateCmd 6387;
BA_ "SigType" SG_ 2364553470 EngGasFuelPercentageCmd 1;
BA_ "SPN" SG_ 2364553470 EngGasFuelPercentageCmd 6386;
BA_ "SigType" SG_ 2364553470 EngDualFuelModeCmd 5;
BA_ "SPN" SG_ 2364553470 EngDualFuelModeCmd 6792;
BA_ "SPN" SG_ 2364553214 EngTrbCmprssrBlwffActtr1OprtnStt 6316;
BA_ "SigType" SG_ 2364553214 EngTrbCmprssrBlowoffActuator1Pos 1;
BA_ "SPN" SG_ 2364553214 EngTrbCmprssrBlowoffActuator1Pos 6315;
BA_ "SigType" SG_ 2364553214 EngTrbCmprssrBlwffActtr1DsredPos 1;
BA_ "SPN" SG_ 2364553214 EngTrbCmprssrBlwffActtr1DsredPos 6314;
BA_ "SigType" SG_ 2364553214 EngTrbCmprssrBlwoffActuator1Temp 1;
BA_ "SPN" SG_ 2364553214 EngTrbCmprssrBlwoffActuator1Temp 6313;
BA_ "SPN" SG_ 2364553214 EngTrbCmprssrBlwffActtr1TmpSttus 6312;
BA_ "SPN" SG_ 2364553214 EngTrbCmprssrBlwffActtr1PrlmnryF 6311;
BA_ "SPN" SG_ 2565874430 PersistentLimitStatus 4307;
BA_ "SPN" SG_ 2565874430 MachineSelectedSpeedSource 4308;
BA_ "SigType" SG_ 2565874430 MachineSelectedDirection 4;
BA_ "SPN" SG_ 2565874430 MachineSelectedDirection 4309;
BA_ "SPN" SG_ 2565874430 MachineSelectedDistance 4306;
BA_ "SPN" SG_ 2565874430 MachineSelectedSpeed 4305;
BA_ "SigType" SG_ 2364546814 EngLoadSetpointReq 1;
BA_ "SPN" SG_ 2364546814 EngLoadSetpointReq 8430;
BA_ "SigType" SG_ 2364546814 EngSelfInducedDerateInh 5;
BA_ "SPN" SG_ 2364546814 EngSelfInducedDerateInh 8429;
BA_ "SigType" SG_ 2364546814 GeneratorGoverningBias 1;
BA_ "SPN" SG_ 2364546814 GeneratorGoverningBias 3938;
BA_ "SPN" SG_ 2565865214 ManufacturerSpecificInformation 2550;
BA_ "SigType" SG_ 2566767614 ExhGasRestrictionVlvCtrl 1;
BA_ "SPN" SG_ 2566767614 ExhGasRestrictionVlvCtrl 8150;
BA_ "SigType" SG_ 2566767614 AccelPedal2Channel3 1;
BA_ "SPN" SG_ 2566767614 AccelPedal2Channel3 2626;
BA_ "SigType" SG_ 2566767614 AccelPedal2Channel2 1;
BA_ "SPN" SG_ 2566767614 AccelPedal2Channel2 2625;
BA_ "SigType" SG_ 2566767614 AccelPedal1Channel3 1;
BA_ "SPN" SG_ 2566767614 AccelPedal1Channel3 2624;
BA_ "SigType" SG_ 2566767614 AccelPedal1Channel2 1;
BA_ "SPN" SG_ 2566767614 AccelPedal1Channel2 2623;
BA_ "GenSigStartValue" SG_ 2231031806 CRC8 255;
BA_ "SigType" SG_ 2559049470 ProtectionDerateOvrdCmd 5;
BA_ "SPN" SG_ 2559049470 ProtectionDerateOvrdCmd 9173;
BA_ "SPN" SG_ 2559049470 FuelingNotDesReason 7855;
BA_ "SigType" SG_ 2559049470 ShutdownCmd 5;
BA_ "SPN" SG_ 2559049470 ShutdownCmd 8614;
BA_ "SigType" SG_ 2559049470 TransIdleGovFuelingInh 4;
BA_ "SPN" SG_ 2559049470 TransIdleGovFuelingInh 7829;
BA_ "SPN" SG_ 2559049470 FuelingDesReason 7789;
BA_ "SigType" SG_ 2559049470 DesiredEngFuelingState 5;
BA_ "SPN" SG_ 2559049470 DesiredEngFuelingState 5793;
BA_ "SPN" SG_ 2559049470 RequestedFuelType 6317;
BA_ "SigType" SG_ 2559049470 EngGasFuelSupplyDesiredPress 1;
BA_ "SPN" SG_ 2559049470 EngGasFuelSupplyDesiredPress 6715;
BA_ "SigType" SG_ 2559049470 EngGasFuelUsageInhibited 4;
BA_ "SPN" SG_ 2559049470 EngGasFuelUsageInhibited 6833;
BA_ "SigType" SG_ 2349596414 AEBS2MessageChecksum 12;
BA_ "SPN" SG_ 2349596414 AEBS2MessageChecksum 5683;
BA_ "SigType" SG_ 2349596414 AEBS2MessageCounter 11;
BA_ "SPN" SG_ 2349596414 AEBS2MessageCounter 5682;
BA_ "SigType" SG_ 2349596414 DrvrActvtnDmndFrAdvncdEmrgncyBrk 5;
BA_ "SPN" SG_ 2349596414 DrvrActvtnDmndFrAdvncdEmrgncyBrk 5681;
BA_ "SPN" SG_ 2563571454 DataDictionaryRow 2427;
BA_ "SPN" SG_ 2563571454 DataDictionaryColumn 2428;
BA_ "SPN" SG_ 2563571454 ImplementType 2425;
BA_ "SPN" SG_ 2563571454 ImplementPos 2426;
BA_ "SigType" SG_ 2563571454 DataFormat_ErrorCondition 4;
BA_ "SPN" SG_ 2563571454 DataFormat_ErrorCondition 2419;
BA_ "SigType" SG_ 2563571454 ProcessDataType 4;
BA_ "SPN" SG_ 2563571454 ProcessDataType 2420;
BA_ "SPN" SG_ 2563571454 ProcessDataModifier 2421;
BA_ "SPN" SG_ 2563571454 RepetitionRateParameter 2418;
BA_ "SPN" SG_ 2563505918 ProcessVariableValue 2429;
BA_ "SPN" SG_ 2563505918 DataDictionaryRow 2427;
BA_ "SPN" SG_ 2563505918 DataDictionaryColumn 2428;
BA_ "SPN" SG_ 2563505918 ImplementType 2425;
BA_ "SPN" SG_ 2563505918 ImplementPos 2426;
BA_ "SPN" SG_ 2563505918 CountNumber 2422;
BA_ "SigType" SG_ 2563505918 DataFormat_ErrorCondition 4;
BA_ "SPN" SG_ 2563505918 DataFormat_ErrorCondition 2419;
BA_ "SigType" SG_ 2563505918 ProcessDataType 4;
BA_ "SPN" SG_ 2563505918 ProcessDataType 2420;
BA_ "SPN" SG_ 2563505918 ProcessDataModifier 2421;
BA_ "SigType" SG_ 2563178238 ValveFailSafeMode 4;
BA_ "SPN" SG_ 2563178238 ValveFailSafeMode 2934;
BA_ "SPN" SG_ 2563178238 ValveState 2932;
BA_ "SPN" SG_ 2563178238 RetractPortEstFlow 2940;
BA_ "SPN" SG_ 2563178238 ExtendPortEstFlow 2939;
BA_ "SPN" SG_ 2563112702 ReturnPortPress 2943;
BA_ "SPN" SG_ 2563112702 RetractPortPress 2942;
BA_ "SPN" SG_ 2563112702 ExtendPortPress 2941;
BA_ "SPN" SG_ 2563112702 RetractPortMeasuredFlow 2938;
BA_ "SPN" SG_ 2563112702 ExtendPortMeasuredFlow 2937;
BA_ "SPN" SG_ 2563047166 PortFlowCmd 2944;
BA_ "SPN" SG_ 2559835902 ErrorCode 5657;
BA_ "SPN" SG_ 2559835902 CommandedAAC 5674;
BA_ "SPN" SG_ 2559835902 CommandedIndustryGroup 5673;
BA_ "SPN" SG_ 2559835902 CommandedVehicleSystemInstance 5672;
BA_ "SPN" SG_ 2559835902 CommandedVehicleSystem 5671;
BA_ "SPN" SG_ 2559835902 CommandedFunction 5670;
BA_ "SPN" SG_ 2559835902 CommandedFunctionInstance 5669;
BA_ "SPN" SG_ 2559835902 CommandedECUInstance 5668;
BA_ "SPN" SG_ 2559835902 CommandedManufacturerCode 5667;
BA_ "SPN" SG_ 2559835902 NMControlModeIndicator 5666;
BA_ "SPN" SG_ 2559835902 AACQualifierFlag 5665;
BA_ "SPN" SG_ 2559835902 IndustryGroupQualifierFlag 5664;
BA_ "SPN" SG_ 2559835902 VehicleSystemInstanceQualifFlag 5663;
BA_ "SPN" SG_ 2559835902 VehicleSystemQualifierFlag 5662;
BA_ "SPN" SG_ 2559835902 FunctionQualifierFlag 5661;
BA_ "SPN" SG_ 2559835902 FunctionInstanceQualifierFlag 5660;
BA_ "SPN" SG_ 2559835902 ECUInstanceQualifierFlag 5659;
BA_ "SPN" SG_ 2559835902 ManufacturerCodeQualifierFlag 5658;
BA_ "SigType" SG_ 2558983934 SwitchedPowerOutput18Cmd 5;
BA_ "SPN" SG_ 2558983934 SwitchedPowerOutput18Cmd 6002;
BA_ "SigType" SG_ 2558983934 SwitchedPowerOutput19Cmd 5;
BA_ "SPN" SG_ 2558983934 SwitchedPowerOutput19Cmd 6001;
BA_ "SigType" SG_ 2558983934 SwitchedPowerOutput20Cmd 5;
BA_ "SPN" SG_ 2558983934 SwitchedPowerOutput20Cmd 6000;
BA_ "SigType" SG_ 2558983934 SwitchedPowerOutput13Cmd 5;
BA_ "SPN" SG_ 2558983934 SwitchedPowerOutput13Cmd 5999;
BA_ "SigType" SG_ 2558983934 SwitchedPowerOutput14Cmd 5;
BA_ "SPN" SG_ 2558983934 SwitchedPowerOutput14Cmd 5998;
BA_ "SigType" SG_ 2558983934 SwitchedPowerOutput15Cmd 5;
BA_ "SPN" SG_ 2558983934 SwitchedPowerOutput15Cmd 5997;
BA_ "SigType" SG_ 2558983934 SwitchedPowerOutput16Cmd 5;
BA_ "SPN" SG_ 2558983934 SwitchedPowerOutput16Cmd 5996;
BA_ "SigType" SG_ 2558983934 SwitchedPowerOutput9Cmd 5;
BA_ "SPN" SG_ 2558983934 SwitchedPowerOutput9Cmd 5995;
BA_ "SigType" SG_ 2558983934 SwitchedPowerOutput10Cmd 5;
BA_ "SPN" SG_ 2558983934 SwitchedPowerOutput10Cmd 5994;
BA_ "SigType" SG_ 2558983934 SwitchedPowerOutput29Cmd 5;
BA_ "SPN" SG_ 2558983934 SwitchedPowerOutput29Cmd 6015;
BA_ "SigType" SG_ 2558983934 SwitchedPowerOutput30Cmd 5;
BA_ "SPN" SG_ 2558983934 SwitchedPowerOutput30Cmd 6014;
BA_ "SigType" SG_ 2558983934 SwitchedPowerOutput31Cmd 5;
BA_ "SPN" SG_ 2558983934 SwitchedPowerOutput31Cmd 6013;
BA_ "SigType" SG_ 2558983934 SwitchedPowerOutput32Cmd 5;
BA_ "SPN" SG_ 2558983934 SwitchedPowerOutput32Cmd 6012;
BA_ "SigType" SG_ 2558983934 SwitchedPowerOutput25Cmd 5;
BA_ "SPN" SG_ 2558983934 SwitchedPowerOutput25Cmd 6011;
BA_ "SigType" SG_ 2558983934 SwitchedPowerOutput26Cmd 5;
BA_ "SPN" SG_ 2558983934 SwitchedPowerOutput26Cmd 6010;
BA_ "SigType" SG_ 2558983934 SwitchedPowerOutput27Cmd 5;
BA_ "SPN" SG_ 2558983934 SwitchedPowerOutput27Cmd 6009;
BA_ "SigType" SG_ 2558983934 SwitchedPowerOutput28Cmd 5;
BA_ "SPN" SG_ 2558983934 SwitchedPowerOutput28Cmd 6008;
BA_ "SigType" SG_ 2558983934 SwitchedPowerOutput21Cmd 5;
BA_ "SPN" SG_ 2558983934 SwitchedPowerOutput21Cmd 6007;
BA_ "SigType" SG_ 2558983934 SwitchedPowerOutput22Cmd 5;
BA_ "SPN" SG_ 2558983934 SwitchedPowerOutput22Cmd 6006;
BA_ "SigType" SG_ 2558983934 SwitchedPowerOutput23Cmd 5;
BA_ "SPN" SG_ 2558983934 SwitchedPowerOutput23Cmd 6005;
BA_ "SigType" SG_ 2558983934 SwitchedPowerOutput24Cmd 5;
BA_ "SPN" SG_ 2558983934 SwitchedPowerOutput24Cmd 6004;
BA_ "SigType" SG_ 2558983934 SwitchedPowerOutput17Cmd 5;
BA_ "SPN" SG_ 2558983934 SwitchedPowerOutput17Cmd 6003;
BA_ "SigType" SG_ 2558983934 SwitchedPowerOutput11Cmd 5;
BA_ "SPN" SG_ 2558983934 SwitchedPowerOutput11Cmd 5993;
BA_ "SigType" SG_ 2558983934 SwitchedPowerOutput12Cmd 5;
BA_ "SPN" SG_ 2558983934 SwitchedPowerOutput12Cmd 5992;
BA_ "SigType" SG_ 2558983934 SwitchedPowerOutput5Cmd 5;
BA_ "SPN" SG_ 2558983934 SwitchedPowerOutput5Cmd 5991;
BA_ "SigType" SG_ 2558983934 SwitchedPowerOutput6Cmd 5;
BA_ "SPN" SG_ 2558983934 SwitchedPowerOutput6Cmd 5990;
BA_ "SigType" SG_ 2558983934 SwitchedPowerOutput7Cmd 5;
BA_ "SPN" SG_ 2558983934 SwitchedPowerOutput7Cmd 5989;
BA_ "SigType" SG_ 2558983934 SwitchedPowerOutput8Cmd 5;
BA_ "SPN" SG_ 2558983934 SwitchedPowerOutput8Cmd 5988;
BA_ "SigType" SG_ 2558983934 SwitchedPowerOutput1Cmd 5;
BA_ "SPN" SG_ 2558983934 SwitchedPowerOutput1Cmd 5987;
BA_ "SigType" SG_ 2558983934 SwitchedPowerOutput2Cmd 5;
BA_ "SPN" SG_ 2558983934 SwitchedPowerOutput2Cmd 5986;
BA_ "SigType" SG_ 2558983934 SwitchedPowerOutput3Cmd 5;
BA_ "SPN" SG_ 2558983934 SwitchedPowerOutput3Cmd 5985;
BA_ "SigType" SG_ 2558983934 SwitchedPowerOutput4Cmd 5;
BA_ "SPN" SG_ 2558983934 SwitchedPowerOutput4Cmd 5984;
BA_ "SigType" SG_ 2349727486 CoastModeDisReq 5;
BA_ "SPN" SG_ 2349727486 CoastModeDisReq 22217;
BA_ "SigType" SG_ 2349727486 DisengageDiffLockReqRearAxle3 5;
BA_ "SPN" SG_ 2349727486 DisengageDiffLockReqRearAxle3 13072;
BA_ "SigType" SG_ 2349727486 Mode20 5;
BA_ "SPN" SG_ 2349727486 Mode20 12958;
BA_ "SigType" SG_ 2349727486 Mode19 5;
BA_ "SPN" SG_ 2349727486 Mode19 12957;
BA_ "SigType" SG_ 2349727486 Mode18 5;
BA_ "SPN" SG_ 2349727486 Mode18 12956;
BA_ "SigType" SG_ 2349727486 Mode17 5;
BA_ "SPN" SG_ 2349727486 Mode17 12955;
BA_ "SigType" SG_ 2349727486 Mode16 5;
BA_ "SPN" SG_ 2349727486 Mode16 12954;
BA_ "SigType" SG_ 2349727486 Mode15 5;
BA_ "SPN" SG_ 2349727486 Mode15 12953;
BA_ "SigType" SG_ 2349727486 Mode14 5;
BA_ "SPN" SG_ 2349727486 Mode14 12952;
BA_ "SigType" SG_ 2349727486 Mode13 5;
BA_ "SPN" SG_ 2349727486 Mode13 12951;
BA_ "SigType" SG_ 2349727486 Mode12 5;
BA_ "SPN" SG_ 2349727486 Mode12 12950;
BA_ "SigType" SG_ 2349727486 Mode11 5;
BA_ "SPN" SG_ 2349727486 Mode11 12949;
BA_ "SigType" SG_ 2349727486 SelectedMaxGearLmtActReq 5;
BA_ "SPN" SG_ 2349727486 SelectedMaxGearLmtActReq 11754;
BA_ "SPN" SG_ 2349727486 ReqReverseLaunchGear 11753;
BA_ "SigType" SG_ 2349727486 OutShaftBrkReq 5;
BA_ "SPN" SG_ 2349727486 OutShaftBrkReq 11752;
BA_ "SigType" SG_ 2349727486 PreDefinedMaxGearActReq 5;
BA_ "SPN" SG_ 2349727486 PreDefinedMaxGearActReq 11751;
BA_ "SigType" SG_ 2349727486 TransMode10 5;
BA_ "SPN" SG_ 2349727486 TransMode10 6570;
BA_ "SigType" SG_ 2349727486 TransMode9 5;
BA_ "SPN" SG_ 2349727486 TransMode9 6569;
BA_ "SigType" SG_ 2550988542 ClutchEngageReqStatus 4;
BA_ "SPN" SG_ 2550988542 ClutchEngageReqStatus 7844;
BA_ "SigType" SG_ 2550988542 ReadyForClutchEngagementStatus 5;
BA_ "SPN" SG_ 2550988542 ReadyForClutchEngagementStatus 7847;
BA_ "SigType" SG_ 2550988542 AccelPedalPos3 1;
BA_ "SPN" SG_ 2550988542 AccelPedalPos3 28;
BA_ "SigType" SG_ 2566767358 EngFuelIsolationCtrl 5;
BA_ "SPN" SG_ 2566767358 EngFuelIsolationCtrl 7394;
BA_ "SPN" SG_ 2566767358 FuelType 5837;
BA_ "SigType" SG_ 2566767358 EngFuelMassFlowRate 1;
BA_ "SPN" SG_ 2566767358 EngFuelMassFlowRate 5833;
BA_ "SigType" SG_ 2566767358 EngExhstGsRcrcltn1Valve2PosError 1;
BA_ "SPN" SG_ 2566767358 EngExhstGsRcrcltn1Valve2PosError 5830;
BA_ "SigType" SG_ 2566767358 EngExhstGsRcrcltn1Valve1PosError 1;
BA_ "SPN" SG_ 2566767358 EngExhstGsRcrcltn1Valve1PosError 5829;
BA_ "SigType" SG_ 2566706686 FilterLifeRem 1;
BA_ "SPN" SG_ 2566706686 FilterLifeRem 21145;
BA_ "SigType" SG_ 2566706686 DEFXferPumpPurgeRelay 4;
BA_ "SPN" SG_ 2566706686 DEFXferPumpPurgeRelay 13361;
BA_ "SigType" SG_ 2566706686 PwrSupply 5;
BA_ "SPN" SG_ 2566706686 PwrSupply 8474;
BA_ "SigType" SG_ 2566706686 DosingUnit1HtrRelay 5;
BA_ "SPN" SG_ 2566706686 DosingUnit1HtrRelay 5746;
BA_ "SigType" SG_ 2566706686 TwoMotorSpd 1;
BA_ "SPN" SG_ 2566706686 TwoMotorSpd 7461;
BA_ "SigType" SG_ 2566706686 Htr 1;
BA_ "SPN" SG_ 2566706686 Htr 5706;
BA_ "SigType" SG_ 2566705406 A1ParticulateSnsrCur 1;
BA_ "SPN" SG_ 2566705406 A1ParticulateSnsrCur 7393;
BA_ "SigType" SG_ 2566705406 A2ParticulateSnsr 1;
BA_ "SPN" SG_ 2566705406 A2ParticulateSnsr 5836;
BA_ "SigType" SG_ 2566705406 A1ParticulateSnsr 1;
BA_ "SPN" SG_ 2566705406 A1ParticulateSnsr 5835;
BA_ "SPN" SG_ 2566705150 AFT2InNOxSnsrSelfDiagTrigger 5712;
BA_ "SPN" SG_ 2566705150 A2OutNOxSnsrSelfDiagTrigger 5711;
BA_ "SPN" SG_ 2566705150 AFT1InNOxSnsrSelfDiagTrigger 5710;
BA_ "SPN" SG_ 2566705150 A1OutNOxSnsrSelfDiagTrigger 5709;
BA_ "SigType" SG_ 2566704382 A1Out2GasSnsrPwrSupply 5;
BA_ "SPN" SG_ 2566704382 A1Out2GasSnsrPwrSupply 8147;
BA_ "SigType" SG_ 2566704382 AFT1In2GasSnsrPwrSupply 5;
BA_ "SPN" SG_ 2566704382 AFT1In2GasSnsrPwrSupply 8146;
BA_ "SigType" SG_ 2566704382 A2Out1GasSnsrPwrSupply 5;
BA_ "SPN" SG_ 2566704382 A2Out1GasSnsrPwrSupply 5761;
BA_ "SigType" SG_ 2566704382 AFT2In1GasSnsrPwrSupply 5;
BA_ "SPN" SG_ 2566704382 AFT2In1GasSnsrPwrSupply 5760;
BA_ "SigType" SG_ 2566704382 A1Out1GasSnsrPwrSupply 5;
BA_ "SPN" SG_ 2566704382 A1Out1GasSnsrPwrSupply 5759;
BA_ "SigType" SG_ 2566704382 AFT1In1GasSnsrPwrSupply 5;
BA_ "SPN" SG_ 2566704382 AFT1In1GasSnsrPwrSupply 5758;
VAL_ 2364553470 EngDualFuelModeCmd 3 "Not available" 2 "Reserved" 1 "Activate dual fuel mode" 0 "De-activate dual fuel mode" ;
VAL_ 2364553214 EngTrbCmprssrBlwffActtr1OprtnStt 15 "Not available" 14 "Error" 6 "Calibration in Progress" 5 "Uncontrolled Shutdown Active" 4 "Controlled Shutdown Active" 3 "Derate Active" 2 "Alarm High Severity" 1 "Alarm" 0 "Normal" ;
VAL_ 2364553214 EngTrbCmprssrBlwffActtr1TmpSttus 7 "Not available" 6 "Error" 5 "Not Defined" 4 "Low Most severe" 3 "Low Least severe" 2 "In Range" 1 "High Least severe" 0 "High Most severe" ;
VAL_ 2565874430 PersistentLimitStatus 7 "Not available" 6 "Non-recoverable fault" 3 "Limited low" 2 "Limited high" 1 "Operator limited/controlled" 0 "Not limited" ;
VAL_ 2565874430 MachineSelectedSpeedSource 7 "Not available" 4 "'Simulated' speed" 3 "'Blended' speed" 2 "Navigation-based speed" 1 "Ground-based speed" 0 "Wheel-based speed" ;
VAL_ 2565874430 MachineSelectedDirection 2 "Error indication" 1 "Forward" 0 "Reverse" 3 "Not available" ;
VAL_ 2565873918 YCSystemStatus 1 "YCSystemEnabled" 0 "YCSystemDisabled" ;
VAL_ 2565873918 ROPSystemStatus 1 "ROPSystemEnabled" 0 "ROPSystemDisabled" ;
VAL_ 2364546814 EngSelfInducedDerateInh 3 "Don't care / take no action" 2 "SAE Reserved" 1 "Engine is inhibited from imposing a self-induced derate" 0 "Engine is allowed to impose a self-induced derate" ;
VAL_ 2565872638 TrailerWorkLights 1 "LightsOn" 0 "LightsOff" ;
VAL_ 2565872638 TrailerInteriorLights 1 "LightsOn" 0 "LightsOff" ;
VAL_ 2565872638 TrailerRotatingIndentLights 1 "LightsOn" 0 "LightsOff" ;
VAL_ 2565872638 TrailerRearWarningLights 1 "LightsOn" 0 "LightsOff" ;
VAL_ 2565872638 TrailerRightRearRegPlateLights 1 "LightsOn" 0 "LightsOff" ;
VAL_ 2565872638 TrailerLeftRearRegPlateLights 1 "LightsOn" 0 "LightsOff" ;
VAL_ 2565872638 TrailerRightCornerMarkerLights 1 "LightsOn" 0 "LightsOff" ;
VAL_ 2565872638 TrailerLeftCornerMarkerLights 1 "LightsOn" 0 "LightsOff" ;
VAL_ 2565872638 TrailerRightRearWidthIndLights 1 "LightsOn" 0 "LightsOff" ;
VAL_ 2565872638 TrailerLeftRearWidthIndLights 1 "LightsOn" 0 "LightsOff" ;
VAL_ 2565872638 TrailerrightSideMarkerLights 1 "LightsOn" 0 "LightsOff" ;
VAL_ 2565872638 TrailerLeftSideMarkerLights 1 "LightsOn" 0 "LightsOff" ;
VAL_ 2565872638 TrailerRightReversingLights 1 "LightsOn" 0 "LightsOff" ;
VAL_ 2565872638 TrailerLeftReversingLights 1 "LightsOn" 0 "LightsOff" ;
VAL_ 2565872638 TrailerRightRearFogLights 1 "LightsOn" 0 "LightsOff" ;
VAL_ 2565872638 TrailerLeftRearFogLights 1 "LightsOn" 0 "LightsOff" ;
VAL_ 2565872638 TrailerRightRearLights 1 "LightsOn" 0 "LightsOff" ;
VAL_ 2565872638 TrailerLeftRearLights 1 "LightsOn" 0 "LightsOff" ;
VAL_ 2565872638 TrailerRightDirIndicatorLights 1 "LightsOn" 0 "LightsOff" ;
VAL_ 2565872638 TrailerLeftDirIndicatorLights 1 "LightsOn" 0 "LightsOff" ;
VAL_ 2565872638 TrailerRightStopLights 1 "LightsOn" 0 "LightsOff" ;
VAL_ 2565872638 TrailerLeftStopLights 1 "LightsOn" 0 "LightsOff" ;
VAL_ 2231031806 VelocityAndYawRateConfLevel 15 "SignalNotAvailable" 14 "Error" 7 "dv<0.05m/s dy<0.1°/s" 6 "dv<0.1m/s dy<0.25°/s" 5 "dv<0.25m/s dy<0.5°/s" 4 "dv<0.5m/s dy<1°/s" 3 "dv<1m/s dy<2°/s" 2 "dv<2m/s dy<4°/s" 1 "Inaccurate" 0 "Invalid" ;
VAL_ 2559049470 ProtectionDerateOvrdCmd 3 "Don't care/take no action" 2 "Reserved" 1 "Override active" 0 "Override disabled" ;
VAL_ 2559049470 FuelingNotDesReason 255 "Not supported" 250 "Fueling is not desired due to unspecified reason" 6 "Transmission Coast Mode" 5 "Alcohol Interlock Test has failed" 4 "Engine Stop-Start" 3 "Body builder" 2 "External power source has been connected" 1 "Idle Shutdown Timer has expired" 0 "Desired Engine Fueling State" ;
VAL_ 2559049470 ShutdownCmd 3 "Not Available" 2 "SAE Reserved" 1 "Shut down the engine" 0 "No command to shut down the engine" ;
VAL_ 2559049470 TransIdleGovFuelingInh 3 "Don't care/take no action." 2 "Reserved for future SAE use." 1 "Transmission is currently commanding the Engine to inhibit idle governor fueling." 0 "'Transmission Idle Governor Fueling Inhibit' is not currently desired." ;
VAL_ 2559049470 FuelingDesReason 255 "Not supported" 250 "Engine operation is needed to perform normal device functions not specifically listed" 16 "Engine is needed for the Diesel Particulate Filter diagnosis" 15 "Engine is needed for DEF dosing system diagnosis" 14 "Engine is needed for DEF dosing system component protection" 13 "Engine is needed for DEF dosing system operation" 12 "Engine is needed for PTO operation" 11 "Engine is needed for engine driven accessory operation" 10 "Device has detected one or more fault conditions" 9 "Service Override is active" 8 "Device preparation for engine shutdown is in progress" 7 "Device protection" 6 "Engine is needed for charging the hybrid stored energy source" 5 "Engine is needed for charging the SLI batteries" 4 "Engine is needed for cooling system operation" 3 "Engine coolant is needed as a heat source" 2 "Engine exhaust is needed as a heat source" 1 "Lubrication distribution in device is incomplete" 0 "Desired Engine Fueling State" ;
VAL_ 2559049470 DesiredEngFuelingState 3 "Don't care / Take no action" 2 "Parameter supported" 1 "Fueling desired" 0 "Fueling not desired" ;
VAL_ 2559049470 RequestedFuelType 255 "Not supported" 254 "Reserved for use in SPN 5837" 32 "Heavy Fuel Oil" 31 "Kerosene" 23 "Natural Gas" 7 "Propane" 6 "Compressed Natural Gas" 5 "Liquefied Petroleum Gas" 4 "Diesel" 3 "Ethanol" 2 "Methanol" 1 "Gasoline/petrol" 0 "Not available" ;
VAL_ 2559049470 EngGasFuelUsageInhibited 3 "Not available" 2 "Error" 1 "Gaseous Fuel Usage Inhibited" 0 "Gaseous Fuel Usage Not Inhibited" ;
VAL_ 2349596414 DrvrActvtnDmndFrAdvncdEmrgncyBrk 3 "don't' care / take no action" 2 "reserved" 1 "the driver wants the Advanced Emergency Braking System to warn or intervene if necessary" 0 "the driver does not want the Advanced Emergency Braking System to warn or intervene at any time" ;
VAL_ 2563571454 DataFormat_ErrorCondition 3 "Not Available or error" 2 "Data format is unsigned Long Integer" 1 "Data format is Floating" 0 "Data format is Long Integer" ;
VAL_ 2563571454 ProcessDataType 3 "Message is Actual value request" 2 "Message is Set Point request" 1 "Data is Actual values" 0 "Data is Set Point" ;
VAL_ 2563505918 DataFormat_ErrorCondition 3 "Not Available or error" 2 "Data format is unsigned Long Integer" 1 "Data format is Floating" 0 "Data format is Long Integer" ;
VAL_ 2563505918 ProcessDataType 3 "Message is Actual value request" 2 "Message is Set Point request" 1 "Data is Actual values" 0 "Data is Set Point" ;
VAL_ 2563178238 ValveFailSafeMode 3 "Don’t Care" 2 "Reserved" 1 "Float" 0 "Block" ;
VAL_ 2563178238 ValveState 15 "Don’t Care" 3 "Floating" 2 "Retract" 1 "Extend" 0 "Blocked" ;
VAL_ 2560294654 StatusEvaporator3 3 "Defrost" 2 "Heating" 1 "Cooling" 0 "Standby" ;
VAL_ 2560294654 StatusEvaporator2 3 "Defrost" 2 "Heating" 1 "Cooling" 0 "Standby" ;
VAL_ 2560294654 StatusEvaporator1 3 "Defrost" 2 "Heating" 1 "Cooling" 0 "Standby" ;
VAL_ 2560294654 ReeferUnitDefrostCycleOnOff 1 "DefrostOn" 0 "DefrostOff" ;
VAL_ 2560294654 ReeferUnitOnOff 1 "ReeferUnitOn" 0 "ReeferUnitOff" ;
VAL_ 2559835902 ErrorCode 255 "Not Available" 254 "Reserved" 6 "Reserved" 5 "Other" 4 "Pending NAME not set" 3 "Checksum does not match" 2 "Item conflict" 1 "Item(s) not allowed to change" 0 "Security not satisfied" ;
VAL_ 2559835902 CommandedIndustryGroup 6 "Reserved for SAE" 7 "Reserved for SAE" 5 "IndustrialProcessCtrlStationary" 4 "Marine" 3 "Construction" 2 "Agricultural and Forestry" 1 "On-Highway" 0 "Global" ;
VAL_ 2559835902 CommandedManufacturerCode 1346 "Einboeck GmbH" 1345 "PRIGNITZ Mikrosystemtechnik GmbH" 1344 "Haulotte Group" 1343 "Heavy Data GmbH" 1342 "DKE-Data GmbH & Co. KG" 1341 "Ag Express Electronics" 1340 "ORELTEK Elektronik ve Yazilim Teknolojileri" 1339 "Tillett and Hague Technology Limited" 1338 "Volta Trucks AB" 1337 "Barnacle Systems Inc." 1336 "Aegis Power Systems, Inc." 1335 "CPDEVICE" 1334 "Greer Company" 1333 "xFarm Technologies SA" 1332 "Fairbanks Scales, Inc." 1331 "Dolphin Charger" 1330 "Warwick Control Technologies" 1329 "IDM S.r.l." 1328 "PerPlant ApS" 1327 "Frans Vervaet B.V." 1326 "HBC-radiomatic GmbH" 1325 "BASE Engineering Inc." 1324 "Bourgault Industries" 1323 "Briter Products, Inc." 1322 "Movimatica" 1321 "PATLITE Corporation" 1320 "Triskel Marine Ltd" 1319 "I/O Controls Corporation" 1318 "Atlis Motor Vehicles" 1317 "GMM - Global Maritime Management GmbH" 1316 "Hinkley Yachts" 1315 "SMPC Technologies Ltd." 1314 "Newton Crouch Company, LLC" 1313 "United States Army - Ground Vehicle Systems Center" 1312 "Control Devices Pty Ltd" 1311 "Humphree AB" 1310 "LPL Systems (formerly Loughborough Projects Ltd)" 1309 "Shanghai Zhichuan Electronic Tech Co., Ltd." 1308 "Agtecnic" 1307 "Smart AG Systems" 1306 "Koden Electronics Co., Ltd." 1305 "dragonfly Energy" 1304 "Palfinger Europe GmbH" 1303 "Carbon Bee AgTech" 1302 "ProMariner" 1301 "Tecumseh do Brasil Ltda" 1300 "Watt Fuel Cell Corporation" 1299 "Energy Solutions" 1298 "SFOGGIA Agriculture Division S.r.l." 1863 "Thomas G. Faria Co." 1862 "Sanshin" 1861 "Vector North America (formerly Vector Cantech)" 1860 "MMP" 1859 "Kvasar AB" 1858 "Litton" 1857 "Simrad" 1856 "Trimble" 1855 "Furuno USA" 1854 "Northstar Technologies" 1853 "Japan Radio Co" 1852 "Navionics" 1851 "RayMarine" 1850 "Seastar Solutions (formerly Teleflex)" 1569 "621 Technologies Inc." 1376 "SUNS International, LLC" 1375 "ŠKODA TRANSPORTATION a.s." 1374 "CASAPPA S.p.A." 1373 "Centek Industries" 1372 "Elco Motor Yachts" 1371 "First Mode" 1370 "Emtech S.A." 1369 "Electric Yacht" 1368 "RAD Propulsion Ltd" 1367 "Dewulf NV" 1366 "Telemecanique Sensors & Switches" 1365 "JVCKENWOOD Corporation" 1364 "Yashu Systems" 1363 "Calix AB" 1362 "Zparq AB" 1361 "Nantong Saiyang Electronics Co., Ltd." 1360 "Lemca Vision" 1359 "BlueNav" 1358 "Fontaine Fifth Wheel" 1357 "TireCheck" 1356 "Nordic Lights Ltd" 1355 "DROP Agricultura Ltda" 1354 "Técnicas de Electrónica y Automatismos, S.A." 1353 "Ocean LED Marine Ltd" 1352 "NISHIYAMA Corporation" 1351 "Motorenfabrik Hatz GmbH & Co. KG" 1350 "AGRONETIC" 1349 "ANNABURGER Nutzfahrzeug GmbH" 1348 "Radian IoT, Inc." 1347 "Munckhof Fruit Tech Innovators" 1297 "Micro-Epsilon Messtechnik GmbH & Co. KG" 1296 "Hexagon" 1295 "SIP d.d." 1294 "TR-Electronic GmbH" 1293 "POSITAL" 1292 "SUMITOMO CONSTRUCTION MACHINERY CO., LTD." 1291 "Forward Thinking Systems LLC" 1290 "WaveTamer Partners LLC" 1289 "Loadrite (Auckland) Ltd." 1288 "ANELLO Photonics" 1287 "Spartan Radar" 1286 "NEXAT GmbH" 1285 "Graco Inc." 1284 "Robot Makers GmbH" 1283 "LTG Tech" 1282 "COTEK ELECTRONIC IND. CO., LTD" 1281 "iQuus" 1280 "SANTEST CO., LTD." 1279 "Ognibene Power S.p.A." 1278 "Comrod Communication Group" 1277 "BMZ Germany GmbH" 1276 "Aspin Kemp & Associates" 1275 "O.M.P. Officine Mazzocco Pagnoni S.r.l." 1274 "LDL Technology" 1273 "Clearflame Engines Inc" 1272 "Samsara Inc." 1271 "Raven Connected" 1270 "Versalift Denmark A/S" 1269 "VIS Hydraulics s.r.l." 1268 "Back 40 Precision Inc." 1267 "Wacker Neuson SE" 1266 "Hyundai Doosan Infracore" 1265 "IPETRONIK GmbH & Co KG" 1264 "Microelect" 1263 "BOS Balance of Storage Systems AG" 1262 "Fort Robotics" 1261 "AgXeed" 1260 "Interactive Technologies, Inc." 1259 "Grayson Automotive Services Limited" 1258 "AGC Technologies" 1257 "KOSTAL" 1256 "Dimensions Agri Technologies AS" 1255 "Altec Industries, Inc." 1254 "ARADEX AG" 1253 "Trafag AG" 1252 "APV - Technische Produkte GmbH" 1251 "Valmet Automotive EV Power Ltd" 1250 "ELHO" 1249 "Integrated Power Solutions AG" 1248 "O.M.F.B. S.p.A. Hydraulic Components" 1247 "GRIFA" 1246 "Rother Industries & Technology" 1245 "Raritan Engineering Company, Inc" 1244 "Planti Center" 1243 "AvMap S.r.l." 1242 "Super Start Batteries" 1241 "Ineo Systrans" 1240 "TiMOTION" 1239 "SuperTrack Aps" 1238 "Honda Electronics Co., Ltd" 1237 "Changzhou Lambda Electronic Co., Ltd" 1236 "Agrosystem" 1235 "NESAN Automotive Inc." 1234 "American Battery Solutions" 1233 "nke Marine Electronics" 1232 "Treffler Maschinenbau GmbH & Co. KG" 1231 "Excidor AB" 1230 "Nick Abbey Digital Agriculture Ltd" 1229 "Arcon Designs, LLC" 1228 "INTILION GmbH" 1227 "YAHATA Co., Ltd." 1226 "Piippo Hydraulic" 1225 "SeedMaster Manufacturing Ltd" 1224 "Neuser Elektrotechnik GmbH" 1223 "Toyo Agricultural Machinery Manufacturing Co., Ltd" 1222 "Tough Tech Ltd." 1221 "Norcold Inc." 1220 "Catamaran Electronics LLC" 1219 "Weidmueller Interface GmbH & Co. KG" 1218 "Septentrio" 1217 "FSG Fernsteuergeräte Kurt Oelsch GmbH" 1216 "SMP Poland sp. z o.o." 1215 "Power Control Systems" 1214 "Element 1" 1213 "Apollo Tyres Ltd" 1212 "TAO Performance Limited" 1211 "Kiwon Electronics Co., Ltd." 1210 "Ambra Solutions" 1209 "Bauser GmbH & Co. KG" 1208 "Afflield Kft. (MachineryGuide)" 1207 "UEC Electronics" 1206 "STE Solutions B.V." 1205 "Carbon Autonomous Robotic Systems" 1204 "Miller Technology Incorporated" 1203 "Equipment Technologies, Inc." 1202 "OSCAR Elettronica" 1201 "Emisense Technologies, LLC" 1200 "Xinuo Information Technology (Xiamen) Corporation Limited" 1199 "ELEO Technologies B.V." 1198 "ComLink Equipamentos Eletrônicos Ltda" 1197 "SOLGE Corporation" 1196 "Terra Care GmbH" 1195 "düvelsdorf" 1194 "Sierra Marine" 1193 "emotas embedded communication GmbH" 1192 "Airmoniq Pro Kft." 1191 "Pacoma USA, Inc." 1190 "Sirros IoT" 1189 "Autotrasporti Cavallo G&V" 1188 "G-SNS" 1187 "TiTAN-Project LLC" 1186 "Sailmon BV" 1185 "WFCO Electronics" 1184 "AMA S.p.A." 1183 "Zipwake AB" 1182 "Rottmann Automation" 1181 "Banjo Corporation" 1180 "Murata Power Solutions Inc." 1179 "QS Control srl" 1178 "ERO GmbH" 1177 "RNG International Inc." 1176 "Asuns Corp." 1175 "MAGTEC Products, Inc." 1174 "Agricon GmbH" 1173 "philippi elektrische systeme gmbh" 1172 "Hyzon Motors" 1171 "Vista Manufacturing" 1170 "Poseidon Ocean Systems Ltd." 1169 "Sea Machine Robotics Inc." 1168 "Masats S.A." 1167 "Tevva Motors" 1166 "Wachendorff Automation GmbH & Co. KG" 1165 "InnoTotal AB" 1164 "SEG Automotive" 1163 "DFX Technologies LLC" 1162 "PEL-tuote Oy" 1161 "Griessbach GmbH" 1160 "MG Energy Systems B.V." 1159 "Bel Power Solutions" 1158 "Technoton Electronics" 1157 "Carriergistics" 1156 "Nokian Tyres" 1155 "LACOS Computerservice GmbH" 1154 "TBS Electronics BV" 1153 "Kawasaki Heavy Industries, Ltd." 1152 "Vredo Dodewaard B.V." 1151 "Orca Technologies AS" 1150 "BSB Artificial Intelligence GmbH" 1149 "Wuxi Shengbang Electronics Co., Ltd" 1148 "Stercom Power Solutions GmbH" 1147 "Dana Inc." 1146 "Rometron" 1145 "Kiwi Yachting" 1144 "Troo Corporation" 1143 "Elektro-Szoft 2000" 1142 "Truma" 1141 "MRS Electronic GmbH & Co. KG" 1140 "Across Oceans Systems Ltd." 1139 "ASP Technology" 1138 "Micro-Sensor GmbH" 1137 "SIKO GmbH" 1136 "Primosensor GmbH" 1135 "Japan Aviation Electronics Industry, Limited" 1134 "Master Schools at Ostbahnhof" 1133 "MEGATRON Elektronik GmbH & Co. KG" 1132 "Tokachi Zaidan" 1131 "Guliwer electronics s.r.o." 1130 "Vitesco Technologies" 1129 "Spectrolytic GmbH" 1128 "Citoon Electronic Technology (Tianjin) Co., Ltd." 1127 "ElectroMaax" 1126 "Auralix" 1125 "Griffith-Elder & Co. Ltd." 1124 "Fortron Agriculture" 1123 "QP Hydraulics" 1122 "GT Inc." 1121 "Platform Science" 1120 "Elettromedia s.r.l." 1119 "Balmar LLC" 1118 "L3Harris ASV" 1117 "LG Chem, Ltd" 1116 "HR Agrartechnik GmbH" 1115 "Gems Sensors & Controls" 1114 "Bob's Machine" 1113 "iVolve Pty Ltd" 1112 "Bollinger Motors" 1111 "SEPPI M." 1110 "Analytic Systems Ware (1993) Ltd." 1109 "Dockmate" 1108 "ORBCOMM" 1107 "Dräger Safety" 1106 "Great Dane LLC" 1105 "Redekop Manufacturing" 1104 "The Toro Company" 1103 "Diesel Laptops" 1102 "Carl Geringhoff GmbH & Co. KG" 1101 "DIS Sensors B.V." 1100 "Smart Yachts International Limited" 1099 "MadgeTech, Inc" 1098 "Preh GmbH" 1097 "M2M Craft Co., Ltd" 1096 "Texense Sensors" 1095 "WEG Drives and Controls - Automação Ltda" 1094 "Tokushu Denki" 1093 "innolectric" 1092 "Scheiber" 1091 "Wheel Monitor Inc." 1090 "E-T-A Circuit Breakers Ltd" 1089 "Carrosserie HESS AG" 1032 "SIMOL S.p.A." 1031 "Flintec UK Ltd." 1030 "Tume-Agri Oy" 1029 "The Marine Guardian LLC" 1028 "Autel Intelligent Technology Corp., Ltd" 1027 "Goldacres PTY LTD" 1026 "ZTR Control Systems, LLC" 1025 "eze System, Inc." 1024 "Inventus Power" 1023 "PEAK-System Technik GmbH" 1022 "ITC Inc" 1021 "Entratech Systems LLC" 1020 "Onyx Marine Automation s.r.l." 1019 "Codek Foundries" 1018 "Flex TTS" 1017 "Caldaro AB" 1016 "Röhren- und Pumpenwerk BAUER GmbH" 1015 "SECURITAG SAS" 1014 "Briri Maschinenbau GmbH" 1013 "Allochis E-Tec" 1012 "Rhodan Marine Systems of Florida LLC" 1011 "Soundmax Electronics Ltd" 1010 "Agricultural Industry Electronics Foundation e.V." 1009 "TouchTronics, Inc." 1008 "Lintest Systems LLC" 1007 "Maschinenfabrik Meyer-Lohne GmbH" 1006 "Proterra" 1005 "TSE Brakes, Inc." 1004 "Ultraflex SpA" 1003 "technotrans SE" 1002 "Kussmaul Electronics Co." 1001 "Cleral Inc." 1000 "Landmaschinen Wienhoff GmbH" 999 "TerraTroniq B.V." 998 "Transcell Technology Inc" 997 "Xenta Systems Srl" 996 "Eniquest Pty Ltd" 995 "Circuitlink Pty Ltd." 994 "Morris Industries Ltd." 993 "Alelion Energy Systems AB" 992 "MarineIOT LLC" 991 "Deutronic Elektronik GmbH" 990 "SAMSUNG SDI Co., Ltd." 989 "Flux-Geräte GmbH" 988 "Voith Turbo" 987 "Baltic Car Equipment" 986 "AAMP Global" 985 "NLR, LLC" 984 "E-T-A Elektrotechnische Apparate GmbH" 983 "Dezwaef NV" 982 "Briggs & Stratton Corporation" 981 "Kobelt Manufacturing Co. Ltd" 777 "Ocean Signal Ltd" 776 "HMI Systems LLC" 775 "ZIEHL-ABEGG Automotive GmbH" 774 "Taisho Corporation" 773 "Clarion Corporation of America" 772 "Blink Marine" 771 "Shaw Development, LLC" 770 "MONOSEM" 769 "Trombetta" 768 "Flores Automation, LLC" 767 "Alliance Wireless Technologies Inc." 766 "Epec Oy" 765 "GIGAVAC" 764 "Bednar FMT s.r.o." 763 "AT-Systems BVBA" 762 "ROJ s.r.l." 761 "MITA OLEODINAMICA S.p.A." 760 "Bernecker + Rainer Industrie Elektronik GmbH" 759 "Hydro-Gear" 758 "Banner Engineering Corp." 757 "IMPCO Technologies" 756 "Maschio Gaspardo S.P.A." 755 "Firefly Integrations" 754 "Parker Hannifin Corp., Automation Group" 753 "AIROD Technologies" 752 "Deep Sea Electronics Plc" 751 "Pacific Track" 750 "Joskin SA" 749 "Chart Inc." 748 "IFRA SRL - ISOTTA" 747 "Agratronix" 746 "SureFire Ag Systems, Inc." 745 "Cidra Corporate Services Inc." 744 "Woosung Engineering Co., Ltd." 743 "Daemyung Elevator Co., Ltd." 742 "EROAD" 741 "Littelfuse, Inc (formerly Carling Technologies)" 740 "e-Traction" 739 "LXNAV d.o.o." 738 "Blue Ink Technologies" 737 "Balluff GmbH" 736 "Terex Aerial Work Platforms - Genie" 735 "AEM Performance Electronics" 734 "REAPsystems" 733 "Geotab Inc. (formerly Intendia S.L.)" 732 "Gefran S.p.A." 731 "Modine Manufacturing Company" 730 "BERTHOUD AGRICOLE" 729 "Liebherr" 728 "Streumaster (formerly Streumaster / Panien)" 727 "Dhoot Transmission Pvt Ltd." 726 "MIDORI PRECISIONS" 1088 "E-T-A Circuit Breakers" 1087 "ITPhotonics S.r.l." 1086 "Life Racing Ltd" 1085 "Wet Sounds, LLC" 1084 "Shadow-Caster LED lighting LLC" 1083 "Nauticoncept" 1082 "TÜMOSAN Engine and Tractor Co." 1081 "Imcon Electronics, s.r.o." 1080 "Epsilor-Electric Fuel Ltd." 1079 "Carl Zeiss Spectroscopy GmbH" 1078 "GE Appliances" 1077 "Ymer Technology" 1076 "DOGA S.A." 1075 "Uniden America Corporation" 1074 "Kindhelm / Navigs Oy" 1073 "Manitou Equipment America LLC" 1072 "La Marche Manufacturing Company" 1071 "MACH SYSTEMS s.r.o." 1070 "Quick-teck Electronics Ltd" 1069 "Lithionics Battery LLC" 1068 "Zapi S.p.A." 1067 "Tecomec S.r.l." 1066 "Spot Zero Water" 1065 "CALYPSO Instruments" 1064 "Omnitech Robotics Inc." 1063 "SolSteer" 1062 "Marol Co Ltd" 1061 "Volvo Construction Equipment" 1060 "Scale-Tec" 1059 "Boatrax" 1058 "Bondioli & Pavesi SpA" 1057 "EquipmentShare" 1056 "Lithium Pros" 1055 "EXA Computing GmbH" 1054 "Schmotzer Hacktechnik GmbH & Co. KG" 1053 "Vetus Maxwell, Inc." 1052 "Pfreundt" 1051 "ProNav AS" 1050 "Spacenus GmbH" 1049 "S&S Cycle" 1048 "Agrivation UG" 1047 "Sonic Corporation" 1046 "Praxidyn" 1045 "CMR Group" 1044 "Xee" 1043 "Hyva" 1042 "engcon group" 1041 "EZ Lynk" 1040 "BPE Electronics Srl" 1039 "Liugong Dressta Machinery" 1038 "EMIT Technologies, Inc." 1037 "Dragonfly Energy Corp." 1036 "Bender GmbH & Co. KG" 1035 "Agres" 1034 "Siren Marine" 1033 "ECCO Safety Group" 980 "Gussi Italia S.R.L." 979 "McHale" 978 "Canfield Connector" 977 "Copeland LP (formerly Emerson Electric Co.)" 976 "Derive Systems, Inc." 975 "Siemens AG" 974 "Pico Technology Limited" 973 "Zasso GmbH" 972 "Axion AG" 971 "B+B Smartworx" 970 "Jaboni Power Products, LLC" 969 "Blue Sea Systems" 968 "Cox Powertrain Limited" 967 "Moteck Electric Corp." 966 "VisibleFarm" 965 "Ro-Sys Software" 964 "AgroVIR Kft" 963 "Thomason Jones Company, LLC" 962 "Timbolier Industries, Inc." 961 "POK SAS" 960 "Vemcon GmbH" 959 "Cascade Corporation" 958 "NHK MEC Corporation" 957 "Sierra Wireless Inc" 956 "Piher Sensors & Controls S.A." 955 "Hottinger Baldwin (Suzhou) Electronic Measurement Technology Co., Ltd." 954 "Setec Pty Ltd" 953 "Curtiss-Wright" 952 "Tan Delta Systems Ltd" 951 "Exor International S.p.A." 950 "RE:Lab s.r.l." 949 "Škoda Electric a.s." 948 "Donix" 947 "Gerd Bär GmbH" 946 "Hydac Tecnologia Ltda" 945 "Equalizer AG" 944 "ZONTISA Marine SL" 943 "FISCHER AG Präzisionspindeln" 942 "Vogelsang GmbH & Co. KG" 941 "Navya" 940 "Dometal Oy" 939 "Warn Industries, Inc." 938 "LEVEL Systems" 937 "Precision Circuits Inc" 936 "Hi-tech Millennium" 935 "Meels GmbH & Co. KG" 934 "Farmobile, Inc." 933 "Delta Mobile Systems, Inc." 932 "Discover Battery" 931 "Enertec Marine Ltd" 930 "Ecotronix Corp." 929 "Jl Marine Systems, Inc." 928 "EAO Automotive GmbH & Co. KG" 927 "Saicon" 926 "Buhler Industries Inc." 925 "GW Lisk Company" 924 "PAS Peschak Autonome Systeme GmbH" 923 "ELTEK S.p.A." 922 "Terberg Benschop B.V." 921 "ROPA Fahrzeug- und Maschinenbau GmbH" 920 "MTD Consumer Group Inc." 919 "Furrion LLC" 918 "AMW Machine Control, Inc" 917 "Sentinel d.o.o." 916 "Hans Turck GmbH & Co. KG (formerly Turck Inc.)" 915 "Dosificacion y sistemas electronicos S.L. (DSE)" 914 "ZETOR TRACTORS a.s." 913 "Toyota Motor Corporation" 912 "Steyr Motors GmbH" 911 "Nautic-On" 910 "Hermann Paus Maschinenfabrik GmbH" 909 "Marines Co., Ltd." 908 "Chonbuk National University Department of Electronics" 907 "strautmann" 906 "MOBA AG" 905 "ASA Electronics" 904 "Equipment Safety Systems Pty. Ltd. (EQSS)" 903 "InMotion" 902 "Bucher Hydraulics" 901 "Zivan Srl" 900 "OSB connagtive GmbH (formerly OSB AG)" 899 "Lippert Components, Inc" 898 "Josef Kotte Landtechnik GmbH & Co. KG" 897 "Dot Technology Corp." 896 "NextFour Solutions Ltd" 895 "Peloton Technology" 894 "Rhodan Marine Systems of Florida LLC" 893 "KlinkTechnics Ltd." 892 "Mectronx Corp" 891 "CarrierWeb" 890 "L3 Technologies, Inc." 889 "SANY America Inc" 888 "Carma Systems Inc" 887 "Turntide Transport Limited (formerly Hyperdrive Innovation Limited)" 886 "Hitachi Zosen Corporation" 885 "SICK AG (formerly SICK Stegmann GmbH)" 884 "Sure Grip Controls Inc." 883 "Swift Navigation, Inc." 882 "BHTronik GmbH & Co. KG" 881 "Sovema" 880 "Revision Military" 879 "PG Trionic, Inc." 878 "FOTON" 877 "SICK ATech GmbH" 876 "SUCO Robert Scheuffele GmbH & Co. KG" 875 "Salvarani S.r.l." 874 "MTA S.p.A." 873 "Garnet Instruments Ltd." 872 "Kählig Antriebstechnik GmbH" 871 "Agri-Fab (formerly Superior Tech Inc)" 870 "Textron Fleet Management" 869 "Intercomp" 868 "Data Panel Corp" 867 "Skeleton Technologies" 866 "Netradyne, Inc." 865 "MyEasyFarm" 864 "Streamline Transportation Technologies Inc." 863 "SMAG" 862 "Prospec Electronics" 861 "Adel System S.r.l." 860 "Michelin" 859 "Valor" 858 "Littelfuse" 857 "Zoomlion Heavy Industry NA, Inc" 856 "FarmFacts GmbH" 855 "Toshiba Infrastructure Systems & Solutions Corporation" 854 "GEMAC Chemnitz GmbH" 853 "Teledyne RESON B.V." 852 "Velvac Inc" 851 "Novotechnik Messwertaufnehmer OHG" 850 "Geoprospectors GmbH" 849 "MTS Maschinentechnik Schrode AG" 848 "ningupex" 847 "Oceanvolt" 846 "L3 Magnet-Motor" 845 "GMB Güstrower Maschinenbau GmbH" 844 "FELL AS" 843 "Hendrickson Truck Commercial Vehicle Systems" 842 "DigiDevice Srl" 841 "Agra-GPS" 840 "E.S.T.E. Srl" 839 "Indexator Rotator Systems AB" 838 "Teamsurv Ltd" 837 "Famic Technologies Inc." 836 "Signature4" 835 "PetTrack Ltd." 834 "Pioneer Microsystems, Inc." 833 "Electrum Automation AB" 832 "Heizomat Gerätebau-Energiesysteme GmbH" 831 "DOK-ING Ltd." 830 "Ultra Motion LLC" 829 "Drov Technologies, Inc." 828 "AgriBrink Inc." 827 "INmatix Technology Group Ltd" 826 "Lewmar Marine Inc" 825 "BPW Hungária" 824 "Undheim Systems AS" 823 "ACEINNA, Inc (formerly MEMSIC, Inc)" 822 "Bren-Tronics, Inc." 821 "Thorsen Teknik A/S" 820 "DIaLOGIKa Gesellschaft fuer angewandte Informatik mbH" 819 "Preco Electronics" 818 "HGNSS" 817 "TE Connectivity Sensor Solutions" 816 "UniStrong" 815 "FLIR Systems, Inc." 814 "Kronotech Srl (formerly Soltec Soluzioni Tecnologiche Srl)" 813 "Thales Suisse SA" 812 "Torch Technologies" 811 "Blue Water Desalination" 810 "Dutch Power Company" 809 "HMS Industrial Networks AB" 808 "RIMEX Supply Ltd." 807 "Schneider-Electric" 806 "Charge Automotive Ltd" 805 "Gundersen & Løken AS" 804 "ASA Electronics" 803 "Gill Sensors & Controls Limited" 802 "SPBI (Bj Technologie)" 801 "LOR Manufacturing Company Inc." 800 "Delta-Q Technologies" 799 "Stillwater Designs and Audio, Inc. - KICKER" 798 "Lumishore Ltd" 797 "Tides Marine" 796 "Canadian Automotive Industries Ltd" 795 "Broyda Enterprises Pty Ltd" 794 "Shihlin Electric & Engineering Corporation" 793 "James Fisher Prolec" 792 "Kostal Mexicana" 791 "AUTEC" 790 "VACALL" 789 "GRADALL" 788 "MoTeC Pty Ltd" 787 "Abertax Technologies Limited" 786 "Johnson Matthey Battery Systems" 785 "Fischer Panda GmbH" 784 "CM Automotive Systems, Inc." 783 "Loup Electronics Inc." 782 "AVR nv" 781 "Poly-Planar LLC" 780 "Turntide Transport Limited (formerly AVID Technology Ltd)" 779 "RLC Electronic Systems" 778 "Seakeeper Inc." 725 "Hitachi Construction Machinery Co., Ltd." 724 "Electronic Applications, Inc." 723 "Jabil Inc." 722 "Contelec AG" 721 "Hypro" 720 "WITZ Corporation" 719 "Cojali S. L." 718 "Micronet Inc" 717 "Yacht Devices Ltd" 716 "Eaton Control & Power Conversion Division (CPCD)" 715 "Autonnic Research Ltd" 714 "Kobashi Kogyo Co., Ltd." 713 "US Hybrid Corporation" 712 "LOR Manufacturing Company Inc." 711 "DAS Co., LTD" 710 "Greentronics Ltd." 709 "Marquardt GmbH" 708 "Lars Thrane A/S" 707 "Rochester Gauges Inc" 706 "Shanghai Diesel Engine Corporation Limited" 705 "SVAB Hydraulik AB" 704 "JL Audio, Inc." 703 "Hydro Tab Marine Engineering" 702 "Weichai Power Co., Ltd." 701 "BigRoad Inc." 700 "K-Tec Earthmovers Inc." 699 "Harman International (formerly Harman International Industries)" 698 "Scorpion Technologies Ltd." 697 "Ålö AB" 696 "DRS Network & Imaging Systems, LLC (DRS Technologies)" 695 "Weldon Technologies" 694 "GasTOPS Ltd." 693 "Agility Fuel Solutions (formerly Agility Fuel Systems)" 692 "Tanhay Corporation" 691 "Digitroll Agricultural Electronics" 690 "LINAK A/S" 689 "Aarcomm Systems Inc" 688 "Rockford Corp" 687 "Flight Systems, Inc." 686 "Taigene Electric Machinery Corp." 685 "ANEDO (formerly ANEDO Ltd.)" 684 "KEB" 683 "Fosen Elektro" 682 "Eckelmann AG" 681 "BEDIA Motorentechnik GmbH & Co. KG" 680 "AMVAC Chemical Corporation" 679 "OXE Marine AB (formerly Cimco Marine AB)" 678 "Motive Technologies, Inc. (formerly KeepTruckin, Inc.)" 576 "Vectia" 575 "Lytx" 574 "Vishay Precision Group" 573 "Orolia Ltd" 572 "Fasse Valves" 571 "Marinecraft Co., Ltd." 570 "frenzel + berg electronic GmbH & Co. KG" 569 "LORD MicroStrain Sensing Systems" 568 "Makersan Ltd. Co." 567 "Lithiumstart LLC" 566 "Geode Technology, Inc." 565 "Micro-Trak Systems, Inc." 564 "Auto Power Electronic" 563 "LOHR Sistemas Eletronicos LTDA" 562 "Bombardier Transportation GmbH" 561 "b-plus GmbH" 560 "Iowa State University, Agricultural and Biosystems Engineering" 559 "Four Peaks Navigation" 558 "Davis Instruments Corp." 557 "Rockson Automation GmbH" 556 "Doosan Infracore Norway" 555 "Sasaki Corporation" 554 "iris-GmbH infrared & intelligent sensors" 553 "KIB Electronics" 552 "Matsuyama Plow Mfg Co, Ltd" 551 "Wexler CSD Ltd." 550 "SUN-A Corporation" 549 "ROAD Deutschland GmbH" 548 "TM4 Inc." 547 "Thomson Linear LLC" 546 "Maruyama Mfg Co, Inc." 545 "GS Global Resources (formerly GS Hydraulics)" 544 "Au Group Electronics" 543 "BAUER Maschinen GmbH" 542 "Dinamica Generale s.p.a." 541 "Total Fire Systems, Inc." 540 "Dinex A/S" 539 "Mobileview" 538 "Crop Ventures, Inc." 537 "Schrader Electronics Ltd." 536 "SSI Technologies" 535 "MOTORPAL, a.s." 534 "Webasto Thermo & Comfort SE" 533 "Doran Manufacturing, LLC" 532 "Onwa Marine Electronics Co Ltd." 531 "Genge & Thoma AG" 530 "NMEA" 529 "National Instruments Korea" 528 "Hoganas AB, Electric Drive Systems" 527 "GKN Walterscheid GmbH" 320 "Miedema Landbouwwerktuigenfabriek B.V." 319 "Cadec Global" 318 "SAT Plan" 317 "Navtronics Bvba" 316 "ITT Flow Control" 315 "Icom Incorporated" 314 "CSM GmbH" 313 "Ilmor Engineering, Inc." 312 "Lectronix, Inc." 311 "Patrick Power Products" 310 "TECNORD srl" 309 "Krauss-Maffei Wegmann GmbH & Co. KG" 308 "Cyntrx" 307 "MAS Technologies" 306 "Sleipner Motor AB" 305 "NovAtel Inc" 304 "EmpirBus AB" 303 "CTS Corporation" 302 "Nissin Kogyo Co., LTD" 301 "Parker Hannifin (UK) Ltd FDE group" 300 "Systron Donner Automotive" 299 "Rauch" 298 "Holley Performance" 297 "Zonar Systems Inc" 296 "micro dynamics GmbH" 295 "BEP Marine" 294 "Grayhill Inc." 293 "Spyder Controls Corp." 292 "IKUSI - Angel Iglesias S.A." 291 "Groeneveld Transport Efficiency BV" 290 "Kuebler GmbH" 289 "Watlow" 288 "Mitsubishi FUSO Truck & Bus Corp." 287 "NTech Industries, Inc" 286 "Coelmo srl" 285 "Sea Recovery Corp" 284 "Mobile Tech Chile" 283 "CWF Hamilton & Co Ltd" 282 "Medallion Instrumentation Systems" 281 "Precision Governors LLC" 280 "Leica Geosystems Pty Ltd" 279 "Geometris LP" 278 "Takata Electronics" 277 "LHP Telematics" 276 "Aqua-Hot Heating Systems" 275 "Navico Egersund AS" 274 "LTW Technology Co., LTD" 273 "Active Research Limited" 272 "Gross Mechanical Laboratories, Inc" 271 "Cole Hersee" 270 "Tennant" 269 "Saft America Inc.,  Space & Defense Division" 268 "Accurate Technologies" 677 "DSA Daten- und Systemtechnik GmbH" 676 "Danfoss IXA A/S" 675 "Kawasaki Motors Corp., USA" 674 "Yara International ASA" 673 "Caruelle Nicolas" 672 "OPTIMA Concept" 671 "Innovative Controls Inc." 670 "STEMCO LP" 669 "Quantum Fuel Systems Technologies Worldwide, Inc" 668 "MacDon Industries Ltd." 667 "Bartec" 666 "Schaeffler Technologies AG & Co., KG" 665 "Gebr. Bode GmbH & Co. KG" 664 "Level Developments Ltd" 663 "Delta Systems, Inc" 662 "Kissling Elektrotechnik GmbH" 661 "SPAL Automotive S.r.l." 660 "Auto-Gaz Centrum" 659 "Data Panel Corp." 658 "Shenzhen Jiuzhou Himunication Technology Co., Ltd" 657 "Terzo Power Systems" 656 "PRO SOLUS do Brasil" 655 "Genge & Thoma AG" 654 "Kohler Power Systems, Detroit Engine Development Center (DEDC)" 653 "AEV, spol. s r. o." 652 "MicroControl GmbH & Co. KG" 651 "Takakita Co, Ltd." 650 "Seiko Epson Corp." 649 "Control-Q B.V." 648 "OJSC Ekran" 647 "Siloking" 646 "Veenhuis Machines B.V." 645 "esd electronic system design gmbh" 644 "KUS USA" 643 "Bogballe A/S" 642 "Moog / Aspen Motion Technologies" 641 "Diverse Yacht Services" 640 "Power Solutions International" 639 "Startec s.r.l." 638 "KVH Industries, Inc." 637 "Bavaria Yachtbau GmbH" 636 "Divelbiss Corporation" 635 "Argo Tractors S.p.A." 634 "Rocky Research" 633 "TORC Robotics" 632 "Pepperl+Fuchs GmbH" 631 "Reltima" 630 "SmartDrive Systems Inc." 629 "Agri Info Design, Ltd." 628 "Falck Schmidt Defence Systems" 627 "Radio Ocean" 626 "AVL DiTEST GmbH" 625 "Global MRV Inc." 624 "Blackbox Machine Control Pty Ltd" 623 "Xirgo Technologies" 622 "Floyd Bell Inc" 621 "Hagie Manufacturing Company" 620 "Sevcon Ltd." 619 "Right Weigh Load Scales" 618 "Evrard SA" 617 "Zero Emission Vehicles" 616 "SMART-TEC s.r.o." 615 "Networkfleet, Verizon Telematics" 614 "ARLT Technologies GmbH" 613 "HKS Co., Ltd." 612 "Samwon IT" 611 "Esterline" 610 "Trail Tech" 609 "Walvoil S.p.A." 608 "Gale Banks Engineering" 607 "Knappco/Civacon" 606 "Intellian Technologies" 605 "Aventics GmbH" 604 "Rototilt Group AB (formerly Indexator Rototilt Systems AB)" 603 "Kereval" 602 "Nomad Digital Ltd." 601 "Navitas Systems" 600 "Aquatic AV" 599 "Spudnik Equipment Co, LLC" 598 "ABB Turbo Systems Ltd" 597 "Hydac Filter Systems GmbH" 596 "Brunelco Electronic Innovators B.V." 595 "CustomWare" 594 "Kongsberg Automotive" 593 "Sensata Technologies" 592 "tecsis GmbH" 591 "United States Coast Guard" 590 "ARGO-HYTOS GMBH" 589 "MICO, Inc." 588 "Vignal Systems" 587 "JCA Electronics" 586 "Suzuki Motor Corp" 585 "Industrial Electronic Controls" 584 "CarMedialab GmbH" 583 "Yachtcontrol" 582 "Innovative Software Engineering" 581 "Väderstad AB (formerly Väderstad - Verken AB)" 580 "San Jose Technology, Inc." 579 "KVH Industries, Inc." 578 "advanSea" 577 "Denchi Power Ltd  (formerly ABSL Power Solutions Limited)" 526 "LOFA Industries, Inc" 525 "Rust Sales INC" 524 "Vomax Instrumentation Pty. Ltd." 523 "Reggio Emilia Innovazione" 522 "Nebraska Tractor Test Laboratory" 521 "Clever Devices Ltd." 520 "Trapeze" 519 "Peeters Landbouwmachines b.v." 518 "Transas USA Inc." 517 "Noland Engineering" 516 "AVAT Automation GmbH" 515 "GINAF Trucks Nederland B.V." 514 "DISTek Integration, Inc." 513 "Precision Technology" 512 "Inpower LLC" 511 "Burel Production (formerly Sulky)" 510 "Marinesoft Co. Ltd" 509 "MOTORTECH GmbH" 508 "Transtech Innovations" 507 "ISOBUS Test Center" 506 "IHI STAR Machinery Corporation" 505 "Yetter Farm Equipment" 504 "Vesper Marine" 503 "Naviop S.R.L." 502 "Attwood Corporation" 501 "Agrotronix S.A." 500 "Oxbo International Corporation" 499 "LCJ Capteurs" 498 "Innovative Design Solutions, Inc." 497 "SENTRON Sistemas Embarcados" 496 "W. Gessmann GmbH" 495 "HOLMER Maschinenbau GmbH" 494 "Synerject" 493 "Watcheye" 492 "Inergy Automotive Systems" 491 "Penny and Giles Ltd" 490 "QuikQ" 489 "Appareo Systems, LLC" 488 "The Charles Machine Works, Inc." 487 "DSE Test Solutions A/S" 486 "Westport Innovations Inc." 485 "MATT automotive" 484 "Headsight Inc." 483 "Valeo" 482 "Tricon Electronics" 481 "Chetco Digital Instruments" 480 "EnerDel, Inc." 479 "Vapor Bus International" 478 "OceanSat B.V." 477 "OilQuick AB" 476 "Hummingbird Marine Electronics" 475 "GME" 474 "Persen Technologies Inc." 473 "Boss Industries, Inc." 472 "Tenneco Inc." 471 "Sea Cross Marine AB" 470 "SI-TEX Marine Electronics" 469 "RA Consulting GmbH" 468 "Tyco Fire Protection Products" 467 "Lely Industries N.V." 466 "Veethree Electronics and Marine LLC" 465 "Ashcroft Inc" 464 "Leach International Corporation" 463 "PROBOTIQ" 462 "IHI Shibaura Machinery Corporation" 461 "HAWE Hydraulik SE" 460 "San Giorgio S.E.I.N." 459 "Alltek Marine Electronics Corp" 458 "Control Solutions, Inc." 457 "RUSELPROM-ElectricDrive Ltd" 456 "General Kinetics" 455 "ADZ NAGANO GmbH" 454 "NGK Spark Plug Co. Ltd" 453 "Cooper Bussmann" 452 "WIKA Alexander Wiegand SE & Co. KG" 451 "Parker Hannifin Corp" 450 "Dycor Technologies Ltd." 449 "Polaris Industries Inc" 448 "Stanadyne Corporation, Electronics Systems" 447 "Great Plains Mfg." 446 "CertTech, L.L.C." 445 "KAT MECHATRONIC, Electronic Product Division" 444 "ITT Power Solutions" 443 "SignalQuest, Inc." 442 "Horsch Maschinen GmbH" 441 "PTG Reifendruckregelsysteme GmbH" 440 "Cummins Power Generation" 439 "Hyundai Heavy Industries" 438 "Comar Systems Ltd" 437 "Digital Yacht Limited" 436 "Kinze Manufacturing" 435 "Zunhammer GmbH" 434 "Stored Energy Systems" 433 "Rowe Electronics" 432 "S&A Systems, Inc." 431 "Tohatsu Corporation" 430 "Auteq Telematica S.A." 429 "Rota Engineering Ltd." 425 "Methode Electronics Inc, MDI" 424 "Odyne LLC" 423 "BSM Wireless, Inc." 422 "True Heading AB" 421 "Vertex Standard Co, Ltd" 420 "Vermeer Corporation, ACS Group" 419 "Fusion Electronics Ltd" 418 "Intellistick Inc" 417 "KZValve" 416 "Kubota Corporation" 415 "Valid Manufacturing Ltd." 414 "Cattron Group International" 413 "Datapross Nijbroek bv" 412 "WebTech Wireless Inc." 411 "Hy-Drive Technologies Ltd." 410 "COBO S.p.A. Divisione 3B6" 409 "Transfluid S.r.L." 408 "Corvus Energy Ltd." 407 "Comtech Mobile Datacom" 406 "Vecima Networks Inc." 405 "Wema System AS" 404 "Com Nav Marine Ltd" 403 "Trackwell ADS, Inc." 402 "Simma Software, Inc." 401 "Torqeedo GmbH" 400 "Livorsi Marine" 399 "ISEKI & Co., Ltd." 398 "Hilite International" 397 "Sanyo-kiki Co Ltd." 396 "Beyond Measure" 395 "GENTEC S.R.L." 394 "Capi 2 Nederland B.V." 393 "Harvest Tec, Inc" 392 "Tianyuan Technology Co Ltd." 391 "Electronic Design for Industry, Inc" 390 "Partech Inc." 389 "Benchmark Electronics, Minnesota Division" 388 "Innomatix, LLC" 387 "Orscheln Products, LLC" 386 "JLG Automation BVBA" 385 "Johnson Outdoor Marine Electronics" 384 "Camano Light" 383 "MCL Industries" 382 "National Agriculture and Food Research Organization" 381 "B & G" 380 "Suntech International Ltd." 379 "Yamabiko Corporation" 378 "Glendinning Marine Products" 377 "ifm electronic gmbh" 376 "Quake Global" 375 "Williams Controls Inc." 374 "Northern Lights, Inc." 373 "Electronic Design Inc." 372 "Delphi" 371 "Heinzmann GmbH & Co. KG" 370 "Rolls-Royce Marine AS" 369 "Power Torque Engineering Ltd" 368 "HANSENHOF_electronic" 367 "Fliegl Agrartechnik" 366 "Viewnyx Corp." 365 "Digi-Star, LLC" 364 "OEM Controls Inc." 363 "BEI Duncan" 362 "Poettinger Landtechnik GmbH (formerly Alois Poettinger Maschinenfabrik GmbH)" 361 "InMach" 360 "HJS Emission Technology GmbH & Co KG   (formerly HJS Fahrzeugtechnik GmbH & Co KG)" 359 "Ludwig Bergmann GmbH" 358 "Victron Energy B.V." 357 "Hardi International A/S" 356 "Fischer Panda Generators, Inc" 355 "Mastervolt International B.V." 354 "Junkkari OY" 353 "Hegemon Electronics, Inc." 352 "SAME DEUTZ-FAHR GROUP S.p.A." 351 "Thrane & Thrane" 350 "Noris Marine Systems GmbH & Co KG" 349 "Suonentieto" 348 "Amazonen Werke H. Dreyer" 347 "Honeywell" 346 "Control Solutions" 345 "Korean Maritime University" 344 "Parvus Corporation" 343 "Baumer Group" 342 "THOMAS MAGNETE GmbH" 341 "Boning GmbH & Co" 340 "Continental AG" 339 "Competence Center ISOBUS e.V." 338 "GRAF-SYTECO" 337 "Carraro S.p.A." 336 "APE s.r.o." 335 "Evo Electric Ltd" 334 "Takata-Petri AG" 333 "Link Manufacturing, Ltd. (formerly Hadley Products Corporation)" 332 "HWH Corporation" 331 "Horton, Inc." 330 "Kidde Aerospace and Defense" 329 "Deif A/S" 328 "Qwerty Electronik AB" 327 "Sonceboz SA" 326 "Akron Brass Company" 325 "ASM Automation Sensorik Messtechnik GmbH" 324 "Snap-on Diagnostics" 323 "Mobileye Vision Technologies Ltd." 322 "MICHENKA s.r.o." 321 "Ultra Electronics, Electrics" 267 "Red Lion Controls, Inc" 266 "International Thermal Research Ltd" 265 "MTS Sensor Technologie GmbH" 264 "Autolync" 263 "IMMI" 262 "HydraForce, Inc" 261 "Red Dot Corporation" 260 "Reichhardt GmbH Steuerungstechnik" 259 "Jetter AG" 258 "ARAG" 257 "Honda Motor Co., Ltd" 256 "Tyco Electronics AMP" 255 "MEAS France" 254 "GE Sensing" 253 "Mobile Control Systems" 252 "Sensor-Technik Wiedemann GmbH" 251 "German Agricultural Society, Test Center (DLG)" 250 "Kuhn Group" 249 "Schaltbau GmbH" 248 "Cooper Standard Automotive Active Systems Group" 247 "ePULSE" 246 "Class 1, Inc" 245 "Capstan Ag Systems, Inc." 244 "Techno-Matic" 243 "eRide, Inc." 242 "Kokusandenki Co. Ltd" 241 "Schneider Automation SAS" 240 "Vanair Manufacturing" 239 "May & Scofield Ltd" 238 "ZF Friedrichshafen AG" 237 "Agtron Enterprises Inc" 236 "NORAC Systems International Inc" 235 "SailorMade Marine Telemetry - Tetra Technology Ltd." 234 "Mondial electronic GmbH" 233 "Yacht Monitoring Solutions Inc." 232 "TSD Integrated Controls" 231 "Topcon Positioning Systems, Inc." 230 "Saucon Technologies" 229 "Garmin International Inc." 228 "Unused (formerly ZF Marine Electronics)" 227 "Lykketronic A/S" 226 "Monaco Coach Corporation" 225 "SKF" 224 "EMMI Network, S.L." 223 "Vaueo Retarder Co., Ltd." 222 "Generac Power Systems, Inc." 221 "SiE" 220 "Beede Electrical Instrument Company, Inc" 219 "Cat OEM Solutions" 218 "Gits Manufacturing Company" 217 "RM Michaelides Software & Elektronik GmbH" 216 "Paneltronics Inc." 215 "Aetna Engineering/Fireboy-Xintex" 214 "MC elettronica Srl" 213 "CNH Belgium N.V." 212 "Sure Power Industries, Inc" 211 "DNA Group" 210 "Iteris, Inc." 209 "Bell Equip. Co. SA (PTY) LTD" 208 "Drew Technologies, Inc" 207 "Otto Engineering" 206 "port GmbH" 205 "SmarTire Systems Inc" 204 "The Morey Corporation" 203 "MILtronik GmbH" 202 "Curtis Instruments, Inc" 201 "Disenos y Tecnologia S.A." 200 "MGM Brakes" 199 "ACTIA Group (formerly Actia Corp)" 198 "Mystic Valley Communications" 197 "Mechron Power Systems" 196 "LEMKEN GmbH & Co KG" 195 "General Engine Products" 194 "TriMark Corporation" 193 "Jeppesen Marine" 192 "Floscan" 191 "XRS Corporation (formerly XATA Corporation)" 190 "Hella KGaA Hueck & Co" 189 "QUALCOMM" 188 "EMP Corp" 187 "Air-Weigh" 186 "Altronic, Inc" 185 "Beede Electrical Instrument Company" 184 "EIA Electronics" 183 "KDS Controls, Inc" 182 "Vehicle Systems Engineering B.V." 181 "Coretronics, Inc." 180 "Smart Power Systems" 179 "TeeJet Technologies Springfield (formerly Midwest Technologies Illinois, LLC)" 178 "Continental Automotive GmbH (formerly Siemens VDO Automotive AG)" 177 "Diagnostic Systems Associates" 176 "Moritz Aerospace" 175 "Veris Technologies, Inc." 174 "AB Volvo Penta" 173 "Ryeso, Inc." 172 "Yanmar Co., Ltd. (formerly Yanmar Marine USA)" 171 "Topcon Electronics GmbH & Co. KG (formerly Wachendorff Elektronik GmbH & Co. KG)" 170 "Computronics Corporation Ltd." 169 "Marlin Technologies Inc." 168 "Xantrex" 167 "JLG Industries Inc" 166 "John Deere Electronic Solutions (formerly Phoenix International)" 165 "CPAC Systems AB" 164 "MTU Friedrichshafen GmbH (formerly DaimlerChrysler Off-Highway)" 163 "BRP Inc." 162 "Axiomatic Technologies" 161 "Offshore Systems (UK) Ltd" 160 "Nido" 159 "NTech Industries Inc" 158 "Firestone Industrial Products Company" 157 "ISSPRO Inc." 156 "ITT Industries - Cannon" 155 "Vetronix Corporation" 154 "Westerbeke Corporation" 153 "Woodward, Industrial Controls Division" 152 "elobau GmbH & Co. KG" 151 "Raven Industries, Inc." 150 "Fleetguard" 149 "Holset" 148 "Blue Water Data, Inc." 147 "Nautibus electronic GmbH" 146 "Maxima Technologies" 145 "MurCal Controls" 144 "Mercury Marine" 143 "W. Gmeiner GmbH & Co." 142 "TRW Automotive (Commercial Steering Systems)" 141 "Thales Navigation Ltd." 140 "Lowrance Electronics, Inc." 139 "Caterpillar Trimble Control Technologies (CTCT), LLC" 138 "Georg Fritzmeier GmbH & Co. KG" 137 "Littelfuse, Inc (formerly Maretron)" 136 "Komatsu Ltd" 135 "Airmar Technology Corporation" 134 "Iris Technology Ltd" 133 "Bucher Schoerling GmbH" 132 "Mulag-Fahrzeugwerk" 131 "ITT Industries" 130 "Nido - Universal Machines B.V." 129 "OMNEX Control Systems Inc." 128 "Gerhard Duecker GmbH & Co. KG" 127 "Holland USA" 126 "Driver Tech" 125 "Nevada Automotive Test Center" 124 "Hydac Electronic" 123 "Basler Electric" 122 "FG Wilson (Engineering) Limited" 121 "HED (Hydro Electronic Devices, Inc.)" 120 "RDS Technology Ltd" 119 "IntegriNautics  " 118 "Intron GmbH" 117 "HUSCO International" 116 "BEELINE Technologies" 115 "NACCO Materials Handling Group, Inc." 114 "EControls, Inc." 113 "Stress-Tek, Inc." 112 "MECALAC" 111 "Bernard Krone Holding SE & Co. KG (formerly Maschinenfabrik Bernard Krone GmbH)" 110 "EPIQ Sensor-Nite" 109 "TeeJet Technologies Denmark (formerly LH Technologies ApS)" 108 "WTK-Elecktronik GmbH" 107 "Grimme Landmaschinen GmbH & Co. KG" 106 "BAE Systems Controls, Inc." 105 "Kiepe Elektrik GmbH & Co. KG" 104 "CLAAS KGaA mbH (formerly CLAAS Selbstfahrende Erntemaschinen GmbH)" 103 "CLAAS E-Systems GmbH (formerly CLAAS E-Systems KGaA mbH & Co. KG)" 102 "AGCO (formerly AGCO GmbH & Co.)" 101 "Sensoria" 100 "VDO Technik AG" 99 "International Transmissions Ltd (ITL)" 98 "Mueller-Elektronik GmbH & Co" 97 "Ag Leader Technology, Inc." 96 "Mech@tronic IT GmbH" 95 "Pacific Insight Electronics Corp." 94 "CNH Industrial N.V. (formerly CNH Global N.V.)" 93 "Perkins Engines Company Ltd." 92 "Ag-Chem Equipment Co., Inc." 91 "BSG Bodensee Steuergeraete GmbH" 90 "Knorr-Bremse SfN GmbH" 89 "Kverneland Group, Electronics Division" 88 "Hemisphere GPS Inc (formerly Satloc Precision GPS)" 87 "J.C. Bamford Excavators Ltd (JCB)" 86 "C. E. Niehoff & Company" 85 "Kohler Co" 84 "New Holland UK Limited" 83 "Bendix VORAD Technologies (formerly Eaton VORAD Technologies)" 82 "Bobcat/Ingersoll-Rand (formerly Melroe/Ingersoll-Rand)" 81 "Fire Research Corp." 80 "Twin Disc, Inc." 79 "Daimler Benz AG - Engine Division (PBM)" 78 "Frank W. Murphy Manufacturing, Inc" 77 "Deere Power Systems Group" 76 "unused (formerly Deere & Co, Construction Division)" 75 "Deere & Co, Agricultural Division" 74 "Eaton Axle-Brake Division" 73 "LeTourneau, Inc." 72 "Sisu Corporation" 71 "Vansco Electronics Ltd." 70 "Flex-coil Limited" 69 "Trimble Navigation" 68 "Scania" 67 "John Deere Coffeyville Works (formerly Funk Manufacturing Company)" 66 "John Deere Construction Equipment Division" 65 "MAN Nutzfahrzeuge AG" 64 "Unused (formerly SpectraPrecision Laserplane, then SpectraPhysics)" 63 "ZF Industries Inc." 62 "Wabco" 61 "Volvo Truck Corp." 60 "Volvo Trucks North America Inc." 59 "VES Inc." 58 "SPX Corporation, OTC Div" 57 "Danfoss  (formerly Sauer Sundstrand Co, then Sauer-Danfoss Co)" 56 "SAIC" 55 "Ryder System Inc." 54 "Meritor Wabco" 53 "Continental Automotive Systems US, Inc. (formerly Rockwell Land Transportation)" 52 "Meritor Automotive, Inc. (formerly Rockwell Automotive)" 51 "Robert Bosch GmbH" 50 "Robert Bosch Corp" 49 "RE America Inc." 48 "Pollak Alphabet" 47 "Phillips Semiconductor" 46 "Noregon Systems, LLC  (formerly Noregon Systems, Inc)" 45 "PACCAR" 44 "Nippondenso Co. Ltd." 43 "International Truck and Engine Corporation - Vehicle Electronics (formerly Navistar Intl Trans Corp.)" 42 "International Truck and Engine Corporation - Engine Electronics  (formerly Navistar Intl Trans Co., Engine Electronics)" 41 "Motorola Inc." 40 "Motorola AIEG Inc." 39 "Microfirm Inc." 38 "Micro Processor Systems Inc." 37 "Mack Trucks Inc." 36 "Lucas Ind." 35 "Kenworth Truck Co." 34 "Kelsey Hayes Co." 33 "John Deere" 32 "Jacobs Vehicle Systems" 31 "J Pollak Corp" 30 "Isuzu Motors Ltd" 29 "Hino Motors Ltd." 28 "Grote Ind. Inc." 27 "GMC" 26 "General Motors Corp, Service Technology Grp" 25 "Daimler Trucks North America LLC (formerly Freightliner LLC)" 24 "Ford Motor Co., Vehicle Controls" 23 "Ford Motor Co., Heavy Truck" 22 "Ford Motor Co., Electronic Concepts & Systems" 21 "Echlin Inc., Midland Brake Inc." 20 "Eaton Ltd" 19 "Eaton Corp. Trucking Info Services" 18 "Eaton Corp, Transmission Div." 17 "Eaton Corp, Corp Res & Dev" 16 "Eaton Corp" 15 "DICKEY-john Corporation" 14 "Detroit Diesel Corporation" 13 "Delco Electronics" 12 "Deere & Company, Precision Farming" 11 "Dearborn Group Inc." 10 "Cummins Inc (formerly Cummins Engine Co)" 9 "Chrysler Corp." 8 "Caterpillar Inc." 7 "Case Corp." 6 "Berifors Electronics AB" 5 "AMP Inc." 4 "Ametek-Dixson" 3 "Ametek, US Gauge Division" 2 "Allison Transmission, Inc." 1 "Bendix Commercial Vehicle Systems LLC (formerly Allied Signal Inc.)" 0 "Reserved" ;
VAL_ 2559835902 NMControlModeIndicator 0 "Set Pending NAME" 1 "Pending NAME Response" 2 "Current NAME Response" 3 "Set Pending NAME ACK" 4 "Set Pending NAME NACK" 5 "Request Pending Name" 6 "Request Current Name" 7 "Adopt Pending Name" 8 "Request Address Claim" 9 "Reserved for future SAE use" 10 "Reserved for future SAE use" 11 "Reserved for future SAE use" 12 "Reserved for future SAE use" 13 "Reserved for future SAE use" 14 "Reserved for future SAE use" 15 "Reserved for future SAE use" ;
VAL_ 2558983934 SwitchedPowerOutput18Cmd 3 "Take no action" 2 "Reserved" 1 "Output on" 0 "Output off" ;
VAL_ 2558983934 SwitchedPowerOutput19Cmd 3 "Take no action" 2 "Reserved" 1 "Output on" 0 "Output off" ;
VAL_ 2558983934 SwitchedPowerOutput20Cmd 3 "Take no action" 2 "Reserved" 1 "Output on" 0 "Output off" ;
VAL_ 2558983934 SwitchedPowerOutput13Cmd 3 "Take no action" 2 "Reserved" 1 "Output on" 0 "Output off" ;
VAL_ 2558983934 SwitchedPowerOutput14Cmd 3 "Take no action" 2 "Reserved" 1 "Output on" 0 "Output off" ;
VAL_ 2558983934 SwitchedPowerOutput15Cmd 3 "Take no action" 2 "Reserved" 1 "Output on" 0 "Output off" ;
VAL_ 2558983934 SwitchedPowerOutput16Cmd 3 "Take no action" 2 "Reserved" 1 "Output on" 0 "Output off" ;
VAL_ 2558983934 SwitchedPowerOutput9Cmd 3 "Take no action" 2 "Reserved" 1 "Output on" 0 "Output off" ;
VAL_ 2558983934 SwitchedPowerOutput10Cmd 3 "Take no action" 2 "Reserved" 1 "Output on" 0 "Output off" ;
VAL_ 2558983934 SwitchedPowerOutput29Cmd 3 "Take no action" 2 "Reserved" 1 "Output on" 0 "Output off" ;
VAL_ 2558983934 SwitchedPowerOutput30Cmd 3 "Take no action" 2 "Reserved" 1 "Output on" 0 "Output off" ;
VAL_ 2558983934 SwitchedPowerOutput31Cmd 3 "Take no action" 2 "Reserved" 1 "Output on" 0 "Output off" ;
VAL_ 2558983934 SwitchedPowerOutput32Cmd 3 "Take no action" 2 "Reserved" 1 "Output on" 0 "Output off" ;
VAL_ 2558983934 SwitchedPowerOutput25Cmd 3 "Take no action" 2 "Reserved" 1 "Output on" 0 "Output off" ;
VAL_ 2558983934 SwitchedPowerOutput26Cmd 3 "Take no action" 2 "Reserved" 1 "Output on" 0 "Output off" ;
VAL_ 2558983934 SwitchedPowerOutput27Cmd 3 "Take no action" 2 "Reserved" 1 "Output on" 0 "Output off" ;
VAL_ 2558983934 SwitchedPowerOutput28Cmd 3 "Take no action" 2 "Reserved" 1 "Output on" 0 "Output off" ;
VAL_ 2558983934 SwitchedPowerOutput21Cmd 3 "Take no action" 2 "Reserved" 1 "Output on" 0 "Output off" ;
VAL_ 2558983934 SwitchedPowerOutput22Cmd 3 "Take no action" 2 "Reserved" 1 "Output on" 0 "Output off" ;
VAL_ 2558983934 SwitchedPowerOutput23Cmd 3 "Take no action" 2 "Reserved" 1 "Output on" 0 "Output off" ;
VAL_ 2558983934 SwitchedPowerOutput24Cmd 3 "Take no action" 2 "Reserved" 1 "Output on" 0 "Output off" ;
VAL_ 2558983934 SwitchedPowerOutput17Cmd 3 "Take no action" 2 "Reserved" 1 "Output on" 0 "Output off" ;
VAL_ 2558983934 SwitchedPowerOutput11Cmd 3 "Take no action" 2 "Reserved" 1 "Output on" 0 "Output off" ;
VAL_ 2558983934 SwitchedPowerOutput12Cmd 3 "Take no action" 2 "Reserved" 1 "Output on" 0 "Output off" ;
VAL_ 2558983934 SwitchedPowerOutput5Cmd 3 "Take no action" 2 "Reserved" 1 "Output on" 0 "Output off" ;
VAL_ 2558983934 SwitchedPowerOutput6Cmd 3 "Take no action" 2 "Reserved" 1 "Output on" 0 "Output off" ;
VAL_ 2558983934 SwitchedPowerOutput7Cmd 3 "Take no action" 2 "Reserved" 1 "Output on" 0 "Output off" ;
VAL_ 2558983934 SwitchedPowerOutput8Cmd 3 "Take no action" 2 "Reserved" 1 "Output on" 0 "Output off" ;
VAL_ 2558983934 SwitchedPowerOutput1Cmd 3 "Take no action" 2 "Reserved" 1 "Output on" 0 "Output off" ;
VAL_ 2558983934 SwitchedPowerOutput2Cmd 3 "Take no action" 2 "Reserved" 1 "Output on" 0 "Output off" ;
VAL_ 2558983934 SwitchedPowerOutput3Cmd 3 "Take no action" 2 "Reserved" 1 "Output on" 0 "Output off" ;
VAL_ 2558983934 SwitchedPowerOutput4Cmd 3 "Take no action" 2 "Reserved" 1 "Output on" 0 "Output off" ;
VAL_ 2349727486 CoastModeDisReq 3 "Not Available" 2 "Error" 1 "Request to disable Transmission Coast Mode" 0 "No request to disable Transmission Coast Mode" ;
VAL_ 2349727486 DisengageDiffLockReqRearAxle3 3 "Take no action" 2 "Reserved" 1 "Disengage differential lock" 0 "Engage differential lock" ;
VAL_ 2349727486 Mode20 1 "Enable" 0 "Disable" 3 "Take no action" 2 "Reserved" ;
VAL_ 2349727486 Mode19 3 "Take no action" 2 "Reserved" 1 "Enable" 0 "Disable" ;
VAL_ 2349727486 Mode18 3 "Take no action" 2 "Reserved" 1 "Enable" 0 "Disable" ;
VAL_ 2349727486 Mode17 3 "Take no action" 2 "Reserved" 1 "Enable" 0 "Disable" ;
VAL_ 2349727486 Mode16 3 "Take no action" 2 "Reserved" 1 "Enable" 0 "Disable" ;
VAL_ 2349727486 Mode15 3 "Take no action" 2 "Reserved" 1 "Enable" 0 "Disable" ;
VAL_ 2349727486 Mode14 3 "Take no action" 2 "Reserved" 1 "Enable" 0 "Disable" ;
VAL_ 2349727486 Mode13 3 "Take no action" 2 "Reserved" 1 "Enable" 0 "Disable" ;
VAL_ 2349727486 Mode12 3 "Take no action" 2 "Reserved" 1 "Enable" 0 "Disable" ;
VAL_ 2349727486 Mode11 3 "Take no action" 2 "Reserved" 1 "Enable" 0 "Disable" ;
VAL_ 2349727486 SelectedMaxGearLmtActReq 3 "Don't Care / Take No Action" 2 "Reserved" 1 "Limit is requested" 0 "Limit is not requested" ;
VAL_ 2349727486 ReqReverseLaunchGear 12 "Reserved" 11 "Reserved" 10 "Reserved" 9 "Reserved" 8 "Reserved" 7 "Reserved" 6 "Reserved" 5 "Reserved" 4 "Launch the vehicle in Reverse 4" 15 "Not Available" 14 "Error" 13 "Allow transmission to select the optimum Reverse launch gear" 3 "Launch the vehicle in Reverse 3" 2 "Launch the vehicle in Reverse 2" 1 "Launch the vehicle in Reverse 1" 0 "No specific Reverse launch gear requested" ;
VAL_ 2349727486 OutShaftBrkReq 3 "Don't Care / Take No Action" 2 "Reserved" 1 "Transmission output shaft braking is requested" 0 "Transmission output shaft braking is not requested" ;
VAL_ 2349727486 PreDefinedMaxGearActReq 3 "Don't Care / Take No Action" 2 "Reserved" 1 "Pre-defined range limit is requested" 0 "Pre-defined range limit is not requested" ;
VAL_ 2349727486 TransMode10 3 "Take no action" 2 "Reserved" 1 "Enable" 0 "Disable" ;
VAL_ 2349727486 TransMode9 3 "Take no action" 2 "Reserved" 1 "Enable" 0 "Disable" ;
VAL_ 2550988542 ClutchEngageReqStatus 3 "Not available" 2 "Error" 1 "Engine has an external request" 0 "Engine does not have an external request" ;
VAL_ 2550988542 ReadyForClutchEngagementStatus 3 "Not available" 2 "Error" 1 "Engine is Ready For Clutch Engagement" 0 "Engine Not Ready For Clutch Engagement" ;
VAL_ 2566767358 EngFuelIsolationCtrl 3 "Don't care / take no action" 2 "Reserved" 1 "Gaseous Fuel is Used" 0 "Gaseous Fuel Migration is Prevented" ;
VAL_ 2566767358 FuelType 255 "Not available, Parameter not supported)" 254 "Error" 32 "Heavy Fuel Oil" 31 "Kerosene" 30 "Hydrogen Internal Combustion Engine" 29 "Fuel Cell Utilizing Hydrogen" 28 "Dual Fuel, Diesel and LNG" 27 "Dual Fuel, Diesel and CNG" 26 "Natural Gas, Compressed or Liquefied Natural Gas)" 25 "Bi-fuel using diesel" 24 "Bi-fuel vehicle using NG" 23 "Natural Gas, NG)" 22 "Hybrid vehicle in regeneration mode" 21 "Hybrid vehicle using battery and combustion engine" 20 "Hybrid vehicle using battery" 19 "Hybrid vehicle using diesel engine" 18 "Hybrid vehicle using gasoline engine on ethanol" 17 "Hybrid vehicle using gasoline engine" 16 "Bi-fuel vehicle using battery and combustion engine" 15 "Bi-fuel vehicle using battery" 14 "Bi-fuel vehicle using propane" 13 "Bi-fuel vehicle using CNG" 12 "Bi-fuel vehicle using LPG" 11 "Bi-fuel vehicle using ethanol" 10 "Bi-fuel vehicle using methanol" 9 "Bi-fuel vehicle using gasoline" 8 "Battery/electric" 7 "Propane" 6 "Compressed Natural Gas" 5 "Liquefied Petroleum Gas" 4 "Diesel" 3 "Ethanol" 2 "Methanol" 1 "Gasoline/petrol" 0 "Not available, NONE" ;
VAL_ 2566706686 DEFXferPumpPurgeRelay 3 "Not available" 2 "Error" 1 "On " 0 "Off " ;
VAL_ 2566706686 PwrSupply 3 "Unavailable" 2 "Error" 1 "On: The ECU is powering the aftertreatment 1 DEF pump power output" 0 "Off" ;
VAL_ 2566706686 DosingUnit1HtrRelay 3 "Not available" 2 "Error" 1 "On" 0 "Off" ;
VAL_ 2566705150 AFT2InNOxSnsrSelfDiagTrigger 15 "Not supported" 14 "Reserved" 13 "Reserved" 12 "Reserved" 11 "Reserved" 10 "Reserved" 9 "Reserved" 8 "Reserved" 7 "Reserved" 6 "Reserved" 5 "Reserved" 4 "NOx Sensor EEB2 Self-diagnosis Request at after run" 3 "NOx Sensor EEB2 Self-diagnosis Request at fuel cut" 2 "NOx Sensor EEB2 Self-diagnosis Request at partial load" 1 "NOx Sensor EEB2 Self-diagnosis Request at Lambda=1.0" 0 "Diagnostic mode disabled" ;
VAL_ 2566705150 A2OutNOxSnsrSelfDiagTrigger 15 "Not supported" 4 "NOx Sensor ATO2 Self-diagnosis Request at After Run" 3 "NOx Sensor ATO2 Self-diagnosis Request at fuel cut" 2 "NOx Sensor ATO2 Self-diagnosis Request at partial load" 1 "NOx Sensor ATO2 Self-diagnosis Request at Lambda=1.0" 0 "Diagnostic mode disabled" ;
VAL_ 2566705150 AFT1InNOxSnsrSelfDiagTrigger 15 "Not supported" 14 "Reserved" 13 "Reserved" 12 "Reserved" 11 "Reserved" 10 "Reserved" 9 "Reserved" 8 "Reserved" 7 "Reserved" 6 "Reserved" 5 "Reserved" 4 "NOx Sensor EEB1 Self-diagnosis Request at after run" 3 "NOx Sensor EEB1 Self-diagnosis Request at fuel cut" 2 "NOx Sensor EEB1 Self-diagnosis Request at partial load" 1 "NOx Sensor EEB1 Self-diagnosis Request at Lambda=1.0" 0 "Diagnostic mode disabled" ;
VAL_ 2566705150 A1OutNOxSnsrSelfDiagTrigger 15 "Not supported" 4 "NOx Sensor ATO1 Self-diagnosis Request at After Run" 3 "NOx Sensor ATO1 Self-diagnosis Request at fuel cut" 2 "NOx Sensor ATO1 Self-diagnosis Request at partial load" 1 "NOx Sensor ATO1 Self-diagnosis Request at Lambda=1.0" 0 "Diagnostic mode disabled" ;
VAL_ 2566704382 A1Out2GasSnsrPwrSupply 3 "Unavailable" 2 "Error" 1 "On: The ECU is powering the Aftertreatment 1 Outlet 2 Gas Sensor" 0 "Off" ;
VAL_ 2566704382 AFT1In2GasSnsrPwrSupply 3 "Unavailable" 2 "Error" 1 "On: The ECU is powering the Engine Exhaust 1 Intake 2 Gas Sensor" 0 "Off" ;
VAL_ 2566704382 A2Out1GasSnsrPwrSupply 3 "Unavailable" 2 "Error" 1 "On: The ECU is powering the Aftertreatment 2 Outlet 1 Gas Sensor" 0 "Off" ;
VAL_ 2566704382 AFT2In1GasSnsrPwrSupply 3 "Unavailable" 2 "Error" 1 "On: The ECU is powering the Aftertreatment 2 Intake 1 Gas Sensor" 0 "Off" ;
VAL_ 2566704382 A1Out1GasSnsrPwrSupply 3 "Unavailable" 2 "Error" 1 "On: The ECU is powering the Aftertreatment 1 Outlet 1 Gas Sensor" 0 "Off" ;
VAL_ 2566704382 AFT1In1GasSnsrPwrSupply 3 "Unavailable" 2 "Error" 1 "On: The ECU is powering the Aftertreatment 1 Intake 1 Gas Sensor" 0 "Off" ;
SG_MUL_VAL_ 2559835902 CommandedAAC NMControlModeIndicator 0-3, 8-8;
SG_MUL_VAL_ 2559835902 CommandedIndustryGroup NMControlModeIndicator 0-3, 8-8;
SG_MUL_VAL_ 2559835902 CommandedVehicleSystemInstance NMControlModeIndicator 0-3, 8-8;
SG_MUL_VAL_ 2559835902 CommandedVehicleSystem NMControlModeIndicator 0-3, 8-8;
SG_MUL_VAL_ 2559835902 CommandedFunction NMControlModeIndicator 0-3, 8-8;
SG_MUL_VAL_ 2559835902 CommandedFunctionInstance NMControlModeIndicator 0-3, 8-8;
SG_MUL_VAL_ 2559835902 CommandedECUInstance NMControlModeIndicator 0-3, 8-8;
SG_MUL_VAL_ 2559835902 CommandedManufacturerCode NMControlModeIndicator 0-3, 8-8;
SG_MUL_VAL_ 2559835902 AACQualifierFlag NMControlModeIndicator 0-0, 4-4, 8-8;
SG_MUL_VAL_ 2559835902 IndustryGroupQualifierFlag NMControlModeIndicator 0-0, 4-4, 8-8;
SG_MUL_VAL_ 2559835902 VehicleSystemInstanceQualifFlag NMControlModeIndicator 0-0, 4-4, 8-8;
SG_MUL_VAL_ 2559835902 VehicleSystemQualifierFlag NMControlModeIndicator 0-0, 4-4, 8-8;
SG_MUL_VAL_ 2559835902 FunctionQualifierFlag NMControlModeIndicator 0-0, 4-4, 8-8;
SG_MUL_VAL_ 2559835902 FunctionInstanceQualifierFlag NMControlModeIndicator 0-0, 4-4, 8-8;
SG_MUL_VAL_ 2559835902 ECUInstanceQualifierFlag NMControlModeIndicator 0-0, 4-4, 8-8;
SG_MUL_VAL_ 2559835902 ManufacturerCodeQualifierFlag NMControlModeIndicator 0-0, 4-4, 8-8;
